VERSION ""

NS_ :

BS_:

BU_: WRCS SRS LECM3 LECM1 ECUspare6 CMS CIOM CCM AlcoLock2

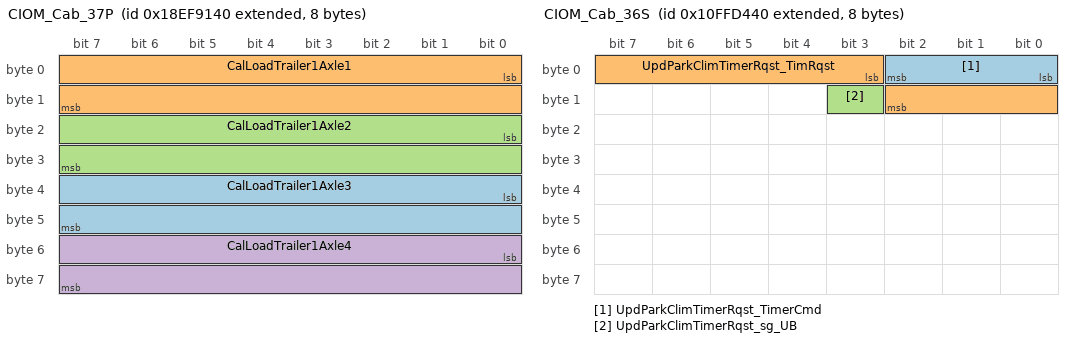
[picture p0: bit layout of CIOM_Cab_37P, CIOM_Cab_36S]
BO_ 2565837120 CIOM_Cab_37P: 8 CIOM
 SG_ CalLoadTrailer1Axle3 : 32|16@1+ (0.5,0) [0|32767.5] "kg"  WRCS
 SG_ CalLoadTrailer1Axle1 : 0|16@1+ (0.5,0) [0|32767.5] "kg"  WRCS
 SG_ CalLoadTrailer1Axle2 : 16|16@1+ (0.5,0) [0|32767.5] "kg"  WRCS
 SG_ CalLoadTrailer1Axle4 : 48|16@1+ (0.5,0) [0|32767.5] "kg"  WRCS

BO_ 2432685120 CIOM_Cab_36S: 8 CIOM
 SG_ UpdParkClimTimerRqst_TimerCmd : 0|3@1+ (1,0) [0|0] ""  CCM
 SG_ UpdParkClimTimerRqst_TimRqst : 3|8@1+ (1,0) [0|0] ""  CCM
 SG_ UpdParkClimTimerRqst_sg_UB : 11|1@1+ (1,0) [0|0] ""  CCM

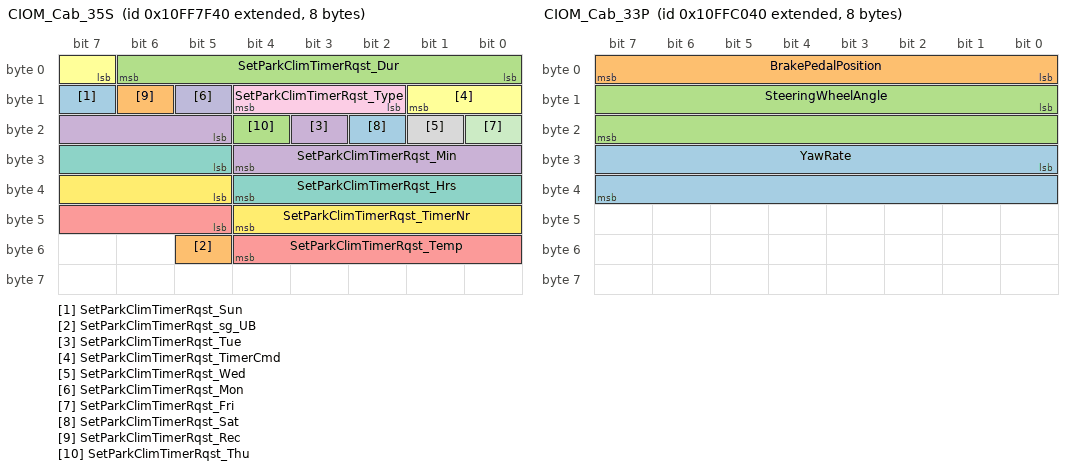
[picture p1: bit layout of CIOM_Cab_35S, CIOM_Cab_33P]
BO_ 2432663360 CIOM_Cab_35S: 8 CIOM
 SG_ SetParkClimTimerRqst_Sun : 15|1@1+ (1,0) [0|0] ""  CCM
 SG_ SetParkClimTimerRqst_sg_UB : 53|1@1+ (1,0) [0|0] ""  CCM
 SG_ SetParkClimTimerRqst_Dur : 0|7@1+ (1,0) [0|127] "min"  CCM
 SG_ SetParkClimTimerRqst_Tue : 19|1@1+ (1,0) [0|0] ""  CCM
 SG_ SetParkClimTimerRqst_Temp : 45|8@1+ (0.5,0) [0|127.5] "DegreeC"  CCM
 SG_ SetParkClimTimerRqst_TimerCmd : 7|3@1+ (1,0) [0|0] ""  CCM
 SG_ SetParkClimTimerRqst_Hrs : 29|8@1+ (1,0) [0|255] "h"  CCM
 SG_ SetParkClimTimerRqst_Wed : 17|1@1+ (1,0) [0|0] ""  CCM
 SG_ SetParkClimTimerRqst_Type : 10|3@1+ (1,0) [0|0] ""  CCM
 SG_ SetParkClimTimerRqst_Mon : 13|1@1+ (1,0) [0|0] ""  CCM
 SG_ SetParkClimTimerRqst_Fri : 16|1@1+ (1,0) [0|0] ""  CCM
 SG_ SetParkClimTimerRqst_TimerNr : 37|8@1+ (1,0) [0|0] ""  CCM
 SG_ SetParkClimTimerRqst_Sat : 18|1@1+ (1,0) [0|0] ""  CCM
 SG_ SetParkClimTimerRqst_Rec : 14|1@1+ (1,0) [0|0] ""  CCM
 SG_ SetParkClimTimerRqst_Thu : 20|1@1+ (1,0) [0|0] ""  CCM
 SG_ SetParkClimTimerRqst_Min : 21|8@1+ (1,0) [0|255] "min"  CCM

BO_ 2566357313 CIOM_Cab_34P_FCM: 8 SRS
 SG_ CIOM_Cab_34P_FCS : 0|64@1+ (1,0) [0|0] ""  CIOM

BO_ 2566357312 CIOM_Cab_34P: 21 CIOM
 SG_ GPSData_VehSpeed : 128|16@1+ (0.00390625,0) [0|255.99609375] "Km_per_h"  SRS
 SG_ GPSData_HDOP : 112|16@1+ (0.01,0) [0|655.35] ""  SRS
 SG_ GPSData_Direction : 96|16@1+ (0.0078125,0) [0|511.9921875] "deg"  SRS
 SG_ GPSData_Longitude : 0|32@1+ (1E-007,-210) [-210|219.4967295] "deg"  SRS
 SG_ GPSData_AntennaStat : 160|3@1+ (1,0) [0|0] ""  SRS
 SG_ GPSData_Latitude : 32|32@1+ (1E-007,-210) [-210|219.4967295] "deg"  SRS
 SG_ GPSData_sg_UB : 163|1@1+ (1,0) [0|1] ""  SRS
 SG_ GPSData_Altitude : 144|16@1+ (0.125,-2500) [-2500|5691.875] "m"  SRS
 SG_ GPSData_Time : 64|32@1+ (1,0) [0|4294967295] "s"  SRS

BO_ 2432680000 CIOM_Cab_33P: 8 CIOM
 SG_ YawRate : 24|16@1+ (0.000122,-3.92) [-3.92|4.07527] "Rad_per_s"  CMS
 SG_ BrakePedalPosition : 0|8@1+ (0.4,0) [0|102] "Percent"  SRS
 SG_ SteeringWheelAngle : 8|16@1+ (0.0009765625,-31.374) [-31.374|32.6250234375] "rad"  CMS,SRS

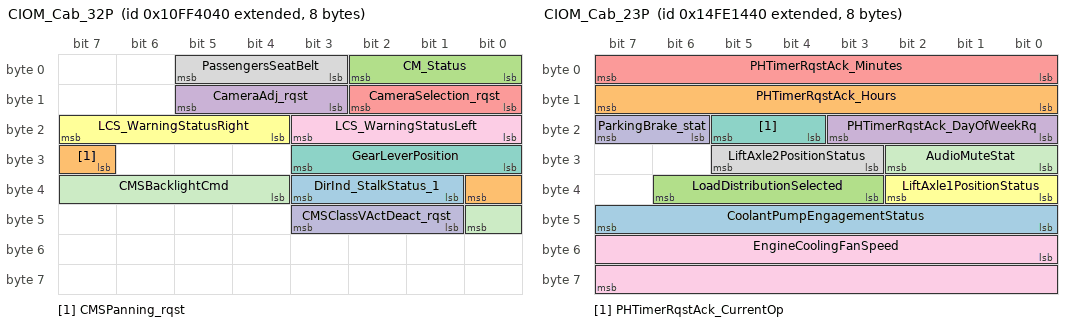
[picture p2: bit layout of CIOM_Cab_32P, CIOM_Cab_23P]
BO_ 2432647232 CIOM_Cab_32P: 8 CIOM
 SG_ DirInd_StalkStatus_1 : 33|3@1+ (1,0) [0|0] ""  CMS
 SG_ CMSPanning_rqst : 31|2@1+ (1,0) [0|0] ""  CMS
 SG_ CM_Status : 0|3@1+ (1,0) [0|0] ""  SRS
 SG_ CameraAdj_rqst : 11|3@1+ (1,0) [0|0] ""  CMS
 SG_ CameraSelection_rqst : 8|3@1+ (1,0) [0|0] ""  CMS
 SG_ LCS_WarningStatusRight : 20|4@1+ (1,0) [0|0] ""  CMS
 SG_ GearLeverPosition : 24|4@1+ (1,0) [0|0] ""  CMS
 SG_ PassengersSeatBelt : 3|3@1+ (1,0) [0|0] ""  SRS
 SG_ LCS_WarningStatusLeft : 16|4@1+ (1,0) [0|0] ""  CMS
 SG_ CMSClassVActDeact_rqst : 41|3@1+ (1,0) [0|0] ""  CMS
 SG_ CMSBacklightCmd : 36|5@1+ (1,0) [0|0] ""  CMS

BO_ 2516193600 CIOM_Cab_31P: 8 CIOM
 SG_ ReqHVILmonitoring : 48|2@1+ (1,0) [0|0] ""  CCM
 SG_ AuxTVSStatus : 56|3@1+ (1,0) [0|0] ""  CCM
 SG_ ActualDrvlnRetdrPercentTorque : 13|8@1+ (1,-125) [-125|130] "Percent"  SRS
 SG_ Trailer2LiftAxle2Pos : 32|2@1+ (1,0) [0|0] ""  WRCS
 SG_ Trailer3LiftAxle2Pos : 36|2@1+ (1,0) [0|0] ""  WRCS
 SG_ ROPBrakeControlActive : 10|2@1+ (1,0) [0|0] ""  SRS
 SG_ TransmissionDrivingMode : 59|3@1+ (1,0) [0|0] ""  CCM
 SG_ Trailer5LiftAxle1Pos : 42|2@1+ (1,0) [0|0] ""  WRCS
 SG_ Trailer1LiftAxle2Pos : 28|2@1+ (1,0) [0|0] ""  WRCS
 SG_ TVSDischargeRequest : 50|2@1+ (1,0) [0|0] ""  CCM
 SG_ FoundationBrakeUse : 8|2@1+ (1,0) [0|0] ""  SRS
 SG_ Trailer4LiftAxle1Pos : 38|2@1+ (1,0) [0|0] ""  WRCS
 SG_ Trailer5LiftAxle2Pos : 44|2@1+ (1,0) [0|0] ""  WRCS
 SG_ BlackPanel_stat : 46|2@1+ (1,0) [0|0] ""  CCM
 SG_ YCBrakeControlActive_UB : 23|1@1+ (1,0) [0|0] ""  SRS
 SG_ Trailer4LiftAxle2Pos : 40|2@1+ (1,0) [0|0] ""  WRCS
 SG_ AntiLockBrakingActive : 24|2@1+ (1,0) [0|0] ""  SRS
 SG_ YCBrakeControlActive : 21|2@1+ (1,0) [0|0] ""  SRS
 SG_ ActualEngineRetarderPercentTrq : 0|8@1+ (1,-125) [-125|130] "Percent"  SRS
 SG_ EngineTmpryStopStartStatus : 52|4@1+ (1,0) [0|0] ""  CCM
 SG_ Trailer1LiftAxle1Pos : 26|2@1+ (1,0) [0|0] ""  WRCS
 SG_ ROPBrakeControlActive_UB : 12|1@1+ (1,0) [0|0] ""  SRS
 SG_ Trailer3LiftAxle1Pos : 34|2@1+ (1,0) [0|0] ""  WRCS
 SG_ Trailer2LiftAxle1Pos : 30|2@1+ (1,0) [0|0] ""  WRCS

BO_ 2566357057 CIOM_Cab_30S_FCM: 8 LECM1
 SG_ CIOM_Cab_30S_FCS : 0|64@1+ (1,0) [0|0] ""  CIOM

BO_ 2566357056 CIOM_Cab_30S: 36 CIOM
 SG_ SEM_DisplayText_stat : 0|288@1+ (1,0) [0|0] ""  LECM1

BO_ 2432679745 CIOM_Cab_29S_FCM: 8 LECM1
 SG_ CIOM_Cab_29S_FCS : 0|64@1+ (1,0) [0|0] ""  CIOM

BO_ 2432679744 CIOM_Cab_29S: 98 CIOM
 SG_ MediaSourcesListRsp_SrcAttrib : 392|384@1+ (1,0) [0|0] ""  LECM1
 SG_ MediaSourcesListRsp_ItemID : 776|4@1+ (1,0) [0|0] ""  LECM1
 SG_ MediaSourcesListRsp_Name : 8|384@1+ (1,0) [0|0] ""  LECM1
 SG_ MediaSourcesListRsp_SInfo : 780|2@1+ (1,0) [0|0] ""  LECM1
 SG_ MediaSourcesListRsp_PCI : 0|8@1+ (1,0) [0|255] ""  LECM1
 SG_ MediaSourcesListRsp_sg_UB : 782|1@1+ (1,0) [0|0] ""  LECM1

BO_ 2432646976 CIOM_Cab_28S: 8 CIOM
 SG_ MediaSourcesListNPRsp : 0|8@1+ (1,0) [0|255] ""  LECM1
 SG_ MediaSourcesListNPRsp_UB : 8|1@1+ (1,0) [0|0] ""  LECM1

BO_ 2493989952 CIOM_Cab_27P: 8 CIOM
 SG_ SEMMediaSourceAvail_Source07 : 7|1@1+ (1,0) [0|0] ""  LECM1
 SG_ SEMMediaSourceAvail_Source06 : 6|1@1+ (1,0) [0|0] ""  LECM1
 SG_ AutoBlowerLevelRqst : 58|3@1+ (1,0) [0|0] ""  CCM
 SG_ SEMMediaSourceAvail_Source08 : 8|1@1+ (1,0) [0|0] ""  LECM1
 SG_ SEMMediaSourceAvail_Source00 : 0|1@1+ (1,0) [0|0] ""  LECM1
 SG_ SEM_AudioMuteStat : 20|3@1+ (1,0) [0|0] ""  LECM1
 SG_ SEMMediaSourceAvail_Source09 : 9|1@1+ (1,0) [0|0] ""  LECM1
 SG_ SEMMediaSourceAvail_Source13 : 13|1@1+ (1,0) [0|0] ""  LECM1
 SG_ SEMMediaSourceAvail_Source04 : 4|1@1+ (1,0) [0|0] ""  LECM1
 SG_ SEMMediaSourceAvail_Source05 : 5|1@1+ (1,0) [0|0] ""  LECM1
 SG_ SEMMediaSourceAvail_Source02 : 2|1@1+ (1,0) [0|0] ""  LECM1
 SG_ SEMMediaSourceAvail_SInfo : 14|2@1+ (1,0) [0|0] ""  LECM1
 SG_ AQSModeRqst : 52|3@1+ (1,0) [0|0] ""  CCM
 SG_ AudioSourceStat : 16|4@1+ (1,0) [0|0] ""  LECM1
 SG_ SEMMediaSourceAvail_Source11 : 11|1@1+ (1,0) [0|0] ""  LECM1
 SG_ SEMMediaSourceAvail_Source10 : 10|1@1+ (1,0) [0|0] ""  LECM1
 SG_ ACModeRqst : 61|3@1+ (1,0) [0|0] ""  CCM
 SG_ ESS_TRDStatus : 35|3@1+ (1,0) [0|0] ""  CCM
 SG_ AutoDefogModeRqst : 49|3@1+ (1,0) [0|0] ""  CCM
 SG_ SEM_AudioVolValIndCmd : 23|6@1+ (1,0) [0|63] "Step"  LECM1
 SG_ SEMMediaSourceAvail_Source01 : 1|1@1+ (1,0) [0|0] ""  LECM1
 SG_ EngineActiveStatus : 38|4@1+ (1,0) [0|0] ""  CCM
 SG_ SEMMediaSourceAvail_Source03 : 3|1@1+ (1,0) [0|0] ""  LECM1
 SG_ SEM_PresetIndicationCmd : 29|6@1+ (1,0) [0|63] "Enumeration"  LECM1
 SG_ SEMMediaSourceAvail_Source12 : 12|1@1+ (1,0) [0|0] ""  LECM1

BO_ 2499754560 CIOM_Cab_26P: 8 CIOM
 SG_ InhibitTVSReq : 58|3@1+ (1,0) [0|0] ""  CCM
 SG_ TipperEmergencyStopStatus : 36|3@1+ (1,0) [0|0] ""  WRCS
 SG_ TipperPrimaryBodyStatus : 40|3@1+ (1,0) [0|0] ""  WRCS
 SG_ TipperConditionsStatus : 2|2@1+ (1,0) [0|0] ""  WRCS
 SG_ TipperSecondaryBodyStatus : 43|3@1+ (1,0) [0|0] ""  WRCS
 SG_ BatterySOCAlert_rqst : 48|3@1+ (1,0) [0|0] ""  WRCS
 SG_ CCStates : 54|4@1+ (1,0) [0|0] ""  SRS
 SG_ ExtraHeating_rqst : 27|3@1+ (1,0) [0|0] ""  CCM
 SG_ LongMotionDirection : 51|3@1+ (1,0) [0|0] ""  SRS
 SG_ TipperUpDownStatus : 10|3@1+ (1,0) [0|0] ""  WRCS
 SG_ TipperTailGateStatus : 13|3@1+ (1,0) [0|0] ""  WRCS
 SG_ KneelingInformation : 32|4@1+ (1,0) [0|0] ""  WRCS
 SG_ TailLiftRemoteNotAllowed : 6|2@1+ (1,0) [0|0] ""  WRCS
 SG_ DirectionIndicatorActive_stat : 61|3@1+ (1,0) [0|0] ""  CMS
 SG_ TipperTarpaulinStatus : 16|3@1+ (1,0) [0|0] ""  WRCS
 SG_ TailLiftConditionsStatus : 4|2@1+ (1,0) [0|0] ""  WRCS
 SG_ InhibitWRCECSMenuCmd : 8|2@1+ (1,0) [0|0] ""  WRCS
 SG_ ShortStopHeater_status : 24|3@1+ (1,0) [0|0] ""  CCM
 SG_ LongMotionDirectionQual : 22|2@1+ (1,0) [0|0] ""  SRS
 SG_ TipperShakerStatus : 0|2@1+ (1,0) [0|0] ""  WRCS
 SG_ TailLiftMotionStatus : 19|3@1+ (1,0) [0|0] ""  WRCS

BO_ 2499679296 CIOM_Cab_23P: 8 CIOM
 SG_ CoolantPumpEngagementStatus : 40|8@1+ (0.4,0) [0|102] "Percent"  CCM
 SG_ PHTimerRqstAck_Hours : 8|8@1+ (1,0) [0|255] "h"  CCM
 SG_ LoadDistributionSelected : 35|4@1+ (1,0) [0|0] ""  WRCS
 SG_ PHTimerRqstAck_DayOfWeekRq : 16|4@1+ (1,0) [0|0] ""  CCM
 SG_ PHTimerRqstAck_Minutes : 0|8@1+ (1,0) [0|255] "min"  CCM
 SG_ LiftAxle1PositionStatus : 32|3@1+ (1,0) [0|0] ""  WRCS
 SG_ PHTimerRqstAck_CurrentOp : 20|2@1+ (1,0) [0|0] ""  CCM
 SG_ LiftAxle2PositionStatus : 27|3@1+ (1,0) [0|0] ""  WRCS
 SG_ EngineCoolingFanSpeed : 48|16@1+ (1,0) [0|65535] "rpm"  CCM
 SG_ ParkingBrake_stat : 22|2@1+ (1,0) [0|0] ""  WRCS
 SG_ AudioMuteStat : 24|3@1+ (1,0) [0|0] ""  LECM3,LECM1

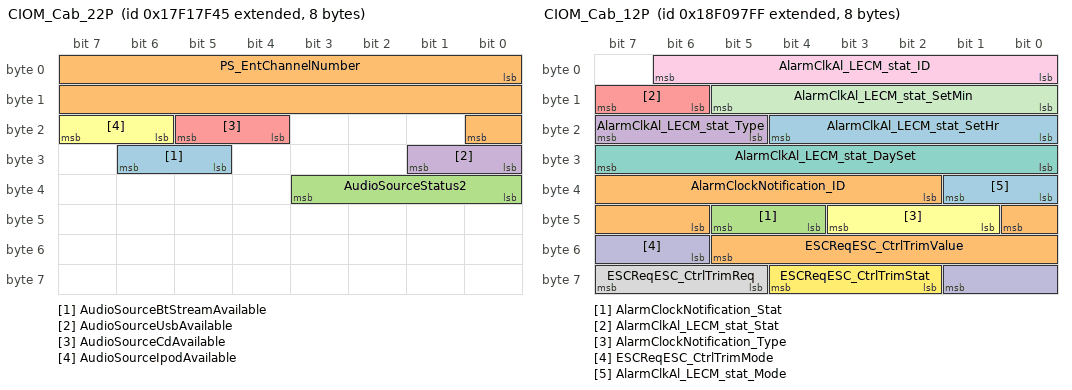
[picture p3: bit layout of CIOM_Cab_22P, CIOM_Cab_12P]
BO_ 2549186373 CIOM_Cab_22P: 8 CIOM
 SG_ AudioSourceBtStreamAvailable : 29|2@1+ (1,0) [0|0] ""  LECM1
 SG_ PS_EntChannelNumber : 0|17@1+ (1,0) [0|131071] "Not Available"  LECM3
 SG_ AudioSourceStatus2 : 32|4@1+ (1,0) [0|0] ""  LECM1
 SG_ AudioSourceUsbAvailable : 24|2@1+ (1,0) [0|0] ""  LECM1
 SG_ AudioSourceCdAvailable : 20|2@1+ (1,0) [0|0] ""  LECM1
 SG_ AudioSourceIpodAvailable : 22|2@1+ (1,0) [0|0] ""  LECM1

BO_ 2566864832 CIOM_Cab_20S_FCM: 8 LECM1
 SG_ CIOM_Cab_20S_FCS : 0|64@1+ (1,0) [0|0] ""  CIOM

BO_ 2566864831 CIOM_Cab_20S: 36 CIOM
 SG_ DisplayText_stat : 0|288@1+ (1,0) [0|0] ""  LECM1

BO_ 2565974016 CIOM_Cab_13S_FCM: 8 WRCS
 SG_ CIOM_Cab_13S_FCS : 0|64@1+ (1,0) [0|0] ""  CIOM

BO_ 2565974015 CIOM_Cab_13S: 128 CIOM
 SG_ FdEquipmentFreeText : 0|1024@1+ (1,0) [0|0] ""  WRCS

BO_ 2565904383 CIOM_Cab_12P: 8 CIOM
 SG_ AlarmClkAl_LECM_stat_SetHr : 16|5@1+ (1,0) [0|31] "h"  LECM1
 SG_ ESCReqESC_CtrlTrimValue : 46|8@1+ (10,0) [0|2550] ""  WRCS
 SG_ AlarmClockNotification_Stat : 44|2@1+ (1,0) [0|0] ""  LECM1
 SG_ AlarmClkAl_LECM_stat_Type : 21|3@1+ (1,0) [0|0] ""  LECM1
 SG_ AlarmClkAl_LECM_stat_Stat : 14|2@1+ (1,0) [0|0] ""  LECM1
 SG_ AlarmClockNotification_Type : 41|3@1+ (1,0) [0|0] ""  LECM1
 SG_ AlarmClkAl_LECM_stat_DaySet : 24|8@1+ (1,0) [0|255] ""  LECM1
 SG_ ESCReqESC_CtrlTrimReq : 61|3@1+ (1,0) [0|0] ""  WRCS
 SG_ AlarmClkAl_LECM_stat_ID : 0|7@1+ (1,0) [0|0] ""  LECM1
 SG_ ESCReqESC_CtrlTrimMode : 54|4@1+ (1,0) [0|0] ""  WRCS
 SG_ AlarmClkAl_LECM_stat_SetMin : 8|6@1+ (1,0) [0|63] "min"  LECM1
 SG_ ESCReqESC_CtrlTrimStat : 58|3@1+ (1,0) [0|0] ""  WRCS
 SG_ AlarmClkAl_LECM_stat_Mode : 32|2@1+ (1,0) [0|0] ""  LECM1
 SG_ AlarmClockNotification_ID : 34|7@1+ (1,0) [0|0] ""  LECM1

BO_ 2565834752 CIOM_Cab_11S_FCM: 8 SRS
 SG_ CIOM_Cab_11S_FCS : 0|64@1+ (1,0) [0|0] ""  CIOM

BO_ 2565834751 CIOM_Cab_11S: 11 CIOM
 SG_ ECUVIN_stat : 0|88@1+ (1,0) [0|0] ""  SRS

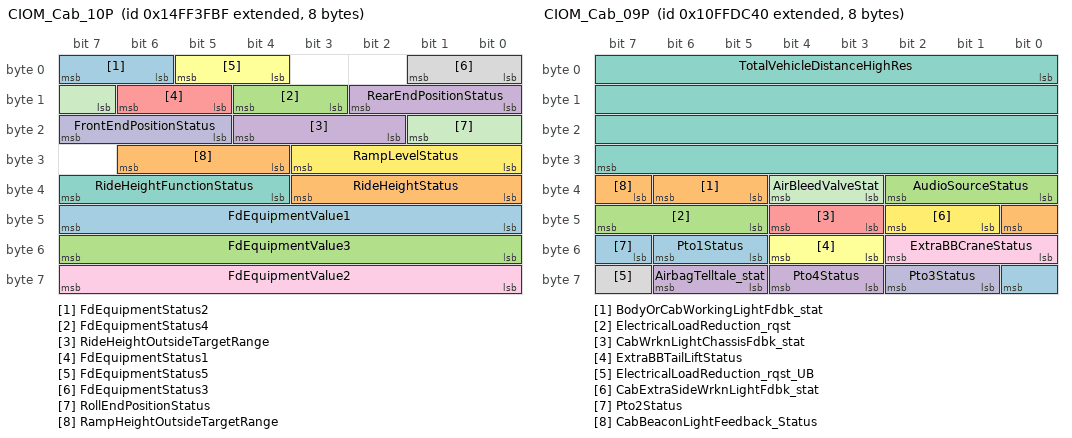
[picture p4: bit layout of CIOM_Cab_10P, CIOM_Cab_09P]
BO_ 2499755967 CIOM_Cab_10P: 8 CIOM
 SG_ FdEquipmentStatus2 : 6|2@1+ (1,0) [0|0] ""  WRCS
 SG_ RideHeightStatus : 32|4@1+ (1,0) [0|0] ""  WRCS
 SG_ FdEquipmentStatus4 : 11|2@1+ (1,0) [0|0] ""  WRCS
 SG_ RideHeightOutsideTargetRange : 18|3@1+ (1,0) [0|0] ""  WRCS
 SG_ FdEquipmentStatus1 : 13|2@1+ (1,0) [0|0] ""  WRCS
 SG_ FdEquipmentStatus5 : 4|2@1+ (1,0) [0|0] ""  WRCS
 SG_ RideHeightFunctionStatus : 36|4@1+ (1,0) [0|0] ""  WRCS
 SG_ FdEquipmentStatus3 : 0|2@1+ (1,0) [0|0] ""  WRCS
 SG_ FdEquipmentValue2 : 56|8@1+ (0.5,0) [0|127.5] "Percent"  WRCS
 SG_ FrontEndPositionStatus : 21|3@1+ (1,0) [0|0] ""  WRCS
 SG_ RollEndPositionStatus : 15|3@1+ (1,0) [0|0] ""  WRCS
 SG_ RampLevelStatus : 24|4@1+ (1,0) [0|0] ""  WRCS
 SG_ FdEquipmentValue1 : 40|8@1+ (0.5,0) [0|127.5] "Percent"  WRCS
 SG_ RampHeightOutsideTargetRange : 28|3@1+ (1,0) [0|0] ""  WRCS
 SG_ FdEquipmentValue3 : 48|8@1+ (0.5,0) [0|127.5] "Percent"  WRCS
 SG_ RearEndPositionStatus : 8|3@1+ (1,0) [0|0] ""  WRCS

BO_ 2432687168 CIOM_Cab_09P: 8 CIOM
 SG_ Pto1Status : 53|2@1+ (1,0) [0|0] ""  WRCS
 SG_ BodyOrCabWorkingLightFdbk_stat : 37|2@1+ (1,0) [0|0] ""  WRCS
 SG_ ElectricalLoadReduction_rqst : 45|3@1+ (1,0) [0|0] ""  CCM,WRCS
 SG_ AirbagTelltale_stat : 61|2@1+ (1,0) [0|0] ""  SRS
 SG_ CabWrknLightChassisFdbk_stat : 43|2@1+ (1,0) [0|0] ""  WRCS
 SG_ ExtraBBTailLiftStatus : 51|2@1+ (1,0) [0|0] ""  WRCS
 SG_ TotalVehicleDistanceHighRes : 0|32@1+ (5,0) [0|21474836475] "m"  LECM3,CMS,SRS,LECM1,WRCS,CCM
 SG_ ElectricalLoadReduction_rqst_UB : 63|1@1+ (1,0) [0|0] ""  CCM,WRCS
 SG_ ExtraBBCraneStatus : 48|3@1+ (1,0) [0|0] ""  WRCS
 SG_ Pto3Status : 57|2@1+ (1,0) [0|0] ""  WRCS
 SG_ AirBleedValveStat : 35|2@1+ (1,0) [0|0] ""  CCM
 SG_ CabExtraSideWrknLightFdbk_stat : 41|2@1+ (1,0) [0|0] ""  WRCS
 SG_ Pto2Status : 55|2@1+ (1,0) [0|0] ""  WRCS
 SG_ CabBeaconLightFeedback_Status : 39|2@1+ (1,0) [0|0] ""  WRCS
 SG_ AudioSourceStatus : 32|3@1+ (1,0) [0|0] ""  LECM1
 SG_ Pto4Status : 59|2@1+ (1,0) [0|0] ""  WRCS

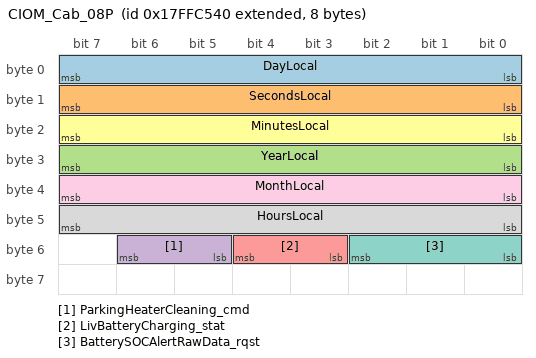
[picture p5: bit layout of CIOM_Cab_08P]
BO_ 2550121792 CIOM_Cab_08P: 8 CIOM
 SG_ DayLocal : 0|8@1+ (0.25,0) [0|63.75] "Days"  CCM
 SG_ SecondsLocal : 8|8@1+ (0.25,0) [0|63.75] "s"  CCM
 SG_ YearLocal : 24|8@1+ (1,1985) [1985|2240] "Years"  CCM
 SG_ ParkingHeaterCleaning_cmd : 53|2@1+ (1,0) [0|0] ""  CCM
 SG_ LivBatteryCharging_stat : 51|2@1+ (1,0) [0|0] ""  CCM
 SG_ MinutesLocal : 16|8@1+ (1,0) [0|255] "min"  CCM,LECM1
 SG_ BatterySOCAlertRawData_rqst : 48|3@1+ (1,0) [0|0] ""  CCM
 SG_ HoursLocal : 40|8@1+ (1,0) [0|255] "h"  CCM,LECM1
 SG_ MonthLocal : 32|8@1+ (1,0) [0|255] "Months"  CCM

CM_ SG_ 2565837120 CalLoadTrailer1Axle3 "65024 - 65279 Error ; 65280 - 65535 Not available";
CM_ SG_ 2565837120 CalLoadTrailer1Axle1 "65024 - 65279 Error ; 65280 - 65535 Not available";
CM_ SG_ 2565837120 CalLoadTrailer1Axle2 "65024 - 65279 Error ; 65280 - 65535 Not available";
CM_ SG_ 2565837120 CalLoadTrailer1Axle4 "65024 - 65279 Error ; 65280 - 65535 Not available";
CM_ SG_ 2566357312 GPSData_VehSpeed "65024 - 65279 Error ; 65280 - 65535 Not available";
CM_ SG_ 2566357312 GPSData_Longitude "4261412864-4278190079 Error ; 4278190080-4294967295 Not available";
CM_ SG_ 2566357312 GPSData_Latitude "4261412864-4278190079 Error ; 4278190080-4294967295 Not available";
CM_ SG_ 2566357312 GPSData_Time "4261412864 - 4278190079 Error ; 4278190080 - 4294967295 Not available";
CM_ SG_ 2432680000 YawRate "65024 - 65279 Error ; 65280 - 65535 Not available";
CM_ SG_ 2432680000 BrakePedalPosition "254 Error ; 255 Not available";
CM_ SG_ 2432680000 SteeringWheelAngle "65024 - 65279 Error ; 65280 - 65535 Not available";
CM_ SG_ 2516193600 ActualDrvlnRetdrPercentTorque "254 Error ; 255 Not available";
CM_ SG_ 2516193600 ActualEngineRetarderPercentTrq "254 Error ; 255 Not available";
CM_ SG_ 2565904383 ESCReqESC_CtrlTrimValue "254 Error ; 255 Not available";
CM_ SG_ 2499755967 FdEquipmentValue2 "254 Error ; 255 Not available";
CM_ SG_ 2499755967 FdEquipmentValue1 "254 Error ; 255 Not available";
CM_ SG_ 2499755967 FdEquipmentValue3 "254 Error ; 255 Not available";
CM_ SG_ 2432687168 TotalVehicleDistanceHighRes "4261412864 - 4278190079 Error ; 4278190080 - 4294967295 Not available";
CM_ SG_ 2550121792 DayLocal "254 Error ; 255 Not available";
CM_ SG_ 2550121792 SecondsLocal "254 Error ; 255 Not available";
CM_ SG_ 2550121792 YearLocal "254 Error ; 255 Not available";
CM_ SG_ 2550121792 MinutesLocal "254 Error ; 255 Not available";
CM_ SG_ 2550121792 HoursLocal "254 Error ; 255 Not available";
CM_ SG_ 2550121792 MonthLocal "254 Error ; 255 Not available";
BA_DEF_ BO_  "GenMsgStartDelayTime" INT 0 0;
BA_DEF_ BO_  "GenMsgDelayTime" INT 0 0;
BA_DEF_ BO_  "GenMsgCycleTime" INT 0 0;
BA_DEF_ BO_  "GenMsgSendType" ENUM  "Cyclic","NotUsed","NotUsed","NotUsed","NotUsed","NotUsed","NotUsed","IfActive","NoMsgSendType","NotUsed";
BA_DEF_ SG_  "GenSigStartValue" INT 0 0;
BA_DEF_ SG_  "GenSigCycleTimeActive" INT 0 0;
BA_DEF_ SG_  "GenSigCycleTime" INT 0 0;
BA_DEF_ SG_  "GenSigSendType" ENUM  "Cyclic","OnWrite","OnWriteWithRepetition","OnChange","OnChangeWithRepetition","IfActive","IfActiveWithRepetition","NoSigSendType","NotUsed","NotUsed","NotUsed","NotUsed","NotUsed";
BA_DEF_ BO_  "VFrameFormat" ENUM  "StandardCAN","ExtendedCAN","reserved","J1939PG","reserved","reserved","reserved","reserved","reserved","reserved","reserved","reserved","reserved","reserved","StandardCAN_FD","ExtendedCAN_FD";
BA_DEF_ SG_  "SigType" ENUM  "Default","Range","RangeSigned","ASCII","Discrete","Control","ReferencePGN","DTC","StringDelimiter","StringLength","StringLengthControl";
BA_DEF_ SG_  "SeToolVersion_SIGNAL" STRING ;
BA_DEF_ SG_  "SeToolUniqueID_SIGNAL" STRING ;
BA_DEF_ SG_  "SeToolOwnerSigGroup_SIGNAL" STRING ;
BA_DEF_ SG_  "SeToolOwnerSigGroupID_SIGNAL" STRING ;
BA_DEF_ SG_  "SeToolName_SIGNAL" STRING ;
BA_DEF_ SG_  "SeToolItemID_SIGNAL" STRING ;
BA_DEF_ SG_  "SeToolAncestorID_SIGNAL" STRING ;
BA_DEF_ SG_  "Platform_VMCU1_Sig" ENUM  "No","Yes";
BA_DEF_ BO_  "NmAsrMessage" ENUM  "No","Yes";
BA_DEF_ SG_  "NeedsUpdateBit" ENUM  "No","Yes";
BA_DEF_ SG_  "MmAnSignal" ENUM  "No","Yes";
BA_DEF_ SG_  "GenSigMaxLatency" INT 0 65535;
BA_DEF_ SG_  "GenSigILSupport" ENUM  "Yes","No";
BA_DEF_ BO_  "GenMsgILSupport" ENUM  "No","Yes";
BA_DEF_ SG_  "E2EProfile" STRING ;
BA_DEF_ SG_  "E2EDataLength" INT 0 65535;
BA_DEF_ SG_  "E2EDataId" INT 0 65535;
BA_DEF_ BO_  "DiagUUDTResponse" ENUM  "No","Yes";
BA_DEF_ BO_  "DiagState" ENUM  "No","Yes";
BA_DEF_ BO_  "DiagResponse" ENUM  "No","Yes";
BA_DEF_ BO_  "DiagRequest" ENUM  "No","Yes";
BA_DEF_ BO_  "DiagConnection" HEX 0 65535;
BA_DEF_ BO_  "CanTpSTmin" INT 0 255;
BA_DEF_ BO_  "CanTpFcFrameId" HEX 0 2147483647;
BA_DEF_ BO_  "CanTpBs" INT 0 255;
BA_DEF_REL_ BU_SG_REL_  "GenSigTimeoutTime" INT 0 65535;
BA_DEF_REL_ BU_SG_REL_  "GenSigFirstTimeoutTime" INT 0 65535;
BA_DEF_DEF_  "GenMsgStartDelayTime" 0;
BA_DEF_DEF_  "GenMsgDelayTime" 0;
BA_DEF_DEF_  "GenMsgCycleTime" 0;
BA_DEF_DEF_  "GenMsgSendType" "Cyclic";
BA_DEF_DEF_  "GenSigStartValue" 0;
BA_DEF_DEF_  "GenSigCycleTimeActive" 0;
BA_DEF_DEF_  "GenSigCycleTime" 0;
BA_DEF_DEF_  "GenSigSendType" "Cyclic";
BA_DEF_DEF_  "VFrameFormat" "ExtendedCAN";
BA_DEF_DEF_  "SigType" "Default";
BA_DEF_DEF_  "SeToolVersion_SIGNAL" "";
BA_DEF_DEF_  "SeToolUniqueID_SIGNAL" "";
BA_DEF_DEF_  "SeToolOwnerSigGroup_SIGNAL" "";
BA_DEF_DEF_  "SeToolOwnerSigGroupID_SIGNAL" "";
BA_DEF_DEF_  "SeToolName_SIGNAL" "";
BA_DEF_DEF_  "SeToolItemID_SIGNAL" "";
BA_DEF_DEF_  "SeToolAncestorID_SIGNAL" "";
BA_DEF_DEF_  "Platform_VMCU1_Sig" "No";
BA_DEF_DEF_  "NmAsrMessage" "No";
BA_DEF_DEF_  "NeedsUpdateBit" "No";
BA_DEF_DEF_  "MmAnSignal" "No";
BA_DEF_DEF_  "GenSigMaxLatency" 0;
BA_DEF_DEF_  "GenSigILSupport" "Yes";
BA_DEF_DEF_  "GenMsgILSupport" "Yes";
BA_DEF_DEF_  "E2EProfile" "none";
BA_DEF_DEF_  "E2EDataLength" 0;
BA_DEF_DEF_  "E2EDataId" 0;
BA_DEF_DEF_  "DiagUUDTResponse" "No";
BA_DEF_DEF_  "DiagState" "No";
BA_DEF_DEF_  "DiagResponse" "No";
BA_DEF_DEF_  "DiagRequest" "No";
BA_DEF_DEF_  "DiagConnection" 0;
BA_DEF_DEF_  "CanTpSTmin" 0;
BA_DEF_DEF_  "CanTpFcFrameId" 2147483647;
BA_DEF_DEF_  "CanTpBs" 255;
BA_DEF_DEF_REL_ "GenSigTimeoutTime" 0;
BA_DEF_DEF_REL_ "GenSigFirstTimeoutTime" 0;
BA_ "GenMsgCycleTime" BO_ 2565837120 1000;
BA_ "GenMsgStartDelayTime" BO_ 2565837120 20;
BA_ "GenMsgSendType" BO_ 2432685120 8;
BA_ "GenMsgDelayTime" BO_ 2432685120 20;
BA_ "GenMsgSendType" BO_ 2432663360 8;
BA_ "GenMsgDelayTime" BO_ 2432663360 20;
BA_ "GenMsgILSupport" BO_ 2566357313 0;
BA_ "GenMsgSendType" BO_ 2566357313 8;
BA_ "CanTpFcFrameId" BO_ 2566357312 418873665;
BA_ "GenMsgCycleTime" BO_ 2566357312 500;
BA_ "GenMsgStartDelayTime" BO_ 2566357312 50;
BA_ "GenMsgCycleTime" BO_ 2432680000 10;
BA_ "GenMsgStartDelayTime" BO_ 2432680000 5;
BA_ "GenMsgCycleTime" BO_ 2432647232 20;
BA_ "GenMsgCycleTime" BO_ 2516193600 100;
BA_ "GenMsgILSupport" BO_ 2566357057 0;
BA_ "GenMsgSendType" BO_ 2566357057 8;
BA_ "CanTpFcFrameId" BO_ 2566357056 418873409;
BA_ "GenMsgSendType" BO_ 2566357056 8;
BA_ "GenMsgDelayTime" BO_ 2566357056 150;
BA_ "GenMsgILSupport" BO_ 2432679745 0;
BA_ "GenMsgSendType" BO_ 2432679745 8;
BA_ "CanTpFcFrameId" BO_ 2432679744 285196097;
BA_ "GenMsgSendType" BO_ 2432679744 8;
BA_ "GenMsgDelayTime" BO_ 2432679744 50;
BA_ "GenMsgSendType" BO_ 2432646976 8;
BA_ "GenMsgDelayTime" BO_ 2432646976 20;
BA_ "GenMsgCycleTime" BO_ 2493989952 50;
BA_ "GenMsgStartDelayTime" BO_ 2493989952 25;
BA_ "GenMsgCycleTime" BO_ 2499754560 50;
BA_ "GenMsgCycleTime" BO_ 2499679296 50;
BA_ "GenMsgStartDelayTime" BO_ 2499679296 10;
BA_ "GenMsgCycleTime" BO_ 2549186373 150;
BA_ "GenMsgStartDelayTime" BO_ 2549186373 15;
BA_ "GenMsgILSupport" BO_ 2566864832 0;
BA_ "GenMsgSendType" BO_ 2566864832 8;
BA_ "CanTpFcFrameId" BO_ 2566864831 419381184;
BA_ "GenMsgSendType" BO_ 2566864831 8;
BA_ "GenMsgDelayTime" BO_ 2566864831 200;
BA_ "GenMsgStartDelayTime" BO_ 2566864831 50;
BA_ "GenMsgILSupport" BO_ 2565974016 0;
BA_ "GenMsgSendType" BO_ 2565974016 8;
BA_ "CanTpFcFrameId" BO_ 2565974015 418490368;
BA_ "GenMsgSendType" BO_ 2565974015 8;
BA_ "GenMsgDelayTime" BO_ 2565974015 200;
BA_ "GenMsgCycleTime" BO_ 2565904383 150;
BA_ "GenMsgStartDelayTime" BO_ 2565904383 75;
BA_ "CanTpSTmin" BO_ 2565834752 1;
BA_ "GenMsgILSupport" BO_ 2565834752 0;
BA_ "GenMsgSendType" BO_ 2565834752 8;
BA_ "CanTpFcFrameId" BO_ 2565834751 418351104;
BA_ "CanTpSTmin" BO_ 2565834751 5;
BA_ "GenMsgSendType" BO_ 2565834751 8;
BA_ "GenMsgDelayTime" BO_ 2565834751 100;
BA_ "GenMsgCycleTime" BO_ 2499755967 50;
BA_ "GenMsgStartDelayTime" BO_ 2499755967 5;
BA_ "GenMsgCycleTime" BO_ 2432687168 20;
BA_ "GenMsgStartDelayTime" BO_ 2432687168 5;
BA_ "GenMsgCycleTime" BO_ 2550121792 250;
BA_ "GenMsgStartDelayTime" BO_ 2550121792 25;
BA_ "GenSigCycleTime" SG_ 2565837120 CalLoadTrailer1Axle3 100;
BA_ "GenSigCycleTimeActive" SG_ 2565837120 CalLoadTrailer1Axle3 100;
BA_ "GenSigStartValue" SG_ 2565837120 CalLoadTrailer1Axle3 65535;
BA_ "GenSigMaxLatency" SG_ 2565837120 CalLoadTrailer1Axle3 1001;
BA_ "GenSigCycleTime" SG_ 2565837120 CalLoadTrailer1Axle1 100;
BA_ "GenSigCycleTimeActive" SG_ 2565837120 CalLoadTrailer1Axle1 100;
BA_ "GenSigStartValue" SG_ 2565837120 CalLoadTrailer1Axle1 65535;
BA_ "GenSigMaxLatency" SG_ 2565837120 CalLoadTrailer1Axle1 1001;
BA_ "GenSigCycleTime" SG_ 2565837120 CalLoadTrailer1Axle2 100;
BA_ "GenSigCycleTimeActive" SG_ 2565837120 CalLoadTrailer1Axle2 100;
BA_ "GenSigStartValue" SG_ 2565837120 CalLoadTrailer1Axle2 65535;
BA_ "GenSigMaxLatency" SG_ 2565837120 CalLoadTrailer1Axle2 1001;
BA_ "GenSigCycleTime" SG_ 2565837120 CalLoadTrailer1Axle4 100;
BA_ "GenSigCycleTimeActive" SG_ 2565837120 CalLoadTrailer1Axle4 100;
BA_ "GenSigStartValue" SG_ 2565837120 CalLoadTrailer1Axle4 65535;
BA_ "GenSigMaxLatency" SG_ 2565837120 CalLoadTrailer1Axle4 1001;
BA_ "GenSigSendType" SG_ 2432685120 UpdParkClimTimerRqst_TimerCmd 1;
BA_ "GenSigCycleTime" SG_ 2432685120 UpdParkClimTimerRqst_TimerCmd 100;
BA_ "GenSigCycleTimeActive" SG_ 2432685120 UpdParkClimTimerRqst_TimerCmd 100;
BA_ "GenSigStartValue" SG_ 2432685120 UpdParkClimTimerRqst_TimerCmd 7;
BA_ "GenSigMaxLatency" SG_ 2432685120 UpdParkClimTimerRqst_TimerCmd 20;
BA_ "NeedsUpdateBit" SG_ 2432685120 UpdParkClimTimerRqst_TimerCmd 1;
BA_ "GenSigSendType" SG_ 2432685120 UpdParkClimTimerRqst_TimRqst 1;
BA_ "GenSigCycleTime" SG_ 2432685120 UpdParkClimTimerRqst_TimRqst 100;
BA_ "GenSigCycleTimeActive" SG_ 2432685120 UpdParkClimTimerRqst_TimRqst 100;
BA_ "GenSigStartValue" SG_ 2432685120 UpdParkClimTimerRqst_TimRqst 255;
BA_ "GenSigMaxLatency" SG_ 2432685120 UpdParkClimTimerRqst_TimRqst 20;
BA_ "NeedsUpdateBit" SG_ 2432685120 UpdParkClimTimerRqst_TimRqst 1;
BA_ "GenSigSendType" SG_ 2432685120 UpdParkClimTimerRqst_sg_UB 7;
BA_ "GenSigSendType" SG_ 2432663360 SetParkClimTimerRqst_Sun 1;
BA_ "GenSigCycleTime" SG_ 2432663360 SetParkClimTimerRqst_Sun 100;
BA_ "GenSigCycleTimeActive" SG_ 2432663360 SetParkClimTimerRqst_Sun 100;
BA_ "GenSigMaxLatency" SG_ 2432663360 SetParkClimTimerRqst_Sun 20;
BA_ "NeedsUpdateBit" SG_ 2432663360 SetParkClimTimerRqst_Sun 1;
BA_ "GenSigSendType" SG_ 2432663360 SetParkClimTimerRqst_sg_UB 7;
BA_ "GenSigSendType" SG_ 2432663360 SetParkClimTimerRqst_Dur 1;
BA_ "GenSigCycleTime" SG_ 2432663360 SetParkClimTimerRqst_Dur 100;
BA_ "GenSigCycleTimeActive" SG_ 2432663360 SetParkClimTimerRqst_Dur 100;
BA_ "GenSigStartValue" SG_ 2432663360 SetParkClimTimerRqst_Dur 127;
BA_ "GenSigMaxLatency" SG_ 2432663360 SetParkClimTimerRqst_Dur 20;
BA_ "NeedsUpdateBit" SG_ 2432663360 SetParkClimTimerRqst_Dur 1;
BA_ "GenSigSendType" SG_ 2432663360 SetParkClimTimerRqst_Tue 1;
BA_ "GenSigCycleTime" SG_ 2432663360 SetParkClimTimerRqst_Tue 100;
BA_ "GenSigCycleTimeActive" SG_ 2432663360 SetParkClimTimerRqst_Tue 100;
BA_ "GenSigMaxLatency" SG_ 2432663360 SetParkClimTimerRqst_Tue 20;
BA_ "NeedsUpdateBit" SG_ 2432663360 SetParkClimTimerRqst_Tue 1;
BA_ "GenSigSendType" SG_ 2432663360 SetParkClimTimerRqst_Temp 1;
BA_ "GenSigCycleTime" SG_ 2432663360 SetParkClimTimerRqst_Temp 100;
BA_ "GenSigCycleTimeActive" SG_ 2432663360 SetParkClimTimerRqst_Temp 100;
BA_ "GenSigStartValue" SG_ 2432663360 SetParkClimTimerRqst_Temp 255;
BA_ "GenSigMaxLatency" SG_ 2432663360 SetParkClimTimerRqst_Temp 20;
BA_ "NeedsUpdateBit" SG_ 2432663360 SetParkClimTimerRqst_Temp 1;
BA_ "GenSigSendType" SG_ 2432663360 SetParkClimTimerRqst_TimerCmd 1;
BA_ "GenSigCycleTime" SG_ 2432663360 SetParkClimTimerRqst_TimerCmd 100;
BA_ "GenSigCycleTimeActive" SG_ 2432663360 SetParkClimTimerRqst_TimerCmd 100;
BA_ "GenSigStartValue" SG_ 2432663360 SetParkClimTimerRqst_TimerCmd 7;
BA_ "GenSigMaxLatency" SG_ 2432663360 SetParkClimTimerRqst_TimerCmd 20;
BA_ "NeedsUpdateBit" SG_ 2432663360 SetParkClimTimerRqst_TimerCmd 1;
BA_ "GenSigSendType" SG_ 2432663360 SetParkClimTimerRqst_Hrs 1;
BA_ "GenSigCycleTime" SG_ 2432663360 SetParkClimTimerRqst_Hrs 100;
BA_ "GenSigCycleTimeActive" SG_ 2432663360 SetParkClimTimerRqst_Hrs 100;
BA_ "GenSigStartValue" SG_ 2432663360 SetParkClimTimerRqst_Hrs 255;
BA_ "GenSigMaxLatency" SG_ 2432663360 SetParkClimTimerRqst_Hrs 20;
BA_ "NeedsUpdateBit" SG_ 2432663360 SetParkClimTimerRqst_Hrs 1;
BA_ "GenSigSendType" SG_ 2432663360 SetParkClimTimerRqst_Wed 1;
BA_ "GenSigCycleTime" SG_ 2432663360 SetParkClimTimerRqst_Wed 100;
BA_ "GenSigCycleTimeActive" SG_ 2432663360 SetParkClimTimerRqst_Wed 100;
BA_ "GenSigMaxLatency" SG_ 2432663360 SetParkClimTimerRqst_Wed 20;
BA_ "NeedsUpdateBit" SG_ 2432663360 SetParkClimTimerRqst_Wed 1;
BA_ "GenSigSendType" SG_ 2432663360 SetParkClimTimerRqst_Type 1;
BA_ "GenSigCycleTime" SG_ 2432663360 SetParkClimTimerRqst_Type 100;
BA_ "GenSigCycleTimeActive" SG_ 2432663360 SetParkClimTimerRqst_Type 100;
BA_ "GenSigStartValue" SG_ 2432663360 SetParkClimTimerRqst_Type 7;
BA_ "GenSigMaxLatency" SG_ 2432663360 SetParkClimTimerRqst_Type 20;
BA_ "NeedsUpdateBit" SG_ 2432663360 SetParkClimTimerRqst_Type 1;
BA_ "GenSigSendType" SG_ 2432663360 SetParkClimTimerRqst_Mon 1;
BA_ "GenSigCycleTime" SG_ 2432663360 SetParkClimTimerRqst_Mon 100;
BA_ "GenSigCycleTimeActive" SG_ 2432663360 SetParkClimTimerRqst_Mon 100;
BA_ "GenSigMaxLatency" SG_ 2432663360 SetParkClimTimerRqst_Mon 20;
BA_ "NeedsUpdateBit" SG_ 2432663360 SetParkClimTimerRqst_Mon 1;
BA_ "GenSigSendType" SG_ 2432663360 SetParkClimTimerRqst_Fri 1;
BA_ "GenSigCycleTime" SG_ 2432663360 SetParkClimTimerRqst_Fri 100;
BA_ "GenSigCycleTimeActive" SG_ 2432663360 SetParkClimTimerRqst_Fri 100;
BA_ "GenSigMaxLatency" SG_ 2432663360 SetParkClimTimerRqst_Fri 20;
BA_ "NeedsUpdateBit" SG_ 2432663360 SetParkClimTimerRqst_Fri 1;
BA_ "GenSigSendType" SG_ 2432663360 SetParkClimTimerRqst_TimerNr 1;
BA_ "GenSigCycleTime" SG_ 2432663360 SetParkClimTimerRqst_TimerNr 100;
BA_ "GenSigCycleTimeActive" SG_ 2432663360 SetParkClimTimerRqst_TimerNr 100;
BA_ "GenSigStartValue" SG_ 2432663360 SetParkClimTimerRqst_TimerNr 255;
BA_ "GenSigMaxLatency" SG_ 2432663360 SetParkClimTimerRqst_TimerNr 20;
BA_ "NeedsUpdateBit" SG_ 2432663360 SetParkClimTimerRqst_TimerNr 1;
BA_ "GenSigSendType" SG_ 2432663360 SetParkClimTimerRqst_Sat 1;
BA_ "GenSigCycleTime" SG_ 2432663360 SetParkClimTimerRqst_Sat 100;
BA_ "GenSigCycleTimeActive" SG_ 2432663360 SetParkClimTimerRqst_Sat 100;
BA_ "GenSigMaxLatency" SG_ 2432663360 SetParkClimTimerRqst_Sat 20;
BA_ "NeedsUpdateBit" SG_ 2432663360 SetParkClimTimerRqst_Sat 1;
BA_ "GenSigSendType" SG_ 2432663360 SetParkClimTimerRqst_Rec 1;
BA_ "GenSigCycleTime" SG_ 2432663360 SetParkClimTimerRqst_Rec 100;
BA_ "GenSigCycleTimeActive" SG_ 2432663360 SetParkClimTimerRqst_Rec 100;
BA_ "GenSigMaxLatency" SG_ 2432663360 SetParkClimTimerRqst_Rec 20;
BA_ "NeedsUpdateBit" SG_ 2432663360 SetParkClimTimerRqst_Rec 1;
BA_ "GenSigSendType" SG_ 2432663360 SetParkClimTimerRqst_Thu 1;
BA_ "GenSigCycleTime" SG_ 2432663360 SetParkClimTimerRqst_Thu 100;
BA_ "GenSigCycleTimeActive" SG_ 2432663360 SetParkClimTimerRqst_Thu 100;
BA_ "GenSigMaxLatency" SG_ 2432663360 SetParkClimTimerRqst_Thu 20;
BA_ "NeedsUpdateBit" SG_ 2432663360 SetParkClimTimerRqst_Thu 1;
BA_ "GenSigSendType" SG_ 2432663360 SetParkClimTimerRqst_Min 1;
BA_ "GenSigCycleTime" SG_ 2432663360 SetParkClimTimerRqst_Min 100;
BA_ "GenSigCycleTimeActive" SG_ 2432663360 SetParkClimTimerRqst_Min 100;
BA_ "GenSigStartValue" SG_ 2432663360 SetParkClimTimerRqst_Min 255;
BA_ "GenSigMaxLatency" SG_ 2432663360 SetParkClimTimerRqst_Min 20;
BA_ "NeedsUpdateBit" SG_ 2432663360 SetParkClimTimerRqst_Min 1;
BA_ "GenSigSendType" SG_ 2566357313 CIOM_Cab_34P_FCS 7;
BA_ "GenSigCycleTime" SG_ 2566357312 GPSData_VehSpeed 100;
BA_ "GenSigCycleTimeActive" SG_ 2566357312 GPSData_VehSpeed 100;
BA_ "GenSigStartValue" SG_ 2566357312 GPSData_VehSpeed 65535;
BA_ "GenSigMaxLatency" SG_ 2566357312 GPSData_VehSpeed 551;
BA_ "NeedsUpdateBit" SG_ 2566357312 GPSData_VehSpeed 1;
BA_ "GenSigCycleTime" SG_ 2566357312 GPSData_HDOP 100;
BA_ "GenSigCycleTimeActive" SG_ 2566357312 GPSData_HDOP 100;
BA_ "GenSigMaxLatency" SG_ 2566357312 GPSData_HDOP 551;
BA_ "NeedsUpdateBit" SG_ 2566357312 GPSData_HDOP 1;
BA_ "GenSigCycleTime" SG_ 2566357312 GPSData_Direction 100;
BA_ "GenSigCycleTimeActive" SG_ 2566357312 GPSData_Direction 100;
BA_ "GenSigMaxLatency" SG_ 2566357312 GPSData_Direction 551;
BA_ "NeedsUpdateBit" SG_ 2566357312 GPSData_Direction 1;
BA_ "GenSigCycleTime" SG_ 2566357312 GPSData_Longitude 100;
BA_ "GenSigCycleTimeActive" SG_ 2566357312 GPSData_Longitude 100;
BA_ "GenSigStartValue" SG_ 2566357312 GPSData_Longitude 4294967295;
BA_ "GenSigMaxLatency" SG_ 2566357312 GPSData_Longitude 551;
BA_ "NeedsUpdateBit" SG_ 2566357312 GPSData_Longitude 1;
BA_ "GenSigCycleTime" SG_ 2566357312 GPSData_AntennaStat 100;
BA_ "GenSigCycleTimeActive" SG_ 2566357312 GPSData_AntennaStat 100;
BA_ "GenSigStartValue" SG_ 2566357312 GPSData_AntennaStat 7;
BA_ "GenSigMaxLatency" SG_ 2566357312 GPSData_AntennaStat 551;
BA_ "NeedsUpdateBit" SG_ 2566357312 GPSData_AntennaStat 1;
BA_ "GenSigCycleTime" SG_ 2566357312 GPSData_Latitude 100;
BA_ "GenSigCycleTimeActive" SG_ 2566357312 GPSData_Latitude 100;
BA_ "GenSigStartValue" SG_ 2566357312 GPSData_Latitude 4294967295;
BA_ "GenSigMaxLatency" SG_ 2566357312 GPSData_Latitude 551;
BA_ "NeedsUpdateBit" SG_ 2566357312 GPSData_Latitude 1;
BA_ "GenSigSendType" SG_ 2566357312 GPSData_sg_UB 7;
BA_ "GenSigCycleTime" SG_ 2566357312 GPSData_Altitude 100;
BA_ "GenSigCycleTimeActive" SG_ 2566357312 GPSData_Altitude 100;
BA_ "GenSigStartValue" SG_ 2566357312 GPSData_Altitude 65535;
BA_ "GenSigMaxLatency" SG_ 2566357312 GPSData_Altitude 551;
BA_ "NeedsUpdateBit" SG_ 2566357312 GPSData_Altitude 1;
BA_ "GenSigCycleTime" SG_ 2566357312 GPSData_Time 100;
BA_ "GenSigCycleTimeActive" SG_ 2566357312 GPSData_Time 100;
BA_ "GenSigStartValue" SG_ 2566357312 GPSData_Time 4294967295;
BA_ "GenSigMaxLatency" SG_ 2566357312 GPSData_Time 551;
BA_ "NeedsUpdateBit" SG_ 2566357312 GPSData_Time 1;
BA_ "GenSigCycleTime" SG_ 2432680000 YawRate 100;
BA_ "GenSigCycleTimeActive" SG_ 2432680000 YawRate 100;
BA_ "GenSigStartValue" SG_ 2432680000 YawRate 65535;
BA_ "SeToolAncestorID_SIGNAL" SG_ 2432680000 YawRate "x0000001D04146F42";
BA_ "SeToolItemID_SIGNAL" SG_ 2432680000 YawRate "x0000001D04146F42";
BA_ "SeToolName_SIGNAL" SG_ 2432680000 YawRate "YawRate";
BA_ "SeToolVersion_SIGNAL" SG_ 2432680000 YawRate "1";
BA_ "GenSigCycleTime" SG_ 2432680000 BrakePedalPosition 100;
BA_ "GenSigCycleTimeActive" SG_ 2432680000 BrakePedalPosition 100;
BA_ "GenSigStartValue" SG_ 2432680000 BrakePedalPosition 255;
BA_ "GenSigMaxLatency" SG_ 2432680000 BrakePedalPosition 36;
BA_ "SeToolAncestorID_SIGNAL" SG_ 2432680000 BrakePedalPosition "x0000001D04104A99";
BA_ "SeToolItemID_SIGNAL" SG_ 2432680000 BrakePedalPosition "x0000001D04104A99";
BA_ "SeToolName_SIGNAL" SG_ 2432680000 BrakePedalPosition "BrakePedalPosition";
BA_ "SeToolVersion_SIGNAL" SG_ 2432680000 BrakePedalPosition "1";
BA_ "GenSigCycleTime" SG_ 2432680000 SteeringWheelAngle 100;
BA_ "GenSigCycleTimeActive" SG_ 2432680000 SteeringWheelAngle 100;
BA_ "GenSigStartValue" SG_ 2432680000 SteeringWheelAngle 65535;
BA_ "GenSigMaxLatency" SG_ 2432680000 SteeringWheelAngle 36;
BA_ "SeToolAncestorID_SIGNAL" SG_ 2432680000 SteeringWheelAngle "x0000001D041258E9";
BA_ "SeToolItemID_SIGNAL" SG_ 2432680000 SteeringWheelAngle "x0000001D041258E9";
BA_ "SeToolName_SIGNAL" SG_ 2432680000 SteeringWheelAngle "SteeringWheelAngle";
BA_ "SeToolVersion_SIGNAL" SG_ 2432680000 SteeringWheelAngle "1";
BA_ "GenSigCycleTime" SG_ 2432647232 DirInd_StalkStatus_1 100;
BA_ "GenSigCycleTimeActive" SG_ 2432647232 DirInd_StalkStatus_1 100;
BA_ "GenSigStartValue" SG_ 2432647232 DirInd_StalkStatus_1 7;
BA_ "GenSigMaxLatency" SG_ 2432647232 DirInd_StalkStatus_1 30;
BA_ "SeToolAncestorID_SIGNAL" SG_ 2432647232 DirInd_StalkStatus_1 "x0000001D04261502";
BA_ "SeToolItemID_SIGNAL" SG_ 2432647232 DirInd_StalkStatus_1 "x0000001D043A8A48";
BA_ "SeToolName_SIGNAL" SG_ 2432647232 DirInd_StalkStatus_1 "DirInd_StalkStatus_1";
BA_ "SeToolVersion_SIGNAL" SG_ 2432647232 DirInd_StalkStatus_1 "3";
BA_ "GenSigCycleTime" SG_ 2432647232 CMSPanning_rqst 100;
BA_ "GenSigCycleTimeActive" SG_ 2432647232 CMSPanning_rqst 100;
BA_ "GenSigStartValue" SG_ 2432647232 CMSPanning_rqst 3;
BA_ "GenSigMaxLatency" SG_ 2432647232 CMSPanning_rqst 30;
BA_ "GenSigCycleTime" SG_ 2432647232 CM_Status 100;
BA_ "GenSigCycleTimeActive" SG_ 2432647232 CM_Status 100;
BA_ "GenSigStartValue" SG_ 2432647232 CM_Status 7;
BA_ "GenSigMaxLatency" SG_ 2432647232 CM_Status 26;
BA_ "SeToolAncestorID_SIGNAL" SG_ 2432647232 CM_Status "x0000001D0417D4DA";
BA_ "SeToolItemID_SIGNAL" SG_ 2432647232 CM_Status "x0000001D0428BE35";
BA_ "SeToolName_SIGNAL" SG_ 2432647232 CM_Status "CM_Status";
BA_ "SeToolVersion_SIGNAL" SG_ 2432647232 CM_Status "2";
BA_ "GenSigCycleTime" SG_ 2432647232 CameraAdj_rqst 100;
BA_ "GenSigCycleTimeActive" SG_ 2432647232 CameraAdj_rqst 100;
BA_ "GenSigStartValue" SG_ 2432647232 CameraAdj_rqst 7;
BA_ "GenSigMaxLatency" SG_ 2432647232 CameraAdj_rqst 30;
BA_ "GenSigCycleTime" SG_ 2432647232 CameraSelection_rqst 100;
BA_ "GenSigCycleTimeActive" SG_ 2432647232 CameraSelection_rqst 100;
BA_ "GenSigStartValue" SG_ 2432647232 CameraSelection_rqst 7;
BA_ "GenSigMaxLatency" SG_ 2432647232 CameraSelection_rqst 30;
BA_ "GenSigCycleTime" SG_ 2432647232 LCS_WarningStatusRight 100;
BA_ "GenSigCycleTimeActive" SG_ 2432647232 LCS_WarningStatusRight 100;
BA_ "GenSigStartValue" SG_ 2432647232 LCS_WarningStatusRight 15;
BA_ "GenSigMaxLatency" SG_ 2432647232 LCS_WarningStatusRight 30;
BA_ "GenSigCycleTime" SG_ 2432647232 GearLeverPosition 100;
BA_ "GenSigCycleTimeActive" SG_ 2432647232 GearLeverPosition 100;
BA_ "GenSigStartValue" SG_ 2432647232 GearLeverPosition 15;
BA_ "GenSigMaxLatency" SG_ 2432647232 GearLeverPosition 30;
BA_ "SeToolAncestorID_SIGNAL" SG_ 2432647232 GearLeverPosition "x0000001D0412B683";
BA_ "SeToolItemID_SIGNAL" SG_ 2432647232 GearLeverPosition "x0000001D0412B683";
BA_ "SeToolName_SIGNAL" SG_ 2432647232 GearLeverPosition "GearLeverPosition";
BA_ "SeToolVersion_SIGNAL" SG_ 2432647232 GearLeverPosition "1";
BA_ "GenSigCycleTime" SG_ 2432647232 PassengersSeatBelt 100;
BA_ "GenSigCycleTimeActive" SG_ 2432647232 PassengersSeatBelt 100;
BA_ "GenSigStartValue" SG_ 2432647232 PassengersSeatBelt 7;
BA_ "GenSigCycleTime" SG_ 2432647232 LCS_WarningStatusLeft 100;
BA_ "GenSigCycleTimeActive" SG_ 2432647232 LCS_WarningStatusLeft 100;
BA_ "GenSigStartValue" SG_ 2432647232 LCS_WarningStatusLeft 15;
BA_ "GenSigMaxLatency" SG_ 2432647232 LCS_WarningStatusLeft 30;
BA_ "GenSigCycleTime" SG_ 2432647232 CMSClassVActDeact_rqst 100;
BA_ "GenSigCycleTimeActive" SG_ 2432647232 CMSClassVActDeact_rqst 100;
BA_ "GenSigStartValue" SG_ 2432647232 CMSClassVActDeact_rqst 7;
BA_ "GenSigCycleTime" SG_ 2432647232 CMSBacklightCmd 100;
BA_ "GenSigCycleTimeActive" SG_ 2432647232 CMSBacklightCmd 100;
BA_ "GenSigStartValue" SG_ 2432647232 CMSBacklightCmd 31;
BA_ "GenSigCycleTime" SG_ 2516193600 ReqHVILmonitoring 100;
BA_ "GenSigCycleTimeActive" SG_ 2516193600 ReqHVILmonitoring 100;
BA_ "GenSigStartValue" SG_ 2516193600 ReqHVILmonitoring 3;
BA_ "GenSigCycleTime" SG_ 2516193600 AuxTVSStatus 100;
BA_ "GenSigCycleTimeActive" SG_ 2516193600 AuxTVSStatus 100;
BA_ "GenSigStartValue" SG_ 2516193600 AuxTVSStatus 7;
BA_ "GenSigCycleTime" SG_ 2516193600 ActualDrvlnRetdrPercentTorque 100;
BA_ "GenSigCycleTimeActive" SG_ 2516193600 ActualDrvlnRetdrPercentTorque 100;
BA_ "GenSigStartValue" SG_ 2516193600 ActualDrvlnRetdrPercentTorque 255;
BA_ "SeToolAncestorID_SIGNAL" SG_ 2516193600 ActualDrvlnRetdrPercentTorque "x0000001D0410CFDE";
BA_ "SeToolItemID_SIGNAL" SG_ 2516193600 ActualDrvlnRetdrPercentTorque "x0000001D0410CFDE";
BA_ "SeToolName_SIGNAL" SG_ 2516193600 ActualDrvlnRetdrPercentTorque "ActualDrivelineRetarderPercentTorque";
BA_ "SeToolVersion_SIGNAL" SG_ 2516193600 ActualDrvlnRetdrPercentTorque "1";
BA_ "GenSigCycleTime" SG_ 2516193600 Trailer2LiftAxle2Pos 100;
BA_ "GenSigCycleTimeActive" SG_ 2516193600 Trailer2LiftAxle2Pos 100;
BA_ "GenSigStartValue" SG_ 2516193600 Trailer2LiftAxle2Pos 3;
BA_ "GenSigMaxLatency" SG_ 2516193600 Trailer2LiftAxle2Pos 1001;
BA_ "GenSigCycleTime" SG_ 2516193600 Trailer3LiftAxle2Pos 100;
BA_ "GenSigCycleTimeActive" SG_ 2516193600 Trailer3LiftAxle2Pos 100;
BA_ "GenSigStartValue" SG_ 2516193600 Trailer3LiftAxle2Pos 3;
BA_ "GenSigMaxLatency" SG_ 2516193600 Trailer3LiftAxle2Pos 1001;
BA_ "GenSigCycleTime" SG_ 2516193600 ROPBrakeControlActive 100;
BA_ "GenSigCycleTimeActive" SG_ 2516193600 ROPBrakeControlActive 100;
BA_ "GenSigStartValue" SG_ 2516193600 ROPBrakeControlActive 3;
BA_ "NeedsUpdateBit" SG_ 2516193600 ROPBrakeControlActive 1;
BA_ "GenSigCycleTime" SG_ 2516193600 TransmissionDrivingMode 100;
BA_ "GenSigCycleTimeActive" SG_ 2516193600 TransmissionDrivingMode 100;
BA_ "GenSigStartValue" SG_ 2516193600 TransmissionDrivingMode 7;
BA_ "GenSigCycleTime" SG_ 2516193600 Trailer5LiftAxle1Pos 100;
BA_ "GenSigCycleTimeActive" SG_ 2516193600 Trailer5LiftAxle1Pos 100;
BA_ "GenSigStartValue" SG_ 2516193600 Trailer5LiftAxle1Pos 3;
BA_ "GenSigMaxLatency" SG_ 2516193600 Trailer5LiftAxle1Pos 1001;
BA_ "GenSigCycleTime" SG_ 2516193600 Trailer1LiftAxle2Pos 100;
BA_ "GenSigCycleTimeActive" SG_ 2516193600 Trailer1LiftAxle2Pos 100;
BA_ "GenSigStartValue" SG_ 2516193600 Trailer1LiftAxle2Pos 3;
BA_ "GenSigMaxLatency" SG_ 2516193600 Trailer1LiftAxle2Pos 1001;
BA_ "GenSigCycleTime" SG_ 2516193600 TVSDischargeRequest 100;
BA_ "GenSigCycleTimeActive" SG_ 2516193600 TVSDischargeRequest 100;
BA_ "GenSigStartValue" SG_ 2516193600 TVSDischargeRequest 3;
BA_ "GenSigCycleTime" SG_ 2516193600 FoundationBrakeUse 100;
BA_ "GenSigCycleTimeActive" SG_ 2516193600 FoundationBrakeUse 100;
BA_ "GenSigStartValue" SG_ 2516193600 FoundationBrakeUse 3;
BA_ "SeToolAncestorID_SIGNAL" SG_ 2516193600 FoundationBrakeUse "x0000001D04149A2F";
BA_ "SeToolItemID_SIGNAL" SG_ 2516193600 FoundationBrakeUse "x0000001D043574DF";
BA_ "SeToolName_SIGNAL" SG_ 2516193600 FoundationBrakeUse "FoundationBrakeUse";
BA_ "SeToolVersion_SIGNAL" SG_ 2516193600 FoundationBrakeUse "2";
BA_ "GenSigCycleTime" SG_ 2516193600 Trailer4LiftAxle1Pos 100;
BA_ "GenSigCycleTimeActive" SG_ 2516193600 Trailer4LiftAxle1Pos 100;
BA_ "GenSigStartValue" SG_ 2516193600 Trailer4LiftAxle1Pos 3;
BA_ "GenSigMaxLatency" SG_ 2516193600 Trailer4LiftAxle1Pos 1001;
BA_ "GenSigCycleTime" SG_ 2516193600 Trailer5LiftAxle2Pos 100;
BA_ "GenSigCycleTimeActive" SG_ 2516193600 Trailer5LiftAxle2Pos 100;
BA_ "GenSigStartValue" SG_ 2516193600 Trailer5LiftAxle2Pos 3;
BA_ "GenSigMaxLatency" SG_ 2516193600 Trailer5LiftAxle2Pos 1001;
BA_ "GenSigCycleTime" SG_ 2516193600 BlackPanel_stat 100;
BA_ "GenSigCycleTimeActive" SG_ 2516193600 BlackPanel_stat 100;
BA_ "GenSigStartValue" SG_ 2516193600 BlackPanel_stat 3;
BA_ "GenSigSendType" SG_ 2516193600 YCBrakeControlActive_UB 7;
BA_ "GenSigCycleTime" SG_ 2516193600 Trailer4LiftAxle2Pos 100;
BA_ "GenSigCycleTimeActive" SG_ 2516193600 Trailer4LiftAxle2Pos 100;
BA_ "GenSigStartValue" SG_ 2516193600 Trailer4LiftAxle2Pos 3;
BA_ "GenSigMaxLatency" SG_ 2516193600 Trailer4LiftAxle2Pos 1001;
BA_ "GenSigCycleTime" SG_ 2516193600 AntiLockBrakingActive 100;
BA_ "GenSigCycleTimeActive" SG_ 2516193600 AntiLockBrakingActive 100;
BA_ "GenSigStartValue" SG_ 2516193600 AntiLockBrakingActive 3;
BA_ "SeToolAncestorID_SIGNAL" SG_ 2516193600 AntiLockBrakingActive "x0000001D0410DB7B";
BA_ "SeToolItemID_SIGNAL" SG_ 2516193600 AntiLockBrakingActive "x0000001D0410DB7B";
BA_ "SeToolName_SIGNAL" SG_ 2516193600 AntiLockBrakingActive "Anti-LockBraking(ABS)Active";
BA_ "SeToolVersion_SIGNAL" SG_ 2516193600 AntiLockBrakingActive "1";
BA_ "GenSigCycleTime" SG_ 2516193600 YCBrakeControlActive 100;
BA_ "GenSigCycleTimeActive" SG_ 2516193600 YCBrakeControlActive 100;
BA_ "GenSigStartValue" SG_ 2516193600 YCBrakeControlActive 3;
BA_ "NeedsUpdateBit" SG_ 2516193600 YCBrakeControlActive 1;
BA_ "GenSigCycleTime" SG_ 2516193600 ActualEngineRetarderPercentTrq 100;
BA_ "GenSigCycleTimeActive" SG_ 2516193600 ActualEngineRetarderPercentTrq 100;
BA_ "GenSigStartValue" SG_ 2516193600 ActualEngineRetarderPercentTrq 255;
BA_ "SeToolAncestorID_SIGNAL" SG_ 2516193600 ActualEngineRetarderPercentTrq "x0000001D0410BAE1";
BA_ "SeToolItemID_SIGNAL" SG_ 2516193600 ActualEngineRetarderPercentTrq "x0000001D043C302E";
BA_ "SeToolName_SIGNAL" SG_ 2516193600 ActualEngineRetarderPercentTrq "ActualEngineRetarderPercentTorque";
BA_ "SeToolVersion_SIGNAL" SG_ 2516193600 ActualEngineRetarderPercentTrq "2";
BA_ "GenSigCycleTime" SG_ 2516193600 EngineTmpryStopStartStatus 100;
BA_ "GenSigCycleTimeActive" SG_ 2516193600 EngineTmpryStopStartStatus 100;
BA_ "GenSigStartValue" SG_ 2516193600 EngineTmpryStopStartStatus 15;
BA_ "GenSigCycleTime" SG_ 2516193600 Trailer1LiftAxle1Pos 100;
BA_ "GenSigCycleTimeActive" SG_ 2516193600 Trailer1LiftAxle1Pos 100;
BA_ "GenSigStartValue" SG_ 2516193600 Trailer1LiftAxle1Pos 3;
BA_ "GenSigSendType" SG_ 2516193600 ROPBrakeControlActive_UB 7;
BA_ "GenSigCycleTime" SG_ 2516193600 Trailer3LiftAxle1Pos 100;
BA_ "GenSigCycleTimeActive" SG_ 2516193600 Trailer3LiftAxle1Pos 100;
BA_ "GenSigStartValue" SG_ 2516193600 Trailer3LiftAxle1Pos 3;
BA_ "GenSigMaxLatency" SG_ 2516193600 Trailer3LiftAxle1Pos 1001;
BA_ "GenSigCycleTime" SG_ 2516193600 Trailer2LiftAxle1Pos 100;
BA_ "GenSigCycleTimeActive" SG_ 2516193600 Trailer2LiftAxle1Pos 100;
BA_ "GenSigStartValue" SG_ 2516193600 Trailer2LiftAxle1Pos 3;
BA_ "GenSigMaxLatency" SG_ 2516193600 Trailer2LiftAxle1Pos 1001;
BA_ "GenSigSendType" SG_ 2566357057 CIOM_Cab_30S_FCS 7;
BA_ "GenSigSendType" SG_ 2566357056 SEM_DisplayText_stat 1;
BA_ "GenSigMaxLatency" SG_ 2566357056 SEM_DisplayText_stat 200;
BA_ "GenSigSendType" SG_ 2432679745 CIOM_Cab_29S_FCS 7;
BA_ "GenSigSendType" SG_ 2432679744 MediaSourcesListRsp_SrcAttrib 1;
BA_ "GenSigMaxLatency" SG_ 2432679744 MediaSourcesListRsp_SrcAttrib 50;
BA_ "NeedsUpdateBit" SG_ 2432679744 MediaSourcesListRsp_SrcAttrib 1;
BA_ "GenSigSendType" SG_ 2432679744 MediaSourcesListRsp_ItemID 1;
BA_ "GenSigMaxLatency" SG_ 2432679744 MediaSourcesListRsp_ItemID 50;
BA_ "NeedsUpdateBit" SG_ 2432679744 MediaSourcesListRsp_ItemID 1;
BA_ "GenSigSendType" SG_ 2432679744 MediaSourcesListRsp_Name 1;
BA_ "GenSigMaxLatency" SG_ 2432679744 MediaSourcesListRsp_Name 50;
BA_ "NeedsUpdateBit" SG_ 2432679744 MediaSourcesListRsp_Name 1;
BA_ "GenSigSendType" SG_ 2432679744 MediaSourcesListRsp_SInfo 1;
BA_ "GenSigStartValue" SG_ 2432679744 MediaSourcesListRsp_SInfo 3;
BA_ "GenSigMaxLatency" SG_ 2432679744 MediaSourcesListRsp_SInfo 50;
BA_ "NeedsUpdateBit" SG_ 2432679744 MediaSourcesListRsp_SInfo 1;
BA_ "GenSigSendType" SG_ 2432679744 MediaSourcesListRsp_PCI 1;
BA_ "GenSigMaxLatency" SG_ 2432679744 MediaSourcesListRsp_PCI 50;
BA_ "NeedsUpdateBit" SG_ 2432679744 MediaSourcesListRsp_PCI 1;
BA_ "GenSigSendType" SG_ 2432679744 MediaSourcesListRsp_sg_UB 7;
BA_ "GenSigSendType" SG_ 2432646976 MediaSourcesListNPRsp 1;
BA_ "GenSigCycleTime" SG_ 2432646976 MediaSourcesListNPRsp 100;
BA_ "GenSigCycleTimeActive" SG_ 2432646976 MediaSourcesListNPRsp 100;
BA_ "GenSigMaxLatency" SG_ 2432646976 MediaSourcesListNPRsp 30;
BA_ "NeedsUpdateBit" SG_ 2432646976 MediaSourcesListNPRsp 1;
BA_ "GenSigSendType" SG_ 2432646976 MediaSourcesListNPRsp_UB 7;
BA_ "GenSigCycleTime" SG_ 2493989952 SEMMediaSourceAvail_Source07 100;
BA_ "GenSigCycleTimeActive" SG_ 2493989952 SEMMediaSourceAvail_Source07 100;
BA_ "GenSigCycleTime" SG_ 2493989952 SEMMediaSourceAvail_Source06 100;
BA_ "GenSigCycleTimeActive" SG_ 2493989952 SEMMediaSourceAvail_Source06 100;
BA_ "GenSigCycleTime" SG_ 2493989952 AutoBlowerLevelRqst 100;
BA_ "GenSigCycleTimeActive" SG_ 2493989952 AutoBlowerLevelRqst 100;
BA_ "GenSigStartValue" SG_ 2493989952 AutoBlowerLevelRqst 7;
BA_ "GenSigCycleTime" SG_ 2493989952 SEMMediaSourceAvail_Source08 100;
BA_ "GenSigCycleTimeActive" SG_ 2493989952 SEMMediaSourceAvail_Source08 100;
BA_ "GenSigCycleTime" SG_ 2493989952 SEMMediaSourceAvail_Source00 100;
BA_ "GenSigCycleTimeActive" SG_ 2493989952 SEMMediaSourceAvail_Source00 100;
BA_ "GenSigCycleTime" SG_ 2493989952 SEM_AudioMuteStat 100;
BA_ "GenSigCycleTimeActive" SG_ 2493989952 SEM_AudioMuteStat 100;
BA_ "GenSigStartValue" SG_ 2493989952 SEM_AudioMuteStat 7;
BA_ "GenSigCycleTime" SG_ 2493989952 SEMMediaSourceAvail_Source09 100;
BA_ "GenSigCycleTimeActive" SG_ 2493989952 SEMMediaSourceAvail_Source09 100;
BA_ "GenSigCycleTime" SG_ 2493989952 SEMMediaSourceAvail_Source13 100;
BA_ "GenSigCycleTimeActive" SG_ 2493989952 SEMMediaSourceAvail_Source13 100;
BA_ "GenSigCycleTime" SG_ 2493989952 SEMMediaSourceAvail_Source04 100;
BA_ "GenSigCycleTimeActive" SG_ 2493989952 SEMMediaSourceAvail_Source04 100;
BA_ "GenSigCycleTime" SG_ 2493989952 SEMMediaSourceAvail_Source05 100;
BA_ "GenSigCycleTimeActive" SG_ 2493989952 SEMMediaSourceAvail_Source05 100;
BA_ "GenSigCycleTime" SG_ 2493989952 SEMMediaSourceAvail_Source02 100;
BA_ "GenSigCycleTimeActive" SG_ 2493989952 SEMMediaSourceAvail_Source02 100;
BA_ "GenSigCycleTime" SG_ 2493989952 SEMMediaSourceAvail_SInfo 100;
BA_ "GenSigCycleTimeActive" SG_ 2493989952 SEMMediaSourceAvail_SInfo 100;
BA_ "GenSigStartValue" SG_ 2493989952 SEMMediaSourceAvail_SInfo 3;
BA_ "GenSigCycleTime" SG_ 2493989952 AQSModeRqst 100;
BA_ "GenSigCycleTimeActive" SG_ 2493989952 AQSModeRqst 100;
BA_ "GenSigStartValue" SG_ 2493989952 AQSModeRqst 7;
BA_ "GenSigCycleTime" SG_ 2493989952 AudioSourceStat 100;
BA_ "GenSigCycleTimeActive" SG_ 2493989952 AudioSourceStat 100;
BA_ "GenSigStartValue" SG_ 2493989952 AudioSourceStat 15;
BA_ "GenSigCycleTime" SG_ 2493989952 SEMMediaSourceAvail_Source11 100;
BA_ "GenSigCycleTimeActive" SG_ 2493989952 SEMMediaSourceAvail_Source11 100;
BA_ "GenSigCycleTime" SG_ 2493989952 SEMMediaSourceAvail_Source10 100;
BA_ "GenSigCycleTimeActive" SG_ 2493989952 SEMMediaSourceAvail_Source10 100;
BA_ "GenSigCycleTime" SG_ 2493989952 ACModeRqst 100;
BA_ "GenSigCycleTimeActive" SG_ 2493989952 ACModeRqst 100;
BA_ "GenSigStartValue" SG_ 2493989952 ACModeRqst 7;
BA_ "GenSigCycleTime" SG_ 2493989952 ESS_TRDStatus 100;
BA_ "GenSigCycleTimeActive" SG_ 2493989952 ESS_TRDStatus 100;
BA_ "GenSigStartValue" SG_ 2493989952 ESS_TRDStatus 7;
BA_ "GenSigCycleTime" SG_ 2493989952 AutoDefogModeRqst 100;
BA_ "GenSigCycleTimeActive" SG_ 2493989952 AutoDefogModeRqst 100;
BA_ "GenSigStartValue" SG_ 2493989952 AutoDefogModeRqst 7;
BA_ "GenSigCycleTime" SG_ 2493989952 SEM_AudioVolValIndCmd 100;
BA_ "GenSigCycleTimeActive" SG_ 2493989952 SEM_AudioVolValIndCmd 100;
BA_ "GenSigCycleTime" SG_ 2493989952 SEMMediaSourceAvail_Source01 100;
BA_ "GenSigCycleTimeActive" SG_ 2493989952 SEMMediaSourceAvail_Source01 100;
BA_ "GenSigCycleTime" SG_ 2493989952 EngineActiveStatus 100;
BA_ "GenSigCycleTimeActive" SG_ 2493989952 EngineActiveStatus 100;
BA_ "GenSigStartValue" SG_ 2493989952 EngineActiveStatus 15;
BA_ "SeToolAncestorID_SIGNAL" SG_ 2493989952 EngineActiveStatus "x0000001D0421DFD5";
BA_ "SeToolItemID_SIGNAL" SG_ 2493989952 EngineActiveStatus "x0000001D0421DFD5";
BA_ "SeToolName_SIGNAL" SG_ 2493989952 EngineActiveStatus "EngineActiveStatus";
BA_ "SeToolVersion_SIGNAL" SG_ 2493989952 EngineActiveStatus "1";
BA_ "GenSigCycleTime" SG_ 2493989952 SEMMediaSourceAvail_Source03 100;
BA_ "GenSigCycleTimeActive" SG_ 2493989952 SEMMediaSourceAvail_Source03 100;
BA_ "GenSigCycleTime" SG_ 2493989952 SEM_PresetIndicationCmd 100;
BA_ "GenSigCycleTimeActive" SG_ 2493989952 SEM_PresetIndicationCmd 100;
BA_ "GenSigStartValue" SG_ 2493989952 SEM_PresetIndicationCmd 63;
BA_ "GenSigCycleTime" SG_ 2493989952 SEMMediaSourceAvail_Source12 100;
BA_ "GenSigCycleTimeActive" SG_ 2493989952 SEMMediaSourceAvail_Source12 100;
BA_ "GenSigCycleTime" SG_ 2499754560 InhibitTVSReq 100;
BA_ "GenSigCycleTimeActive" SG_ 2499754560 InhibitTVSReq 100;
BA_ "GenSigStartValue" SG_ 2499754560 InhibitTVSReq 7;
BA_ "GenSigCycleTime" SG_ 2499754560 TipperEmergencyStopStatus 100;
BA_ "GenSigCycleTimeActive" SG_ 2499754560 TipperEmergencyStopStatus 100;
BA_ "GenSigStartValue" SG_ 2499754560 TipperEmergencyStopStatus 7;
BA_ "GenSigCycleTime" SG_ 2499754560 TipperPrimaryBodyStatus 100;
BA_ "GenSigCycleTimeActive" SG_ 2499754560 TipperPrimaryBodyStatus 100;
BA_ "GenSigStartValue" SG_ 2499754560 TipperPrimaryBodyStatus 7;
BA_ "GenSigCycleTime" SG_ 2499754560 TipperConditionsStatus 100;
BA_ "GenSigCycleTimeActive" SG_ 2499754560 TipperConditionsStatus 100;
BA_ "GenSigStartValue" SG_ 2499754560 TipperConditionsStatus 3;
BA_ "GenSigMaxLatency" SG_ 2499754560 TipperConditionsStatus 65;
BA_ "GenSigCycleTime" SG_ 2499754560 TipperSecondaryBodyStatus 100;
BA_ "GenSigCycleTimeActive" SG_ 2499754560 TipperSecondaryBodyStatus 100;
BA_ "GenSigStartValue" SG_ 2499754560 TipperSecondaryBodyStatus 7;
BA_ "GenSigCycleTime" SG_ 2499754560 BatterySOCAlert_rqst 100;
BA_ "GenSigCycleTimeActive" SG_ 2499754560 BatterySOCAlert_rqst 100;
BA_ "GenSigStartValue" SG_ 2499754560 BatterySOCAlert_rqst 7;
BA_ "GenSigCycleTime" SG_ 2499754560 CCStates 100;
BA_ "GenSigCycleTimeActive" SG_ 2499754560 CCStates 100;
BA_ "GenSigStartValue" SG_ 2499754560 CCStates 15;
BA_ "GenSigMaxLatency" SG_ 2499754560 CCStates 40;
BA_ "GenSigCycleTime" SG_ 2499754560 ExtraHeating_rqst 100;
BA_ "GenSigCycleTimeActive" SG_ 2499754560 ExtraHeating_rqst 100;
BA_ "GenSigStartValue" SG_ 2499754560 ExtraHeating_rqst 7;
BA_ "GenSigCycleTime" SG_ 2499754560 LongMotionDirection 100;
BA_ "GenSigCycleTimeActive" SG_ 2499754560 LongMotionDirection 100;
BA_ "GenSigStartValue" SG_ 2499754560 LongMotionDirection 7;
BA_ "GenSigCycleTime" SG_ 2499754560 TipperUpDownStatus 100;
BA_ "GenSigCycleTimeActive" SG_ 2499754560 TipperUpDownStatus 100;
BA_ "GenSigStartValue" SG_ 2499754560 TipperUpDownStatus 7;
BA_ "GenSigMaxLatency" SG_ 2499754560 TipperUpDownStatus 65;
BA_ "GenSigCycleTime" SG_ 2499754560 TipperTailGateStatus 100;
BA_ "GenSigCycleTimeActive" SG_ 2499754560 TipperTailGateStatus 100;
BA_ "GenSigStartValue" SG_ 2499754560 TipperTailGateStatus 7;
BA_ "GenSigMaxLatency" SG_ 2499754560 TipperTailGateStatus 65;
BA_ "GenSigCycleTime" SG_ 2499754560 KneelingInformation 100;
BA_ "GenSigCycleTimeActive" SG_ 2499754560 KneelingInformation 100;
BA_ "GenSigStartValue" SG_ 2499754560 KneelingInformation 15;
BA_ "GenSigCycleTime" SG_ 2499754560 TailLiftRemoteNotAllowed 100;
BA_ "GenSigCycleTimeActive" SG_ 2499754560 TailLiftRemoteNotAllowed 100;
BA_ "GenSigStartValue" SG_ 2499754560 TailLiftRemoteNotAllowed 3;
BA_ "GenSigMaxLatency" SG_ 2499754560 TailLiftRemoteNotAllowed 65;
BA_ "GenSigCycleTime" SG_ 2499754560 DirectionIndicatorActive_stat 100;
BA_ "GenSigCycleTimeActive" SG_ 2499754560 DirectionIndicatorActive_stat 100;
BA_ "GenSigStartValue" SG_ 2499754560 DirectionIndicatorActive_stat 7;
BA_ "GenSigCycleTime" SG_ 2499754560 TipperTarpaulinStatus 100;
BA_ "GenSigCycleTimeActive" SG_ 2499754560 TipperTarpaulinStatus 100;
BA_ "GenSigStartValue" SG_ 2499754560 TipperTarpaulinStatus 7;
BA_ "GenSigMaxLatency" SG_ 2499754560 TipperTarpaulinStatus 65;
BA_ "GenSigCycleTime" SG_ 2499754560 TailLiftConditionsStatus 100;
BA_ "GenSigCycleTimeActive" SG_ 2499754560 TailLiftConditionsStatus 100;
BA_ "GenSigStartValue" SG_ 2499754560 TailLiftConditionsStatus 3;
BA_ "GenSigMaxLatency" SG_ 2499754560 TailLiftConditionsStatus 65;
BA_ "GenSigCycleTime" SG_ 2499754560 InhibitWRCECSMenuCmd 100;
BA_ "GenSigCycleTimeActive" SG_ 2499754560 InhibitWRCECSMenuCmd 100;
BA_ "GenSigStartValue" SG_ 2499754560 InhibitWRCECSMenuCmd 3;
BA_ "GenSigMaxLatency" SG_ 2499754560 InhibitWRCECSMenuCmd 65;
BA_ "GenSigCycleTime" SG_ 2499754560 ShortStopHeater_status 100;
BA_ "GenSigCycleTimeActive" SG_ 2499754560 ShortStopHeater_status 100;
BA_ "GenSigStartValue" SG_ 2499754560 ShortStopHeater_status 7;
BA_ "GenSigCycleTime" SG_ 2499754560 LongMotionDirectionQual 100;
BA_ "GenSigCycleTimeActive" SG_ 2499754560 LongMotionDirectionQual 100;
BA_ "GenSigStartValue" SG_ 2499754560 LongMotionDirectionQual 3;
BA_ "GenSigCycleTime" SG_ 2499754560 TipperShakerStatus 100;
BA_ "GenSigCycleTimeActive" SG_ 2499754560 TipperShakerStatus 100;
BA_ "GenSigStartValue" SG_ 2499754560 TipperShakerStatus 3;
BA_ "GenSigMaxLatency" SG_ 2499754560 TipperShakerStatus 65;
BA_ "GenSigCycleTime" SG_ 2499754560 TailLiftMotionStatus 100;
BA_ "GenSigCycleTimeActive" SG_ 2499754560 TailLiftMotionStatus 100;
BA_ "GenSigStartValue" SG_ 2499754560 TailLiftMotionStatus 7;
BA_ "GenSigMaxLatency" SG_ 2499754560 TailLiftMotionStatus 65;
BA_ "GenSigCycleTime" SG_ 2499679296 CoolantPumpEngagementStatus 100;
BA_ "GenSigCycleTimeActive" SG_ 2499679296 CoolantPumpEngagementStatus 100;
BA_ "GenSigStartValue" SG_ 2499679296 CoolantPumpEngagementStatus 255;
BA_ "GenSigCycleTime" SG_ 2499679296 PHTimerRqstAck_Hours 100;
BA_ "GenSigCycleTimeActive" SG_ 2499679296 PHTimerRqstAck_Hours 100;
BA_ "GenSigStartValue" SG_ 2499679296 PHTimerRqstAck_Hours 255;
BA_ "GenSigCycleTime" SG_ 2499679296 LoadDistributionSelected 100;
BA_ "GenSigCycleTimeActive" SG_ 2499679296 LoadDistributionSelected 100;
BA_ "GenSigStartValue" SG_ 2499679296 LoadDistributionSelected 15;
BA_ "GenSigCycleTime" SG_ 2499679296 PHTimerRqstAck_DayOfWeekRq 100;
BA_ "GenSigCycleTimeActive" SG_ 2499679296 PHTimerRqstAck_DayOfWeekRq 100;
BA_ "GenSigStartValue" SG_ 2499679296 PHTimerRqstAck_DayOfWeekRq 15;
BA_ "GenSigCycleTime" SG_ 2499679296 PHTimerRqstAck_Minutes 100;
BA_ "GenSigCycleTimeActive" SG_ 2499679296 PHTimerRqstAck_Minutes 100;
BA_ "GenSigStartValue" SG_ 2499679296 PHTimerRqstAck_Minutes 255;
BA_ "GenSigCycleTime" SG_ 2499679296 LiftAxle1PositionStatus 100;
BA_ "GenSigCycleTimeActive" SG_ 2499679296 LiftAxle1PositionStatus 100;
BA_ "GenSigStartValue" SG_ 2499679296 LiftAxle1PositionStatus 7;
BA_ "SeToolAncestorID_SIGNAL" SG_ 2499679296 LiftAxle1PositionStatus "x0000001D04131A08";
BA_ "SeToolItemID_SIGNAL" SG_ 2499679296 LiftAxle1PositionStatus "x0000001D0423C412";
BA_ "SeToolName_SIGNAL" SG_ 2499679296 LiftAxle1PositionStatus "LiftAxle1PositionStatus";
BA_ "SeToolVersion_SIGNAL" SG_ 2499679296 LiftAxle1PositionStatus "2";
BA_ "GenSigCycleTime" SG_ 2499679296 PHTimerRqstAck_CurrentOp 100;
BA_ "GenSigCycleTimeActive" SG_ 2499679296 PHTimerRqstAck_CurrentOp 100;
BA_ "GenSigStartValue" SG_ 2499679296 PHTimerRqstAck_CurrentOp 3;
BA_ "GenSigCycleTime" SG_ 2499679296 LiftAxle2PositionStatus 100;
BA_ "GenSigCycleTimeActive" SG_ 2499679296 LiftAxle2PositionStatus 100;
BA_ "GenSigStartValue" SG_ 2499679296 LiftAxle2PositionStatus 7;
BA_ "SeToolAncestorID_SIGNAL" SG_ 2499679296 LiftAxle2PositionStatus "x0000001D04131A0A";
BA_ "SeToolItemID_SIGNAL" SG_ 2499679296 LiftAxle2PositionStatus "x0000001D04295880";
BA_ "SeToolName_SIGNAL" SG_ 2499679296 LiftAxle2PositionStatus "LiftAxle2PositionStatus";
BA_ "SeToolVersion_SIGNAL" SG_ 2499679296 LiftAxle2PositionStatus "3";
BA_ "GenSigCycleTime" SG_ 2499679296 EngineCoolingFanSpeed 100;
BA_ "GenSigCycleTimeActive" SG_ 2499679296 EngineCoolingFanSpeed 100;
BA_ "GenSigStartValue" SG_ 2499679296 EngineCoolingFanSpeed 65535;
BA_ "GenSigCycleTime" SG_ 2499679296 ParkingBrake_stat 100;
BA_ "GenSigCycleTimeActive" SG_ 2499679296 ParkingBrake_stat 100;
BA_ "GenSigStartValue" SG_ 2499679296 ParkingBrake_stat 3;
BA_ "GenSigCycleTime" SG_ 2499679296 AudioMuteStat 100;
BA_ "GenSigCycleTimeActive" SG_ 2499679296 AudioMuteStat 100;
BA_ "GenSigStartValue" SG_ 2499679296 AudioMuteStat 7;
BA_ "SeToolAncestorID_SIGNAL" SG_ 2499679296 AudioMuteStat "x0000001D043278F0";
BA_ "SeToolItemID_SIGNAL" SG_ 2499679296 AudioMuteStat "x0000001D043278F0";
BA_ "SeToolName_SIGNAL" SG_ 2499679296 AudioMuteStat "AudioMuteStat";
BA_ "SeToolVersion_SIGNAL" SG_ 2499679296 AudioMuteStat "1";
BA_ "GenSigCycleTime" SG_ 2549186373 AudioSourceBtStreamAvailable 100;
BA_ "GenSigCycleTimeActive" SG_ 2549186373 AudioSourceBtStreamAvailable 100;
BA_ "GenSigStartValue" SG_ 2549186373 AudioSourceBtStreamAvailable 3;
BA_ "GenSigCycleTime" SG_ 2549186373 PS_EntChannelNumber 100;
BA_ "GenSigCycleTimeActive" SG_ 2549186373 PS_EntChannelNumber 100;
BA_ "GenSigStartValue" SG_ 2549186373 PS_EntChannelNumber 99999;
BA_ "GenSigCycleTime" SG_ 2549186373 AudioSourceStatus2 100;
BA_ "GenSigCycleTimeActive" SG_ 2549186373 AudioSourceStatus2 100;
BA_ "GenSigStartValue" SG_ 2549186373 AudioSourceStatus2 15;
BA_ "GenSigCycleTime" SG_ 2549186373 AudioSourceUsbAvailable 100;
BA_ "GenSigCycleTimeActive" SG_ 2549186373 AudioSourceUsbAvailable 100;
BA_ "GenSigStartValue" SG_ 2549186373 AudioSourceUsbAvailable 3;
BA_ "GenSigCycleTime" SG_ 2549186373 AudioSourceCdAvailable 100;
BA_ "GenSigCycleTimeActive" SG_ 2549186373 AudioSourceCdAvailable 100;
BA_ "GenSigStartValue" SG_ 2549186373 AudioSourceCdAvailable 3;
BA_ "GenSigCycleTime" SG_ 2549186373 AudioSourceIpodAvailable 100;
BA_ "GenSigCycleTimeActive" SG_ 2549186373 AudioSourceIpodAvailable 100;
BA_ "GenSigStartValue" SG_ 2549186373 AudioSourceIpodAvailable 3;
BA_ "GenSigSendType" SG_ 2566864832 CIOM_Cab_20S_FCS 7;
BA_ "GenSigSendType" SG_ 2566864831 DisplayText_stat 1;
BA_ "GenSigMaxLatency" SG_ 2566864831 DisplayText_stat 26;
BA_ "GenSigSendType" SG_ 2565974016 CIOM_Cab_13S_FCS 7;
BA_ "GenSigSendType" SG_ 2565974015 FdEquipmentFreeText 1;
BA_ "GenSigCycleTime" SG_ 2565974015 FdEquipmentFreeText 100;
BA_ "GenSigCycleTimeActive" SG_ 2565974015 FdEquipmentFreeText 100;
BA_ "GenSigMaxLatency" SG_ 2565974015 FdEquipmentFreeText 200;
BA_ "SeToolAncestorID_SIGNAL" SG_ 2565974015 FdEquipmentFreeText "x0000001D04171318";
BA_ "SeToolItemID_SIGNAL" SG_ 2565974015 FdEquipmentFreeText "x0000001D04171318";
BA_ "SeToolName_SIGNAL" SG_ 2565974015 FdEquipmentFreeText "FdEquipmentFreeText";
BA_ "SeToolVersion_SIGNAL" SG_ 2565974015 FdEquipmentFreeText "1";
BA_ "GenSigCycleTime" SG_ 2565904383 AlarmClkAl_LECM_stat_SetHr 100;
BA_ "GenSigCycleTimeActive" SG_ 2565904383 AlarmClkAl_LECM_stat_SetHr 100;
BA_ "GenSigStartValue" SG_ 2565904383 AlarmClkAl_LECM_stat_SetHr 31;
BA_ "GenSigCycleTime" SG_ 2565904383 ESCReqESC_CtrlTrimValue 100;
BA_ "GenSigCycleTimeActive" SG_ 2565904383 ESCReqESC_CtrlTrimValue 100;
BA_ "GenSigStartValue" SG_ 2565904383 ESCReqESC_CtrlTrimValue 255;
BA_ "GenSigMaxLatency" SG_ 2565904383 ESCReqESC_CtrlTrimValue 140;
BA_ "SeToolAncestorID_SIGNAL" SG_ 2565904383 ESCReqESC_CtrlTrimValue "x0000001D042A7114";
BA_ "SeToolItemID_SIGNAL" SG_ 2565904383 ESCReqESC_CtrlTrimValue "x0000001D042A7114";
BA_ "SeToolName_SIGNAL" SG_ 2565904383 ESCReqESC_CtrlTrimValue "CtrlTrimValue";
BA_ "SeToolOwnerSigGroupID_SIGNAL" SG_ 2565904383 ESCReqESC_CtrlTrimValue "x0000001D043D5DD2";
BA_ "SeToolOwnerSigGroup_SIGNAL" SG_ 2565904383 ESCReqESC_CtrlTrimValue "ESCReqESC";
BA_ "SeToolVersion_SIGNAL" SG_ 2565904383 ESCReqESC_CtrlTrimValue "1";
BA_ "GenSigCycleTime" SG_ 2565904383 AlarmClockNotification_Stat 100;
BA_ "GenSigCycleTimeActive" SG_ 2565904383 AlarmClockNotification_Stat 100;
BA_ "GenSigMaxLatency" SG_ 2565904383 AlarmClockNotification_Stat 140;
BA_ "GenSigCycleTime" SG_ 2565904383 AlarmClkAl_LECM_stat_Type 100;
BA_ "GenSigCycleTimeActive" SG_ 2565904383 AlarmClkAl_LECM_stat_Type 100;
BA_ "GenSigStartValue" SG_ 2565904383 AlarmClkAl_LECM_stat_Type 7;
BA_ "GenSigCycleTime" SG_ 2565904383 AlarmClkAl_LECM_stat_Stat 100;
BA_ "GenSigCycleTimeActive" SG_ 2565904383 AlarmClkAl_LECM_stat_Stat 100;
BA_ "GenSigCycleTime" SG_ 2565904383 AlarmClockNotification_Type 100;
BA_ "GenSigCycleTimeActive" SG_ 2565904383 AlarmClockNotification_Type 100;
BA_ "GenSigStartValue" SG_ 2565904383 AlarmClockNotification_Type 7;
BA_ "GenSigMaxLatency" SG_ 2565904383 AlarmClockNotification_Type 140;
BA_ "GenSigCycleTime" SG_ 2565904383 AlarmClkAl_LECM_stat_DaySet 100;
BA_ "GenSigCycleTimeActive" SG_ 2565904383 AlarmClkAl_LECM_stat_DaySet 100;
BA_ "GenSigCycleTime" SG_ 2565904383 ESCReqESC_CtrlTrimReq 100;
BA_ "GenSigCycleTimeActive" SG_ 2565904383 ESCReqESC_CtrlTrimReq 100;
BA_ "GenSigStartValue" SG_ 2565904383 ESCReqESC_CtrlTrimReq 7;
BA_ "GenSigMaxLatency" SG_ 2565904383 ESCReqESC_CtrlTrimReq 140;
BA_ "SeToolAncestorID_SIGNAL" SG_ 2565904383 ESCReqESC_CtrlTrimReq "x0000001D042A710B";
BA_ "SeToolItemID_SIGNAL" SG_ 2565904383 ESCReqESC_CtrlTrimReq "x0000001D042A710B";
BA_ "SeToolName_SIGNAL" SG_ 2565904383 ESCReqESC_CtrlTrimReq "CtrlTrimReq";
BA_ "SeToolOwnerSigGroupID_SIGNAL" SG_ 2565904383 ESCReqESC_CtrlTrimReq "x0000001D043D5DD2";
BA_ "SeToolOwnerSigGroup_SIGNAL" SG_ 2565904383 ESCReqESC_CtrlTrimReq "ESCReqESC";
BA_ "SeToolVersion_SIGNAL" SG_ 2565904383 ESCReqESC_CtrlTrimReq "1";
BA_ "GenSigCycleTime" SG_ 2565904383 AlarmClkAl_LECM_stat_ID 100;
BA_ "GenSigCycleTimeActive" SG_ 2565904383 AlarmClkAl_LECM_stat_ID 100;
BA_ "GenSigStartValue" SG_ 2565904383 AlarmClkAl_LECM_stat_ID 127;
BA_ "GenSigCycleTime" SG_ 2565904383 ESCReqESC_CtrlTrimMode 100;
BA_ "GenSigCycleTimeActive" SG_ 2565904383 ESCReqESC_CtrlTrimMode 100;
BA_ "GenSigStartValue" SG_ 2565904383 ESCReqESC_CtrlTrimMode 15;
BA_ "GenSigMaxLatency" SG_ 2565904383 ESCReqESC_CtrlTrimMode 140;
BA_ "SeToolAncestorID_SIGNAL" SG_ 2565904383 ESCReqESC_CtrlTrimMode "x0000001D042A710F";
BA_ "SeToolItemID_SIGNAL" SG_ 2565904383 ESCReqESC_CtrlTrimMode "x0000001D042A710F";
BA_ "SeToolName_SIGNAL" SG_ 2565904383 ESCReqESC_CtrlTrimMode "CtrlTrimMode";
BA_ "SeToolOwnerSigGroupID_SIGNAL" SG_ 2565904383 ESCReqESC_CtrlTrimMode "x0000001D043D5DD2";
BA_ "SeToolOwnerSigGroup_SIGNAL" SG_ 2565904383 ESCReqESC_CtrlTrimMode "ESCReqESC";
BA_ "SeToolVersion_SIGNAL" SG_ 2565904383 ESCReqESC_CtrlTrimMode "1";
BA_ "GenSigCycleTime" SG_ 2565904383 AlarmClkAl_LECM_stat_SetMin 100;
BA_ "GenSigCycleTimeActive" SG_ 2565904383 AlarmClkAl_LECM_stat_SetMin 100;
BA_ "GenSigStartValue" SG_ 2565904383 AlarmClkAl_LECM_stat_SetMin 63;
BA_ "GenSigCycleTime" SG_ 2565904383 ESCReqESC_CtrlTrimStat 100;
BA_ "GenSigCycleTimeActive" SG_ 2565904383 ESCReqESC_CtrlTrimStat 100;
BA_ "GenSigStartValue" SG_ 2565904383 ESCReqESC_CtrlTrimStat 7;
BA_ "GenSigMaxLatency" SG_ 2565904383 ESCReqESC_CtrlTrimStat 140;
BA_ "SeToolAncestorID_SIGNAL" SG_ 2565904383 ESCReqESC_CtrlTrimStat "x0000001D042A710D";
BA_ "SeToolItemID_SIGNAL" SG_ 2565904383 ESCReqESC_CtrlTrimStat "x0000001D042A710D";
BA_ "SeToolName_SIGNAL" SG_ 2565904383 ESCReqESC_CtrlTrimStat "CtrlTrimStat";
BA_ "SeToolOwnerSigGroupID_SIGNAL" SG_ 2565904383 ESCReqESC_CtrlTrimStat "x0000001D043D5DD2";
BA_ "SeToolOwnerSigGroup_SIGNAL" SG_ 2565904383 ESCReqESC_CtrlTrimStat "ESCReqESC";
BA_ "SeToolVersion_SIGNAL" SG_ 2565904383 ESCReqESC_CtrlTrimStat "1";
BA_ "GenSigCycleTime" SG_ 2565904383 AlarmClkAl_LECM_stat_Mode 100;
BA_ "GenSigCycleTimeActive" SG_ 2565904383 AlarmClkAl_LECM_stat_Mode 100;
BA_ "GenSigCycleTime" SG_ 2565904383 AlarmClockNotification_ID 100;
BA_ "GenSigCycleTimeActive" SG_ 2565904383 AlarmClockNotification_ID 100;
BA_ "GenSigStartValue" SG_ 2565904383 AlarmClockNotification_ID 127;
BA_ "GenSigSendType" SG_ 2565834752 CIOM_Cab_11S_FCS 7;
BA_ "GenSigSendType" SG_ 2565834751 ECUVIN_stat 1;
BA_ "GenSigCycleTime" SG_ 2565834751 ECUVIN_stat 100;
BA_ "GenSigCycleTimeActive" SG_ 2565834751 ECUVIN_stat 100;
BA_ "GenSigMaxLatency" SG_ 2565834751 ECUVIN_stat 110;
BA_ "GenSigCycleTime" SG_ 2499755967 FdEquipmentStatus2 100;
BA_ "GenSigCycleTimeActive" SG_ 2499755967 FdEquipmentStatus2 100;
BA_ "GenSigStartValue" SG_ 2499755967 FdEquipmentStatus2 3;
BA_ "GenSigMaxLatency" SG_ 2499755967 FdEquipmentStatus2 60;
BA_ "SeToolAncestorID_SIGNAL" SG_ 2499755967 FdEquipmentStatus2 "x0000001D041709FC";
BA_ "SeToolItemID_SIGNAL" SG_ 2499755967 FdEquipmentStatus2 "x0000001D041709FC";
BA_ "SeToolName_SIGNAL" SG_ 2499755967 FdEquipmentStatus2 "FdEquipmentStatus2";
BA_ "SeToolVersion_SIGNAL" SG_ 2499755967 FdEquipmentStatus2 "1";
BA_ "GenSigCycleTime" SG_ 2499755967 RideHeightStatus 100;
BA_ "GenSigCycleTimeActive" SG_ 2499755967 RideHeightStatus 100;
BA_ "GenSigStartValue" SG_ 2499755967 RideHeightStatus 15;
BA_ "GenSigMaxLatency" SG_ 2499755967 RideHeightStatus 60;
BA_ "SeToolAncestorID_SIGNAL" SG_ 2499755967 RideHeightStatus "x0000001D041304DF";
BA_ "SeToolItemID_SIGNAL" SG_ 2499755967 RideHeightStatus "x0000001D0442415B";
BA_ "SeToolName_SIGNAL" SG_ 2499755967 RideHeightStatus "RideHeightStatus";
BA_ "SeToolVersion_SIGNAL" SG_ 2499755967 RideHeightStatus "3";
BA_ "GenSigCycleTime" SG_ 2499755967 FdEquipmentStatus4 100;
BA_ "GenSigCycleTimeActive" SG_ 2499755967 FdEquipmentStatus4 100;
BA_ "GenSigStartValue" SG_ 2499755967 FdEquipmentStatus4 3;
BA_ "GenSigMaxLatency" SG_ 2499755967 FdEquipmentStatus4 60;
BA_ "SeToolAncestorID_SIGNAL" SG_ 2499755967 FdEquipmentStatus4 "x0000001D04170A00";
BA_ "SeToolItemID_SIGNAL" SG_ 2499755967 FdEquipmentStatus4 "x0000001D04170A00";
BA_ "SeToolName_SIGNAL" SG_ 2499755967 FdEquipmentStatus4 "FdEquipmentStatus4";
BA_ "SeToolVersion_SIGNAL" SG_ 2499755967 FdEquipmentStatus4 "1";
BA_ "GenSigCycleTime" SG_ 2499755967 RideHeightOutsideTargetRange 100;
BA_ "GenSigCycleTimeActive" SG_ 2499755967 RideHeightOutsideTargetRange 100;
BA_ "GenSigStartValue" SG_ 2499755967 RideHeightOutsideTargetRange 7;
BA_ "GenSigMaxLatency" SG_ 2499755967 RideHeightOutsideTargetRange 60;
BA_ "SeToolAncestorID_SIGNAL" SG_ 2499755967 RideHeightOutsideTargetRange "x0000001D041F15D9";
BA_ "SeToolItemID_SIGNAL" SG_ 2499755967 RideHeightOutsideTargetRange "x0000001D041F15D9";
BA_ "SeToolName_SIGNAL" SG_ 2499755967 RideHeightOutsideTargetRange "RideHeightOutsideTargetRange";
BA_ "SeToolVersion_SIGNAL" SG_ 2499755967 RideHeightOutsideTargetRange "1";
BA_ "GenSigCycleTime" SG_ 2499755967 FdEquipmentStatus1 100;
BA_ "GenSigCycleTimeActive" SG_ 2499755967 FdEquipmentStatus1 100;
BA_ "GenSigStartValue" SG_ 2499755967 FdEquipmentStatus1 3;
BA_ "GenSigMaxLatency" SG_ 2499755967 FdEquipmentStatus1 60;
BA_ "SeToolAncestorID_SIGNAL" SG_ 2499755967 FdEquipmentStatus1 "x0000001D041709FA";
BA_ "SeToolItemID_SIGNAL" SG_ 2499755967 FdEquipmentStatus1 "x0000001D041709FA";
BA_ "SeToolName_SIGNAL" SG_ 2499755967 FdEquipmentStatus1 "FdEquipmentStatus1";
BA_ "SeToolVersion_SIGNAL" SG_ 2499755967 FdEquipmentStatus1 "1";
BA_ "GenSigCycleTime" SG_ 2499755967 FdEquipmentStatus5 100;
BA_ "GenSigCycleTimeActive" SG_ 2499755967 FdEquipmentStatus5 100;
BA_ "GenSigStartValue" SG_ 2499755967 FdEquipmentStatus5 3;
BA_ "GenSigMaxLatency" SG_ 2499755967 FdEquipmentStatus5 60;
BA_ "SeToolAncestorID_SIGNAL" SG_ 2499755967 FdEquipmentStatus5 "x0000001D04170A02";
BA_ "SeToolItemID_SIGNAL" SG_ 2499755967 FdEquipmentStatus5 "x0000001D04170A02";
BA_ "SeToolName_SIGNAL" SG_ 2499755967 FdEquipmentStatus5 "FdEquipmentStatus5";
BA_ "SeToolVersion_SIGNAL" SG_ 2499755967 FdEquipmentStatus5 "1";
BA_ "GenSigCycleTime" SG_ 2499755967 RideHeightFunctionStatus 100;
BA_ "GenSigCycleTimeActive" SG_ 2499755967 RideHeightFunctionStatus 100;
BA_ "GenSigStartValue" SG_ 2499755967 RideHeightFunctionStatus 15;
BA_ "GenSigMaxLatency" SG_ 2499755967 RideHeightFunctionStatus 60;
BA_ "SeToolAncestorID_SIGNAL" SG_ 2499755967 RideHeightFunctionStatus "x0000001D042186C7";
BA_ "SeToolItemID_SIGNAL" SG_ 2499755967 RideHeightFunctionStatus "x0000001D043FB877";
BA_ "SeToolName_SIGNAL" SG_ 2499755967 RideHeightFunctionStatus "RideHeightFunctionStatus";
BA_ "SeToolVersion_SIGNAL" SG_ 2499755967 RideHeightFunctionStatus "2";
BA_ "GenSigCycleTime" SG_ 2499755967 FdEquipmentStatus3 100;
BA_ "GenSigCycleTimeActive" SG_ 2499755967 FdEquipmentStatus3 100;
BA_ "GenSigStartValue" SG_ 2499755967 FdEquipmentStatus3 3;
BA_ "GenSigMaxLatency" SG_ 2499755967 FdEquipmentStatus3 60;
BA_ "SeToolAncestorID_SIGNAL" SG_ 2499755967 FdEquipmentStatus3 "x0000001D041709FE";
BA_ "SeToolItemID_SIGNAL" SG_ 2499755967 FdEquipmentStatus3 "x0000001D041709FE";
BA_ "SeToolName_SIGNAL" SG_ 2499755967 FdEquipmentStatus3 "FdEquipmentStatus3";
BA_ "SeToolVersion_SIGNAL" SG_ 2499755967 FdEquipmentStatus3 "1";
BA_ "GenSigCycleTime" SG_ 2499755967 FdEquipmentValue2 100;
BA_ "GenSigCycleTimeActive" SG_ 2499755967 FdEquipmentValue2 100;
BA_ "GenSigStartValue" SG_ 2499755967 FdEquipmentValue2 255;
BA_ "GenSigMaxLatency" SG_ 2499755967 FdEquipmentValue2 60;
BA_ "SeToolAncestorID_SIGNAL" SG_ 2499755967 FdEquipmentValue2 "x0000001D04171241";
BA_ "SeToolItemID_SIGNAL" SG_ 2499755967 FdEquipmentValue2 "x0000001D04171241";
BA_ "SeToolName_SIGNAL" SG_ 2499755967 FdEquipmentValue2 "FdEquipmentValue2";
BA_ "SeToolVersion_SIGNAL" SG_ 2499755967 FdEquipmentValue2 "1";
BA_ "GenSigCycleTime" SG_ 2499755967 FrontEndPositionStatus 100;
BA_ "GenSigCycleTimeActive" SG_ 2499755967 FrontEndPositionStatus 100;
BA_ "GenSigStartValue" SG_ 2499755967 FrontEndPositionStatus 7;
BA_ "GenSigMaxLatency" SG_ 2499755967 FrontEndPositionStatus 60;
BA_ "GenSigCycleTime" SG_ 2499755967 RollEndPositionStatus 100;
BA_ "GenSigCycleTimeActive" SG_ 2499755967 RollEndPositionStatus 100;
BA_ "GenSigStartValue" SG_ 2499755967 RollEndPositionStatus 7;
BA_ "GenSigMaxLatency" SG_ 2499755967 RollEndPositionStatus 60;
BA_ "GenSigCycleTime" SG_ 2499755967 RampLevelStatus 100;
BA_ "GenSigCycleTimeActive" SG_ 2499755967 RampLevelStatus 100;
BA_ "GenSigStartValue" SG_ 2499755967 RampLevelStatus 15;
BA_ "GenSigMaxLatency" SG_ 2499755967 RampLevelStatus 60;
BA_ "GenSigCycleTime" SG_ 2499755967 FdEquipmentValue1 100;
BA_ "GenSigCycleTimeActive" SG_ 2499755967 FdEquipmentValue1 100;
BA_ "GenSigStartValue" SG_ 2499755967 FdEquipmentValue1 255;
BA_ "GenSigMaxLatency" SG_ 2499755967 FdEquipmentValue1 60;
BA_ "SeToolAncestorID_SIGNAL" SG_ 2499755967 FdEquipmentValue1 "x0000001D0417123F";
BA_ "SeToolItemID_SIGNAL" SG_ 2499755967 FdEquipmentValue1 "x0000001D0417123F";
BA_ "SeToolName_SIGNAL" SG_ 2499755967 FdEquipmentValue1 "FdEquipmentValue1";
BA_ "SeToolVersion_SIGNAL" SG_ 2499755967 FdEquipmentValue1 "1";
BA_ "GenSigCycleTime" SG_ 2499755967 RampHeightOutsideTargetRange 100;
BA_ "GenSigCycleTimeActive" SG_ 2499755967 RampHeightOutsideTargetRange 100;
BA_ "GenSigStartValue" SG_ 2499755967 RampHeightOutsideTargetRange 7;
BA_ "GenSigMaxLatency" SG_ 2499755967 RampHeightOutsideTargetRange 60;
BA_ "GenSigCycleTime" SG_ 2499755967 FdEquipmentValue3 100;
BA_ "GenSigCycleTimeActive" SG_ 2499755967 FdEquipmentValue3 100;
BA_ "GenSigStartValue" SG_ 2499755967 FdEquipmentValue3 255;
BA_ "GenSigMaxLatency" SG_ 2499755967 FdEquipmentValue3 60;
BA_ "SeToolAncestorID_SIGNAL" SG_ 2499755967 FdEquipmentValue3 "x0000001D04171243";
BA_ "SeToolItemID_SIGNAL" SG_ 2499755967 FdEquipmentValue3 "x0000001D043A9096";
BA_ "SeToolName_SIGNAL" SG_ 2499755967 FdEquipmentValue3 "FdEquipmentValue3";
BA_ "SeToolVersion_SIGNAL" SG_ 2499755967 FdEquipmentValue3 "2";
BA_ "GenSigCycleTime" SG_ 2499755967 RearEndPositionStatus 100;
BA_ "GenSigCycleTimeActive" SG_ 2499755967 RearEndPositionStatus 100;
BA_ "GenSigStartValue" SG_ 2499755967 RearEndPositionStatus 7;
BA_ "GenSigMaxLatency" SG_ 2499755967 RearEndPositionStatus 60;
BA_ "GenSigCycleTime" SG_ 2432687168 Pto1Status 100;
BA_ "GenSigCycleTimeActive" SG_ 2432687168 Pto1Status 100;
BA_ "GenSigStartValue" SG_ 2432687168 Pto1Status 3;
BA_ "SeToolAncestorID_SIGNAL" SG_ 2432687168 Pto1Status "x0000001D041534A3";
BA_ "SeToolItemID_SIGNAL" SG_ 2432687168 Pto1Status "x0000001D04320FF9";
BA_ "SeToolName_SIGNAL" SG_ 2432687168 Pto1Status "Pto1Status";
BA_ "SeToolVersion_SIGNAL" SG_ 2432687168 Pto1Status "3";
BA_ "GenSigCycleTime" SG_ 2432687168 BodyOrCabWorkingLightFdbk_stat 100;
BA_ "GenSigCycleTimeActive" SG_ 2432687168 BodyOrCabWorkingLightFdbk_stat 100;
BA_ "GenSigStartValue" SG_ 2432687168 BodyOrCabWorkingLightFdbk_stat 3;
BA_ "SeToolAncestorID_SIGNAL" SG_ 2432687168 BodyOrCabWorkingLightFdbk_stat "x0000001D041B0A46";
BA_ "SeToolItemID_SIGNAL" SG_ 2432687168 BodyOrCabWorkingLightFdbk_stat "x0000001D041B0A46";
BA_ "SeToolName_SIGNAL" SG_ 2432687168 BodyOrCabWorkingLightFdbk_stat "CabBody/CabWorkingLightFeedback_Status";
BA_ "SeToolVersion_SIGNAL" SG_ 2432687168 BodyOrCabWorkingLightFdbk_stat "1";
BA_ "GenSigCycleTime" SG_ 2432687168 ElectricalLoadReduction_rqst 100;
BA_ "GenSigCycleTimeActive" SG_ 2432687168 ElectricalLoadReduction_rqst 100;
BA_ "GenSigStartValue" SG_ 2432687168 ElectricalLoadReduction_rqst 7;
BA_ "NeedsUpdateBit" SG_ 2432687168 ElectricalLoadReduction_rqst 1;
BA_ "GenSigCycleTime" SG_ 2432687168 AirbagTelltale_stat 100;
BA_ "GenSigCycleTimeActive" SG_ 2432687168 AirbagTelltale_stat 100;
BA_ "GenSigStartValue" SG_ 2432687168 AirbagTelltale_stat 3;
BA_ "GenSigCycleTime" SG_ 2432687168 CabWrknLightChassisFdbk_stat 100;
BA_ "GenSigCycleTimeActive" SG_ 2432687168 CabWrknLightChassisFdbk_stat 100;
BA_ "GenSigStartValue" SG_ 2432687168 CabWrknLightChassisFdbk_stat 3;
BA_ "SeToolAncestorID_SIGNAL" SG_ 2432687168 CabWrknLightChassisFdbk_stat "x0000001D041B0A49";
BA_ "SeToolItemID_SIGNAL" SG_ 2432687168 CabWrknLightChassisFdbk_stat "x0000001D041B0A49";
BA_ "SeToolName_SIGNAL" SG_ 2432687168 CabWrknLightChassisFdbk_stat "CabWorkingLightChassisFeedback_Status";
BA_ "SeToolVersion_SIGNAL" SG_ 2432687168 CabWrknLightChassisFdbk_stat "1";
BA_ "GenSigCycleTime" SG_ 2432687168 ExtraBBTailLiftStatus 100;
BA_ "GenSigCycleTimeActive" SG_ 2432687168 ExtraBBTailLiftStatus 100;
BA_ "GenSigStartValue" SG_ 2432687168 ExtraBBTailLiftStatus 3;
BA_ "GenSigCycleTime" SG_ 2432687168 TotalVehicleDistanceHighRes 100;
BA_ "GenSigCycleTimeActive" SG_ 2432687168 TotalVehicleDistanceHighRes 100;
BA_ "GenSigStartValue" SG_ 2432687168 TotalVehicleDistanceHighRes 4294967295;
BA_ "GenSigMaxLatency" SG_ 2432687168 TotalVehicleDistanceHighRes 26;
BA_ "SeToolAncestorID_SIGNAL" SG_ 2432687168 TotalVehicleDistanceHighRes "x0000001D04109E2B";
BA_ "SeToolItemID_SIGNAL" SG_ 2432687168 TotalVehicleDistanceHighRes "x0000001D04109E2B";
BA_ "SeToolName_SIGNAL" SG_ 2432687168 TotalVehicleDistanceHighRes "HighResolutionTotalVehicleDistance";
BA_ "SeToolVersion_SIGNAL" SG_ 2432687168 TotalVehicleDistanceHighRes "1";
BA_ "GenSigSendType" SG_ 2432687168 ElectricalLoadReduction_rqst_UB 7;
BA_ "GenSigCycleTime" SG_ 2432687168 ExtraBBCraneStatus 100;
BA_ "GenSigCycleTimeActive" SG_ 2432687168 ExtraBBCraneStatus 100;
BA_ "GenSigStartValue" SG_ 2432687168 ExtraBBCraneStatus 7;
BA_ "GenSigCycleTime" SG_ 2432687168 Pto3Status 100;
BA_ "GenSigCycleTimeActive" SG_ 2432687168 Pto3Status 100;
BA_ "GenSigStartValue" SG_ 2432687168 Pto3Status 3;
BA_ "SeToolAncestorID_SIGNAL" SG_ 2432687168 Pto3Status "x0000001D041534A7";
BA_ "SeToolItemID_SIGNAL" SG_ 2432687168 Pto3Status "x0000001D04321034";
BA_ "SeToolName_SIGNAL" SG_ 2432687168 Pto3Status "Pto3Status";
BA_ "SeToolVersion_SIGNAL" SG_ 2432687168 Pto3Status "3";
BA_ "GenSigCycleTime" SG_ 2432687168 AirBleedValveStat 100;
BA_ "GenSigCycleTimeActive" SG_ 2432687168 AirBleedValveStat 100;
BA_ "GenSigStartValue" SG_ 2432687168 AirBleedValveStat 3;
BA_ "GenSigCycleTime" SG_ 2432687168 CabExtraSideWrknLightFdbk_stat 100;
BA_ "GenSigCycleTimeActive" SG_ 2432687168 CabExtraSideWrknLightFdbk_stat 100;
BA_ "GenSigStartValue" SG_ 2432687168 CabExtraSideWrknLightFdbk_stat 3;
BA_ "SeToolAncestorID_SIGNAL" SG_ 2432687168 CabExtraSideWrknLightFdbk_stat "x0000001D041B0A4B";
BA_ "SeToolItemID_SIGNAL" SG_ 2432687168 CabExtraSideWrknLightFdbk_stat "x0000001D041B0A4B";
BA_ "SeToolName_SIGNAL" SG_ 2432687168 CabExtraSideWrknLightFdbk_stat "CabExtraSideWorkingFeedback_Status";
BA_ "SeToolVersion_SIGNAL" SG_ 2432687168 CabExtraSideWrknLightFdbk_stat "1";
BA_ "GenSigCycleTime" SG_ 2432687168 Pto2Status 100;
BA_ "GenSigCycleTimeActive" SG_ 2432687168 Pto2Status 100;
BA_ "GenSigStartValue" SG_ 2432687168 Pto2Status 3;
BA_ "SeToolAncestorID_SIGNAL" SG_ 2432687168 Pto2Status "x0000001D041534A5";
BA_ "SeToolItemID_SIGNAL" SG_ 2432687168 Pto2Status "x0000001D04321002";
BA_ "SeToolName_SIGNAL" SG_ 2432687168 Pto2Status "Pto2Status";
BA_ "SeToolVersion_SIGNAL" SG_ 2432687168 Pto2Status "3";
BA_ "GenSigCycleTime" SG_ 2432687168 CabBeaconLightFeedback_Status 100;
BA_ "GenSigCycleTimeActive" SG_ 2432687168 CabBeaconLightFeedback_Status 100;
BA_ "GenSigStartValue" SG_ 2432687168 CabBeaconLightFeedback_Status 3;
BA_ "SeToolAncestorID_SIGNAL" SG_ 2432687168 CabBeaconLightFeedback_Status "x0000001D041B0A09";
BA_ "SeToolItemID_SIGNAL" SG_ 2432687168 CabBeaconLightFeedback_Status "x0000001D041B0A09";
BA_ "SeToolName_SIGNAL" SG_ 2432687168 CabBeaconLightFeedback_Status "CabBeaconLightFeedback_Status";
BA_ "SeToolVersion_SIGNAL" SG_ 2432687168 CabBeaconLightFeedback_Status "1";
BA_ "GenSigCycleTime" SG_ 2432687168 AudioSourceStatus 100;
BA_ "GenSigCycleTimeActive" SG_ 2432687168 AudioSourceStatus 100;
BA_ "GenSigStartValue" SG_ 2432687168 AudioSourceStatus 7;
BA_ "GenSigCycleTime" SG_ 2432687168 Pto4Status 100;
BA_ "GenSigCycleTimeActive" SG_ 2432687168 Pto4Status 100;
BA_ "GenSigStartValue" SG_ 2432687168 Pto4Status 3;
BA_ "SeToolAncestorID_SIGNAL" SG_ 2432687168 Pto4Status "x0000001D041534AC";
BA_ "SeToolItemID_SIGNAL" SG_ 2432687168 Pto4Status "x0000001D04321056";
BA_ "SeToolName_SIGNAL" SG_ 2432687168 Pto4Status "Pto4Status";
BA_ "SeToolVersion_SIGNAL" SG_ 2432687168 Pto4Status "3";
BA_ "GenSigCycleTime" SG_ 2550121792 DayLocal 100;
BA_ "GenSigCycleTimeActive" SG_ 2550121792 DayLocal 100;
BA_ "GenSigStartValue" SG_ 2550121792 DayLocal 255;
BA_ "GenSigCycleTime" SG_ 2550121792 SecondsLocal 100;
BA_ "GenSigCycleTimeActive" SG_ 2550121792 SecondsLocal 100;
BA_ "GenSigStartValue" SG_ 2550121792 SecondsLocal 255;
BA_ "GenSigCycleTime" SG_ 2550121792 YearLocal 100;
BA_ "GenSigCycleTimeActive" SG_ 2550121792 YearLocal 100;
BA_ "GenSigStartValue" SG_ 2550121792 YearLocal 255;
BA_ "GenSigCycleTime" SG_ 2550121792 ParkingHeaterCleaning_cmd 100;
BA_ "GenSigCycleTimeActive" SG_ 2550121792 ParkingHeaterCleaning_cmd 100;
BA_ "GenSigStartValue" SG_ 2550121792 ParkingHeaterCleaning_cmd 3;
BA_ "GenSigCycleTime" SG_ 2550121792 LivBatteryCharging_stat 100;
BA_ "GenSigCycleTimeActive" SG_ 2550121792 LivBatteryCharging_stat 100;
BA_ "GenSigStartValue" SG_ 2550121792 LivBatteryCharging_stat 3;
BA_ "GenSigCycleTime" SG_ 2550121792 MinutesLocal 100;
BA_ "GenSigCycleTimeActive" SG_ 2550121792 MinutesLocal 100;
BA_ "GenSigStartValue" SG_ 2550121792 MinutesLocal 255;
BA_ "GenSigCycleTime" SG_ 2550121792 BatterySOCAlertRawData_rqst 100;
BA_ "GenSigCycleTimeActive" SG_ 2550121792 BatterySOCAlertRawData_rqst 100;
BA_ "GenSigStartValue" SG_ 2550121792 BatterySOCAlertRawData_rqst 7;
BA_ "GenSigCycleTime" SG_ 2550121792 HoursLocal 100;
BA_ "GenSigCycleTimeActive" SG_ 2550121792 HoursLocal 100;
BA_ "GenSigStartValue" SG_ 2550121792 HoursLocal 255;
BA_ "GenSigCycleTime" SG_ 2550121792 MonthLocal 100;
BA_ "GenSigCycleTimeActive" SG_ 2550121792 MonthLocal 100;
BA_ "GenSigStartValue" SG_ 2550121792 MonthLocal 255;
BA_REL_ "GenSigFirstTimeoutTime" BU_SG_REL_ WRCS SG_ 2565837120 CalLoadTrailer1Axle3 24000;
BA_REL_ "GenSigTimeoutTime" BU_SG_REL_ WRCS SG_ 2565837120 CalLoadTrailer1Axle3 6000;
BA_REL_ "GenSigFirstTimeoutTime" BU_SG_REL_ WRCS SG_ 2565837120 CalLoadTrailer1Axle1 24000;
BA_REL_ "GenSigTimeoutTime" BU_SG_REL_ WRCS SG_ 2565837120 CalLoadTrailer1Axle1 6000;
BA_REL_ "GenSigFirstTimeoutTime" BU_SG_REL_ WRCS SG_ 2565837120 CalLoadTrailer1Axle2 24000;
BA_REL_ "GenSigTimeoutTime" BU_SG_REL_ WRCS SG_ 2565837120 CalLoadTrailer1Axle2 6000;
BA_REL_ "GenSigFirstTimeoutTime" BU_SG_REL_ WRCS SG_ 2565837120 CalLoadTrailer1Axle4 24000;
BA_REL_ "GenSigTimeoutTime" BU_SG_REL_ WRCS SG_ 2565837120 CalLoadTrailer1Axle4 6000;
BA_REL_ "GenSigFirstTimeoutTime" BU_SG_REL_ SRS SG_ 2566357312 GPSData_VehSpeed 12000;
BA_REL_ "GenSigTimeoutTime" BU_SG_REL_ SRS SG_ 2566357312 GPSData_VehSpeed 3000;
BA_REL_ "GenSigFirstTimeoutTime" BU_SG_REL_ SRS SG_ 2566357312 GPSData_HDOP 12000;
BA_REL_ "GenSigTimeoutTime" BU_SG_REL_ SRS SG_ 2566357312 GPSData_HDOP 3000;
BA_REL_ "GenSigFirstTimeoutTime" BU_SG_REL_ SRS SG_ 2566357312 GPSData_Direction 12000;
BA_REL_ "GenSigTimeoutTime" BU_SG_REL_ SRS SG_ 2566357312 GPSData_Direction 3000;
BA_REL_ "GenSigFirstTimeoutTime" BU_SG_REL_ SRS SG_ 2566357312 GPSData_Longitude 12000;
BA_REL_ "GenSigTimeoutTime" BU_SG_REL_ SRS SG_ 2566357312 GPSData_Longitude 3000;
BA_REL_ "GenSigFirstTimeoutTime" BU_SG_REL_ SRS SG_ 2566357312 GPSData_AntennaStat 12000;
BA_REL_ "GenSigTimeoutTime" BU_SG_REL_ SRS SG_ 2566357312 GPSData_AntennaStat 3000;
BA_REL_ "GenSigFirstTimeoutTime" BU_SG_REL_ SRS SG_ 2566357312 GPSData_Latitude 12000;
BA_REL_ "GenSigTimeoutTime" BU_SG_REL_ SRS SG_ 2566357312 GPSData_Latitude 3000;
BA_REL_ "GenSigFirstTimeoutTime" BU_SG_REL_ SRS SG_ 2566357312 GPSData_Altitude 12000;
BA_REL_ "GenSigTimeoutTime" BU_SG_REL_ SRS SG_ 2566357312 GPSData_Altitude 3000;
BA_REL_ "GenSigFirstTimeoutTime" BU_SG_REL_ SRS SG_ 2566357312 GPSData_Time 12000;
BA_REL_ "GenSigTimeoutTime" BU_SG_REL_ SRS SG_ 2566357312 GPSData_Time 3000;
BA_REL_ "GenSigFirstTimeoutTime" BU_SG_REL_ CMS SG_ 2432680000 YawRate 3000;
BA_REL_ "GenSigTimeoutTime" BU_SG_REL_ CMS SG_ 2432680000 YawRate 100;
BA_REL_ "GenSigFirstTimeoutTime" BU_SG_REL_ SRS SG_ 2432680000 BrakePedalPosition 3000;
BA_REL_ "GenSigTimeoutTime" BU_SG_REL_ SRS SG_ 2432680000 BrakePedalPosition 60;
BA_REL_ "GenSigFirstTimeoutTime" BU_SG_REL_ CMS SG_ 2432680000 SteeringWheelAngle 3000;
BA_REL_ "GenSigTimeoutTime" BU_SG_REL_ CMS SG_ 2432680000 SteeringWheelAngle 100;
BA_REL_ "GenSigFirstTimeoutTime" BU_SG_REL_ SRS SG_ 2432680000 SteeringWheelAngle 3000;
BA_REL_ "GenSigTimeoutTime" BU_SG_REL_ SRS SG_ 2432680000 SteeringWheelAngle 60;
BA_REL_ "GenSigFirstTimeoutTime" BU_SG_REL_ CMS SG_ 2432647232 DirInd_StalkStatus_1 3000;
BA_REL_ "GenSigTimeoutTime" BU_SG_REL_ CMS SG_ 2432647232 DirInd_StalkStatus_1 120;
BA_REL_ "GenSigFirstTimeoutTime" BU_SG_REL_ CMS SG_ 2432647232 CMSPanning_rqst 3000;
BA_REL_ "GenSigTimeoutTime" BU_SG_REL_ CMS SG_ 2432647232 CMSPanning_rqst 120;
BA_REL_ "GenSigFirstTimeoutTime" BU_SG_REL_ SRS SG_ 2432647232 CM_Status 3000;
BA_REL_ "GenSigTimeoutTime" BU_SG_REL_ SRS SG_ 2432647232 CM_Status 120;
BA_REL_ "GenSigFirstTimeoutTime" BU_SG_REL_ CMS SG_ 2432647232 CameraAdj_rqst 3000;
BA_REL_ "GenSigTimeoutTime" BU_SG_REL_ CMS SG_ 2432647232 CameraAdj_rqst 120;
BA_REL_ "GenSigFirstTimeoutTime" BU_SG_REL_ CMS SG_ 2432647232 CameraSelection_rqst 3000;
BA_REL_ "GenSigTimeoutTime" BU_SG_REL_ CMS SG_ 2432647232 CameraSelection_rqst 120;
BA_REL_ "GenSigFirstTimeoutTime" BU_SG_REL_ CMS SG_ 2432647232 LCS_WarningStatusRight 3000;
BA_REL_ "GenSigTimeoutTime" BU_SG_REL_ CMS SG_ 2432647232 LCS_WarningStatusRight 120;
BA_REL_ "GenSigFirstTimeoutTime" BU_SG_REL_ CMS SG_ 2432647232 GearLeverPosition 3000;
BA_REL_ "GenSigTimeoutTime" BU_SG_REL_ CMS SG_ 2432647232 GearLeverPosition 120;
BA_REL_ "GenSigFirstTimeoutTime" BU_SG_REL_ SRS SG_ 2432647232 PassengersSeatBelt 3000;
BA_REL_ "GenSigTimeoutTime" BU_SG_REL_ SRS SG_ 2432647232 PassengersSeatBelt 120;
BA_REL_ "GenSigFirstTimeoutTime" BU_SG_REL_ CMS SG_ 2432647232 LCS_WarningStatusLeft 3000;
BA_REL_ "GenSigTimeoutTime" BU_SG_REL_ CMS SG_ 2432647232 LCS_WarningStatusLeft 120;
BA_REL_ "GenSigFirstTimeoutTime" BU_SG_REL_ CMS SG_ 2432647232 CMSClassVActDeact_rqst 3000;
BA_REL_ "GenSigTimeoutTime" BU_SG_REL_ CMS SG_ 2432647232 CMSClassVActDeact_rqst 120;
BA_REL_ "GenSigFirstTimeoutTime" BU_SG_REL_ CMS SG_ 2432647232 CMSBacklightCmd 3000;
BA_REL_ "GenSigTimeoutTime" BU_SG_REL_ CMS SG_ 2432647232 CMSBacklightCmd 120;
BA_REL_ "GenSigFirstTimeoutTime" BU_SG_REL_ CCM SG_ 2516193600 ReqHVILmonitoring 3000;
BA_REL_ "GenSigTimeoutTime" BU_SG_REL_ CCM SG_ 2516193600 ReqHVILmonitoring 600;
BA_REL_ "GenSigFirstTimeoutTime" BU_SG_REL_ CCM SG_ 2516193600 AuxTVSStatus 3000;
BA_REL_ "GenSigTimeoutTime" BU_SG_REL_ CCM SG_ 2516193600 AuxTVSStatus 600;
BA_REL_ "GenSigFirstTimeoutTime" BU_SG_REL_ SRS SG_ 2516193600 ActualDrvlnRetdrPercentTorque 3000;
BA_REL_ "GenSigTimeoutTime" BU_SG_REL_ SRS SG_ 2516193600 ActualDrvlnRetdrPercentTorque 600;
BA_REL_ "GenSigFirstTimeoutTime" BU_SG_REL_ WRCS SG_ 2516193600 Trailer2LiftAxle2Pos 3000;
BA_REL_ "GenSigTimeoutTime" BU_SG_REL_ WRCS SG_ 2516193600 Trailer2LiftAxle2Pos 600;
BA_REL_ "GenSigFirstTimeoutTime" BU_SG_REL_ WRCS SG_ 2516193600 Trailer3LiftAxle2Pos 3000;
BA_REL_ "GenSigTimeoutTime" BU_SG_REL_ WRCS SG_ 2516193600 Trailer3LiftAxle2Pos 600;
BA_REL_ "GenSigFirstTimeoutTime" BU_SG_REL_ SRS SG_ 2516193600 ROPBrakeControlActive 3000;
BA_REL_ "GenSigTimeoutTime" BU_SG_REL_ SRS SG_ 2516193600 ROPBrakeControlActive 600;
BA_REL_ "GenSigFirstTimeoutTime" BU_SG_REL_ CCM SG_ 2516193600 TransmissionDrivingMode 3000;
BA_REL_ "GenSigTimeoutTime" BU_SG_REL_ CCM SG_ 2516193600 TransmissionDrivingMode 600;
BA_REL_ "GenSigFirstTimeoutTime" BU_SG_REL_ WRCS SG_ 2516193600 Trailer5LiftAxle1Pos 3000;
BA_REL_ "GenSigTimeoutTime" BU_SG_REL_ WRCS SG_ 2516193600 Trailer5LiftAxle1Pos 600;
BA_REL_ "GenSigFirstTimeoutTime" BU_SG_REL_ WRCS SG_ 2516193600 Trailer1LiftAxle2Pos 3000;
BA_REL_ "GenSigTimeoutTime" BU_SG_REL_ WRCS SG_ 2516193600 Trailer1LiftAxle2Pos 600;
BA_REL_ "GenSigFirstTimeoutTime" BU_SG_REL_ CCM SG_ 2516193600 TVSDischargeRequest 3000;
BA_REL_ "GenSigTimeoutTime" BU_SG_REL_ CCM SG_ 2516193600 TVSDischargeRequest 600;
BA_REL_ "GenSigFirstTimeoutTime" BU_SG_REL_ SRS SG_ 2516193600 FoundationBrakeUse 3000;
BA_REL_ "GenSigTimeoutTime" BU_SG_REL_ SRS SG_ 2516193600 FoundationBrakeUse 600;
BA_REL_ "GenSigFirstTimeoutTime" BU_SG_REL_ WRCS SG_ 2516193600 Trailer4LiftAxle1Pos 3000;
BA_REL_ "GenSigTimeoutTime" BU_SG_REL_ WRCS SG_ 2516193600 Trailer4LiftAxle1Pos 600;
BA_REL_ "GenSigFirstTimeoutTime" BU_SG_REL_ WRCS SG_ 2516193600 Trailer5LiftAxle2Pos 3000;
BA_REL_ "GenSigTimeoutTime" BU_SG_REL_ WRCS SG_ 2516193600 Trailer5LiftAxle2Pos 600;
BA_REL_ "GenSigFirstTimeoutTime" BU_SG_REL_ CCM SG_ 2516193600 BlackPanel_stat 3000;
BA_REL_ "GenSigTimeoutTime" BU_SG_REL_ CCM SG_ 2516193600 BlackPanel_stat 600;
BA_REL_ "GenSigFirstTimeoutTime" BU_SG_REL_ WRCS SG_ 2516193600 Trailer4LiftAxle2Pos 3000;
BA_REL_ "GenSigTimeoutTime" BU_SG_REL_ WRCS SG_ 2516193600 Trailer4LiftAxle2Pos 600;
BA_REL_ "GenSigFirstTimeoutTime" BU_SG_REL_ SRS SG_ 2516193600 AntiLockBrakingActive 3000;
BA_REL_ "GenSigTimeoutTime" BU_SG_REL_ SRS SG_ 2516193600 AntiLockBrakingActive 600;
BA_REL_ "GenSigFirstTimeoutTime" BU_SG_REL_ SRS SG_ 2516193600 YCBrakeControlActive 3000;
BA_REL_ "GenSigTimeoutTime" BU_SG_REL_ SRS SG_ 2516193600 YCBrakeControlActive 600;
BA_REL_ "GenSigFirstTimeoutTime" BU_SG_REL_ SRS SG_ 2516193600 ActualEngineRetarderPercentTrq 3000;
BA_REL_ "GenSigTimeoutTime" BU_SG_REL_ SRS SG_ 2516193600 ActualEngineRetarderPercentTrq 600;
BA_REL_ "GenSigFirstTimeoutTime" BU_SG_REL_ CCM SG_ 2516193600 EngineTmpryStopStartStatus 3000;
BA_REL_ "GenSigTimeoutTime" BU_SG_REL_ CCM SG_ 2516193600 EngineTmpryStopStartStatus 600;
BA_REL_ "GenSigFirstTimeoutTime" BU_SG_REL_ WRCS SG_ 2516193600 Trailer1LiftAxle1Pos 3000;
BA_REL_ "GenSigTimeoutTime" BU_SG_REL_ WRCS SG_ 2516193600 Trailer1LiftAxle1Pos 600;
BA_REL_ "GenSigFirstTimeoutTime" BU_SG_REL_ WRCS SG_ 2516193600 Trailer3LiftAxle1Pos 3000;
BA_REL_ "GenSigTimeoutTime" BU_SG_REL_ WRCS SG_ 2516193600 Trailer3LiftAxle1Pos 600;
BA_REL_ "GenSigFirstTimeoutTime" BU_SG_REL_ WRCS SG_ 2516193600 Trailer2LiftAxle1Pos 3000;
BA_REL_ "GenSigTimeoutTime" BU_SG_REL_ WRCS SG_ 2516193600 Trailer2LiftAxle1Pos 600;
BA_REL_ "GenSigFirstTimeoutTime" BU_SG_REL_ LECM1 SG_ 2493989952 SEMMediaSourceAvail_Source07 3000;
BA_REL_ "GenSigTimeoutTime" BU_SG_REL_ LECM1 SG_ 2493989952 SEMMediaSourceAvail_Source07 300;
BA_REL_ "GenSigFirstTimeoutTime" BU_SG_REL_ LECM1 SG_ 2493989952 SEMMediaSourceAvail_Source06 3000;
BA_REL_ "GenSigTimeoutTime" BU_SG_REL_ LECM1 SG_ 2493989952 SEMMediaSourceAvail_Source06 300;
BA_REL_ "GenSigFirstTimeoutTime" BU_SG_REL_ CCM SG_ 2493989952 AutoBlowerLevelRqst 6000;
BA_REL_ "GenSigTimeoutTime" BU_SG_REL_ CCM SG_ 2493989952 AutoBlowerLevelRqst 300;
BA_REL_ "GenSigFirstTimeoutTime" BU_SG_REL_ LECM1 SG_ 2493989952 SEMMediaSourceAvail_Source08 3000;
BA_REL_ "GenSigTimeoutTime" BU_SG_REL_ LECM1 SG_ 2493989952 SEMMediaSourceAvail_Source08 300;
BA_REL_ "GenSigFirstTimeoutTime" BU_SG_REL_ LECM1 SG_ 2493989952 SEMMediaSourceAvail_Source00 3000;
BA_REL_ "GenSigTimeoutTime" BU_SG_REL_ LECM1 SG_ 2493989952 SEMMediaSourceAvail_Source00 300;
BA_REL_ "GenSigFirstTimeoutTime" BU_SG_REL_ LECM1 SG_ 2493989952 SEM_AudioMuteStat 3000;
BA_REL_ "GenSigTimeoutTime" BU_SG_REL_ LECM1 SG_ 2493989952 SEM_AudioMuteStat 300;
BA_REL_ "GenSigFirstTimeoutTime" BU_SG_REL_ LECM1 SG_ 2493989952 SEMMediaSourceAvail_Source09 3000;
BA_REL_ "GenSigTimeoutTime" BU_SG_REL_ LECM1 SG_ 2493989952 SEMMediaSourceAvail_Source09 300;
BA_REL_ "GenSigFirstTimeoutTime" BU_SG_REL_ LECM1 SG_ 2493989952 SEMMediaSourceAvail_Source13 3000;
BA_REL_ "GenSigTimeoutTime" BU_SG_REL_ LECM1 SG_ 2493989952 SEMMediaSourceAvail_Source13 300;
BA_REL_ "GenSigFirstTimeoutTime" BU_SG_REL_ LECM1 SG_ 2493989952 SEMMediaSourceAvail_Source04 3000;
BA_REL_ "GenSigTimeoutTime" BU_SG_REL_ LECM1 SG_ 2493989952 SEMMediaSourceAvail_Source04 300;
BA_REL_ "GenSigFirstTimeoutTime" BU_SG_REL_ LECM1 SG_ 2493989952 SEMMediaSourceAvail_Source05 3000;
BA_REL_ "GenSigTimeoutTime" BU_SG_REL_ LECM1 SG_ 2493989952 SEMMediaSourceAvail_Source05 300;
BA_REL_ "GenSigFirstTimeoutTime" BU_SG_REL_ LECM1 SG_ 2493989952 SEMMediaSourceAvail_Source02 3000;
BA_REL_ "GenSigTimeoutTime" BU_SG_REL_ LECM1 SG_ 2493989952 SEMMediaSourceAvail_Source02 300;
BA_REL_ "GenSigFirstTimeoutTime" BU_SG_REL_ LECM1 SG_ 2493989952 SEMMediaSourceAvail_SInfo 3000;
BA_REL_ "GenSigTimeoutTime" BU_SG_REL_ LECM1 SG_ 2493989952 SEMMediaSourceAvail_SInfo 300;
BA_REL_ "GenSigFirstTimeoutTime" BU_SG_REL_ CCM SG_ 2493989952 AQSModeRqst 6000;
BA_REL_ "GenSigTimeoutTime" BU_SG_REL_ CCM SG_ 2493989952 AQSModeRqst 300;
BA_REL_ "GenSigFirstTimeoutTime" BU_SG_REL_ LECM1 SG_ 2493989952 AudioSourceStat 3000;
BA_REL_ "GenSigTimeoutTime" BU_SG_REL_ LECM1 SG_ 2493989952 AudioSourceStat 300;
BA_REL_ "GenSigFirstTimeoutTime" BU_SG_REL_ LECM1 SG_ 2493989952 SEMMediaSourceAvail_Source11 3000;
BA_REL_ "GenSigTimeoutTime" BU_SG_REL_ LECM1 SG_ 2493989952 SEMMediaSourceAvail_Source11 300;
BA_REL_ "GenSigFirstTimeoutTime" BU_SG_REL_ LECM1 SG_ 2493989952 SEMMediaSourceAvail_Source10 3000;
BA_REL_ "GenSigTimeoutTime" BU_SG_REL_ LECM1 SG_ 2493989952 SEMMediaSourceAvail_Source10 300;
BA_REL_ "GenSigFirstTimeoutTime" BU_SG_REL_ CCM SG_ 2493989952 ACModeRqst 6000;
BA_REL_ "GenSigTimeoutTime" BU_SG_REL_ CCM SG_ 2493989952 ACModeRqst 300;
BA_REL_ "GenSigFirstTimeoutTime" BU_SG_REL_ CCM SG_ 2493989952 ESS_TRDStatus 3000;
BA_REL_ "GenSigTimeoutTime" BU_SG_REL_ CCM SG_ 2493989952 ESS_TRDStatus 300;
BA_REL_ "GenSigFirstTimeoutTime" BU_SG_REL_ CCM SG_ 2493989952 AutoDefogModeRqst 6000;
BA_REL_ "GenSigTimeoutTime" BU_SG_REL_ CCM SG_ 2493989952 AutoDefogModeRqst 300;
BA_REL_ "GenSigFirstTimeoutTime" BU_SG_REL_ LECM1 SG_ 2493989952 SEM_AudioVolValIndCmd 3000;
BA_REL_ "GenSigTimeoutTime" BU_SG_REL_ LECM1 SG_ 2493989952 SEM_AudioVolValIndCmd 300;
BA_REL_ "GenSigFirstTimeoutTime" BU_SG_REL_ LECM1 SG_ 2493989952 SEMMediaSourceAvail_Source01 3000;
BA_REL_ "GenSigTimeoutTime" BU_SG_REL_ LECM1 SG_ 2493989952 SEMMediaSourceAvail_Source01 300;
BA_REL_ "GenSigFirstTimeoutTime" BU_SG_REL_ CCM SG_ 2493989952 EngineActiveStatus 3000;
BA_REL_ "GenSigTimeoutTime" BU_SG_REL_ CCM SG_ 2493989952 EngineActiveStatus 300;
BA_REL_ "GenSigFirstTimeoutTime" BU_SG_REL_ LECM1 SG_ 2493989952 SEMMediaSourceAvail_Source03 3000;
BA_REL_ "GenSigTimeoutTime" BU_SG_REL_ LECM1 SG_ 2493989952 SEMMediaSourceAvail_Source03 300;
BA_REL_ "GenSigFirstTimeoutTime" BU_SG_REL_ LECM1 SG_ 2493989952 SEM_PresetIndicationCmd 3000;
BA_REL_ "GenSigTimeoutTime" BU_SG_REL_ LECM1 SG_ 2493989952 SEM_PresetIndicationCmd 300;
BA_REL_ "GenSigFirstTimeoutTime" BU_SG_REL_ LECM1 SG_ 2493989952 SEMMediaSourceAvail_Source12 3000;
BA_REL_ "GenSigTimeoutTime" BU_SG_REL_ LECM1 SG_ 2493989952 SEMMediaSourceAvail_Source12 300;
BA_REL_ "GenSigFirstTimeoutTime" BU_SG_REL_ CCM SG_ 2499754560 InhibitTVSReq 3000;
BA_REL_ "GenSigTimeoutTime" BU_SG_REL_ CCM SG_ 2499754560 InhibitTVSReq 300;
BA_REL_ "GenSigFirstTimeoutTime" BU_SG_REL_ WRCS SG_ 2499754560 TipperEmergencyStopStatus 3000;
BA_REL_ "GenSigTimeoutTime" BU_SG_REL_ WRCS SG_ 2499754560 TipperEmergencyStopStatus 300;
BA_REL_ "GenSigFirstTimeoutTime" BU_SG_REL_ WRCS SG_ 2499754560 TipperPrimaryBodyStatus 3000;
BA_REL_ "GenSigTimeoutTime" BU_SG_REL_ WRCS SG_ 2499754560 TipperPrimaryBodyStatus 300;
BA_REL_ "GenSigFirstTimeoutTime" BU_SG_REL_ WRCS SG_ 2499754560 TipperConditionsStatus 3000;
BA_REL_ "GenSigTimeoutTime" BU_SG_REL_ WRCS SG_ 2499754560 TipperConditionsStatus 300;
BA_REL_ "GenSigFirstTimeoutTime" BU_SG_REL_ WRCS SG_ 2499754560 TipperSecondaryBodyStatus 3000;
BA_REL_ "GenSigTimeoutTime" BU_SG_REL_ WRCS SG_ 2499754560 TipperSecondaryBodyStatus 300;
BA_REL_ "GenSigFirstTimeoutTime" BU_SG_REL_ WRCS SG_ 2499754560 BatterySOCAlert_rqst 3000;
BA_REL_ "GenSigTimeoutTime" BU_SG_REL_ WRCS SG_ 2499754560 BatterySOCAlert_rqst 300;
BA_REL_ "GenSigFirstTimeoutTime" BU_SG_REL_ SRS SG_ 2499754560 CCStates 3000;
BA_REL_ "GenSigTimeoutTime" BU_SG_REL_ SRS SG_ 2499754560 CCStates 200;
BA_REL_ "GenSigFirstTimeoutTime" BU_SG_REL_ CCM SG_ 2499754560 ExtraHeating_rqst 3000;
BA_REL_ "GenSigTimeoutTime" BU_SG_REL_ CCM SG_ 2499754560 ExtraHeating_rqst 300;
BA_REL_ "GenSigFirstTimeoutTime" BU_SG_REL_ SRS SG_ 2499754560 LongMotionDirection 3000;
BA_REL_ "GenSigTimeoutTime" BU_SG_REL_ SRS SG_ 2499754560 LongMotionDirection 300;
BA_REL_ "GenSigFirstTimeoutTime" BU_SG_REL_ WRCS SG_ 2499754560 TipperUpDownStatus 3000;
BA_REL_ "GenSigTimeoutTime" BU_SG_REL_ WRCS SG_ 2499754560 TipperUpDownStatus 300;
BA_REL_ "GenSigFirstTimeoutTime" BU_SG_REL_ WRCS SG_ 2499754560 TipperTailGateStatus 3000;
BA_REL_ "GenSigTimeoutTime" BU_SG_REL_ WRCS SG_ 2499754560 TipperTailGateStatus 300;
BA_REL_ "GenSigFirstTimeoutTime" BU_SG_REL_ WRCS SG_ 2499754560 KneelingInformation 3000;
BA_REL_ "GenSigTimeoutTime" BU_SG_REL_ WRCS SG_ 2499754560 KneelingInformation 300;
BA_REL_ "GenSigFirstTimeoutTime" BU_SG_REL_ WRCS SG_ 2499754560 TailLiftRemoteNotAllowed 3000;
BA_REL_ "GenSigTimeoutTime" BU_SG_REL_ WRCS SG_ 2499754560 TailLiftRemoteNotAllowed 300;
BA_REL_ "GenSigFirstTimeoutTime" BU_SG_REL_ CMS SG_ 2499754560 DirectionIndicatorActive_stat 3000;
BA_REL_ "GenSigTimeoutTime" BU_SG_REL_ CMS SG_ 2499754560 DirectionIndicatorActive_stat 300;
BA_REL_ "GenSigFirstTimeoutTime" BU_SG_REL_ WRCS SG_ 2499754560 TipperTarpaulinStatus 3000;
BA_REL_ "GenSigTimeoutTime" BU_SG_REL_ WRCS SG_ 2499754560 TipperTarpaulinStatus 300;
BA_REL_ "GenSigFirstTimeoutTime" BU_SG_REL_ WRCS SG_ 2499754560 TailLiftConditionsStatus 3000;
BA_REL_ "GenSigTimeoutTime" BU_SG_REL_ WRCS SG_ 2499754560 TailLiftConditionsStatus 300;
BA_REL_ "GenSigFirstTimeoutTime" BU_SG_REL_ WRCS SG_ 2499754560 InhibitWRCECSMenuCmd 3000;
BA_REL_ "GenSigTimeoutTime" BU_SG_REL_ WRCS SG_ 2499754560 InhibitWRCECSMenuCmd 300;
BA_REL_ "GenSigFirstTimeoutTime" BU_SG_REL_ CCM SG_ 2499754560 ShortStopHeater_status 3000;
BA_REL_ "GenSigTimeoutTime" BU_SG_REL_ CCM SG_ 2499754560 ShortStopHeater_status 300;
BA_REL_ "GenSigFirstTimeoutTime" BU_SG_REL_ SRS SG_ 2499754560 LongMotionDirectionQual 3000;
BA_REL_ "GenSigTimeoutTime" BU_SG_REL_ SRS SG_ 2499754560 LongMotionDirectionQual 300;
BA_REL_ "GenSigFirstTimeoutTime" BU_SG_REL_ WRCS SG_ 2499754560 TipperShakerStatus 3000;
BA_REL_ "GenSigTimeoutTime" BU_SG_REL_ WRCS SG_ 2499754560 TipperShakerStatus 300;
BA_REL_ "GenSigFirstTimeoutTime" BU_SG_REL_ WRCS SG_ 2499754560 TailLiftMotionStatus 3000;
BA_REL_ "GenSigTimeoutTime" BU_SG_REL_ WRCS SG_ 2499754560 TailLiftMotionStatus 300;
BA_REL_ "GenSigFirstTimeoutTime" BU_SG_REL_ CCM SG_ 2499679296 CoolantPumpEngagementStatus 3000;
BA_REL_ "GenSigTimeoutTime" BU_SG_REL_ CCM SG_ 2499679296 CoolantPumpEngagementStatus 300;
BA_REL_ "GenSigFirstTimeoutTime" BU_SG_REL_ CCM SG_ 2499679296 PHTimerRqstAck_Hours 3000;
BA_REL_ "GenSigTimeoutTime" BU_SG_REL_ CCM SG_ 2499679296 PHTimerRqstAck_Hours 300;
BA_REL_ "GenSigFirstTimeoutTime" BU_SG_REL_ WRCS SG_ 2499679296 LoadDistributionSelected 3000;
BA_REL_ "GenSigTimeoutTime" BU_SG_REL_ WRCS SG_ 2499679296 LoadDistributionSelected 300;
BA_REL_ "GenSigFirstTimeoutTime" BU_SG_REL_ CCM SG_ 2499679296 PHTimerRqstAck_DayOfWeekRq 3000;
BA_REL_ "GenSigTimeoutTime" BU_SG_REL_ CCM SG_ 2499679296 PHTimerRqstAck_DayOfWeekRq 300;
BA_REL_ "GenSigFirstTimeoutTime" BU_SG_REL_ CCM SG_ 2499679296 PHTimerRqstAck_Minutes 3000;
BA_REL_ "GenSigTimeoutTime" BU_SG_REL_ CCM SG_ 2499679296 PHTimerRqstAck_Minutes 300;
BA_REL_ "GenSigFirstTimeoutTime" BU_SG_REL_ WRCS SG_ 2499679296 LiftAxle1PositionStatus 3000;
BA_REL_ "GenSigTimeoutTime" BU_SG_REL_ WRCS SG_ 2499679296 LiftAxle1PositionStatus 300;
BA_REL_ "GenSigFirstTimeoutTime" BU_SG_REL_ CCM SG_ 2499679296 PHTimerRqstAck_CurrentOp 3000;
BA_REL_ "GenSigTimeoutTime" BU_SG_REL_ CCM SG_ 2499679296 PHTimerRqstAck_CurrentOp 300;
BA_REL_ "GenSigFirstTimeoutTime" BU_SG_REL_ WRCS SG_ 2499679296 LiftAxle2PositionStatus 3000;
BA_REL_ "GenSigTimeoutTime" BU_SG_REL_ WRCS SG_ 2499679296 LiftAxle2PositionStatus 300;
BA_REL_ "GenSigFirstTimeoutTime" BU_SG_REL_ CCM SG_ 2499679296 EngineCoolingFanSpeed 3000;
BA_REL_ "GenSigTimeoutTime" BU_SG_REL_ CCM SG_ 2499679296 EngineCoolingFanSpeed 300;
BA_REL_ "GenSigFirstTimeoutTime" BU_SG_REL_ WRCS SG_ 2499679296 ParkingBrake_stat 3000;
BA_REL_ "GenSigTimeoutTime" BU_SG_REL_ WRCS SG_ 2499679296 ParkingBrake_stat 300;
BA_REL_ "GenSigFirstTimeoutTime" BU_SG_REL_ LECM3 SG_ 2499679296 AudioMuteStat 3000;
BA_REL_ "GenSigTimeoutTime" BU_SG_REL_ LECM3 SG_ 2499679296 AudioMuteStat 300;
BA_REL_ "GenSigFirstTimeoutTime" BU_SG_REL_ LECM1 SG_ 2499679296 AudioMuteStat 3000;
BA_REL_ "GenSigTimeoutTime" BU_SG_REL_ LECM1 SG_ 2499679296 AudioMuteStat 300;
BA_REL_ "GenSigFirstTimeoutTime" BU_SG_REL_ LECM1 SG_ 2549186373 AudioSourceBtStreamAvailable 3600;
BA_REL_ "GenSigTimeoutTime" BU_SG_REL_ LECM1 SG_ 2549186373 AudioSourceBtStreamAvailable 900;
BA_REL_ "GenSigFirstTimeoutTime" BU_SG_REL_ LECM3 SG_ 2549186373 PS_EntChannelNumber 4800;
BA_REL_ "GenSigTimeoutTime" BU_SG_REL_ LECM3 SG_ 2549186373 PS_EntChannelNumber 900;
BA_REL_ "GenSigFirstTimeoutTime" BU_SG_REL_ LECM1 SG_ 2549186373 AudioSourceStatus2 3600;
BA_REL_ "GenSigTimeoutTime" BU_SG_REL_ LECM1 SG_ 2549186373 AudioSourceStatus2 900;
BA_REL_ "GenSigFirstTimeoutTime" BU_SG_REL_ LECM1 SG_ 2549186373 AudioSourceUsbAvailable 3600;
BA_REL_ "GenSigTimeoutTime" BU_SG_REL_ LECM1 SG_ 2549186373 AudioSourceUsbAvailable 900;
BA_REL_ "GenSigFirstTimeoutTime" BU_SG_REL_ LECM1 SG_ 2549186373 AudioSourceCdAvailable 3600;
BA_REL_ "GenSigTimeoutTime" BU_SG_REL_ LECM1 SG_ 2549186373 AudioSourceCdAvailable 900;
BA_REL_ "GenSigFirstTimeoutTime" BU_SG_REL_ LECM1 SG_ 2549186373 AudioSourceIpodAvailable 3600;
BA_REL_ "GenSigTimeoutTime" BU_SG_REL_ LECM1 SG_ 2549186373 AudioSourceIpodAvailable 900;
BA_REL_ "GenSigFirstTimeoutTime" BU_SG_REL_ LECM1 SG_ 2565904383 AlarmClkAl_LECM_stat_SetHr 3600;
BA_REL_ "GenSigTimeoutTime" BU_SG_REL_ LECM1 SG_ 2565904383 AlarmClkAl_LECM_stat_SetHr 900;
BA_REL_ "GenSigFirstTimeoutTime" BU_SG_REL_ WRCS SG_ 2565904383 ESCReqESC_CtrlTrimValue 3600;
BA_REL_ "GenSigTimeoutTime" BU_SG_REL_ WRCS SG_ 2565904383 ESCReqESC_CtrlTrimValue 900;
BA_REL_ "GenSigFirstTimeoutTime" BU_SG_REL_ LECM1 SG_ 2565904383 AlarmClockNotification_Stat 3600;
BA_REL_ "GenSigTimeoutTime" BU_SG_REL_ LECM1 SG_ 2565904383 AlarmClockNotification_Stat 900;
BA_REL_ "GenSigFirstTimeoutTime" BU_SG_REL_ LECM1 SG_ 2565904383 AlarmClkAl_LECM_stat_Type 3600;
BA_REL_ "GenSigTimeoutTime" BU_SG_REL_ LECM1 SG_ 2565904383 AlarmClkAl_LECM_stat_Type 900;
BA_REL_ "GenSigFirstTimeoutTime" BU_SG_REL_ LECM1 SG_ 2565904383 AlarmClkAl_LECM_stat_Stat 3600;
BA_REL_ "GenSigTimeoutTime" BU_SG_REL_ LECM1 SG_ 2565904383 AlarmClkAl_LECM_stat_Stat 900;
BA_REL_ "GenSigFirstTimeoutTime" BU_SG_REL_ LECM1 SG_ 2565904383 AlarmClockNotification_Type 3600;
BA_REL_ "GenSigTimeoutTime" BU_SG_REL_ LECM1 SG_ 2565904383 AlarmClockNotification_Type 900;
BA_REL_ "GenSigFirstTimeoutTime" BU_SG_REL_ LECM1 SG_ 2565904383 AlarmClkAl_LECM_stat_DaySet 3600;
BA_REL_ "GenSigTimeoutTime" BU_SG_REL_ LECM1 SG_ 2565904383 AlarmClkAl_LECM_stat_DaySet 900;
BA_REL_ "GenSigFirstTimeoutTime" BU_SG_REL_ WRCS SG_ 2565904383 ESCReqESC_CtrlTrimReq 3600;
BA_REL_ "GenSigTimeoutTime" BU_SG_REL_ WRCS SG_ 2565904383 ESCReqESC_CtrlTrimReq 900;
BA_REL_ "GenSigFirstTimeoutTime" BU_SG_REL_ LECM1 SG_ 2565904383 AlarmClkAl_LECM_stat_ID 3600;
BA_REL_ "GenSigTimeoutTime" BU_SG_REL_ LECM1 SG_ 2565904383 AlarmClkAl_LECM_stat_ID 900;
BA_REL_ "GenSigFirstTimeoutTime" BU_SG_REL_ WRCS SG_ 2565904383 ESCReqESC_CtrlTrimMode 3600;
BA_REL_ "GenSigTimeoutTime" BU_SG_REL_ WRCS SG_ 2565904383 ESCReqESC_CtrlTrimMode 900;
BA_REL_ "GenSigFirstTimeoutTime" BU_SG_REL_ LECM1 SG_ 2565904383 AlarmClkAl_LECM_stat_SetMin 3600;
BA_REL_ "GenSigTimeoutTime" BU_SG_REL_ LECM1 SG_ 2565904383 AlarmClkAl_LECM_stat_SetMin 900;
BA_REL_ "GenSigFirstTimeoutTime" BU_SG_REL_ WRCS SG_ 2565904383 ESCReqESC_CtrlTrimStat 3600;
BA_REL_ "GenSigTimeoutTime" BU_SG_REL_ WRCS SG_ 2565904383 ESCReqESC_CtrlTrimStat 900;
BA_REL_ "GenSigFirstTimeoutTime" BU_SG_REL_ LECM1 SG_ 2565904383 AlarmClkAl_LECM_stat_Mode 3600;
BA_REL_ "GenSigTimeoutTime" BU_SG_REL_ LECM1 SG_ 2565904383 AlarmClkAl_LECM_stat_Mode 900;
BA_REL_ "GenSigFirstTimeoutTime" BU_SG_REL_ LECM1 SG_ 2565904383 AlarmClockNotification_ID 3600;
BA_REL_ "GenSigTimeoutTime" BU_SG_REL_ LECM1 SG_ 2565904383 AlarmClockNotification_ID 900;
BA_REL_ "GenSigFirstTimeoutTime" BU_SG_REL_ WRCS SG_ 2499755967 FdEquipmentStatus2 3000;
BA_REL_ "GenSigTimeoutTime" BU_SG_REL_ WRCS SG_ 2499755967 FdEquipmentStatus2 300;
BA_REL_ "GenSigFirstTimeoutTime" BU_SG_REL_ WRCS SG_ 2499755967 RideHeightStatus 3000;
BA_REL_ "GenSigTimeoutTime" BU_SG_REL_ WRCS SG_ 2499755967 RideHeightStatus 300;
BA_REL_ "GenSigFirstTimeoutTime" BU_SG_REL_ WRCS SG_ 2499755967 FdEquipmentStatus4 3000;
BA_REL_ "GenSigTimeoutTime" BU_SG_REL_ WRCS SG_ 2499755967 FdEquipmentStatus4 300;
BA_REL_ "GenSigFirstTimeoutTime" BU_SG_REL_ WRCS SG_ 2499755967 RideHeightOutsideTargetRange 3000;
BA_REL_ "GenSigTimeoutTime" BU_SG_REL_ WRCS SG_ 2499755967 RideHeightOutsideTargetRange 300;
BA_REL_ "GenSigFirstTimeoutTime" BU_SG_REL_ WRCS SG_ 2499755967 FdEquipmentStatus1 3000;
BA_REL_ "GenSigTimeoutTime" BU_SG_REL_ WRCS SG_ 2499755967 FdEquipmentStatus1 300;
BA_REL_ "GenSigFirstTimeoutTime" BU_SG_REL_ WRCS SG_ 2499755967 FdEquipmentStatus5 3000;
BA_REL_ "GenSigTimeoutTime" BU_SG_REL_ WRCS SG_ 2499755967 FdEquipmentStatus5 300;
BA_REL_ "GenSigFirstTimeoutTime" BU_SG_REL_ WRCS SG_ 2499755967 RideHeightFunctionStatus 3000;
BA_REL_ "GenSigTimeoutTime" BU_SG_REL_ WRCS SG_ 2499755967 RideHeightFunctionStatus 300;
BA_REL_ "GenSigFirstTimeoutTime" BU_SG_REL_ WRCS SG_ 2499755967 FdEquipmentStatus3 3000;
BA_REL_ "GenSigTimeoutTime" BU_SG_REL_ WRCS SG_ 2499755967 FdEquipmentStatus3 300;
BA_REL_ "GenSigFirstTimeoutTime" BU_SG_REL_ WRCS SG_ 2499755967 FdEquipmentValue2 3000;
BA_REL_ "GenSigTimeoutTime" BU_SG_REL_ WRCS SG_ 2499755967 FdEquipmentValue2 300;
BA_REL_ "GenSigFirstTimeoutTime" BU_SG_REL_ WRCS SG_ 2499755967 FrontEndPositionStatus 3000;
BA_REL_ "GenSigTimeoutTime" BU_SG_REL_ WRCS SG_ 2499755967 FrontEndPositionStatus 300;
BA_REL_ "GenSigFirstTimeoutTime" BU_SG_REL_ WRCS SG_ 2499755967 RollEndPositionStatus 3000;
BA_REL_ "GenSigTimeoutTime" BU_SG_REL_ WRCS SG_ 2499755967 RollEndPositionStatus 300;
BA_REL_ "GenSigFirstTimeoutTime" BU_SG_REL_ WRCS SG_ 2499755967 RampLevelStatus 3000;
BA_REL_ "GenSigTimeoutTime" BU_SG_REL_ WRCS SG_ 2499755967 RampLevelStatus 300;
BA_REL_ "GenSigFirstTimeoutTime" BU_SG_REL_ WRCS SG_ 2499755967 FdEquipmentValue1 3000;
BA_REL_ "GenSigTimeoutTime" BU_SG_REL_ WRCS SG_ 2499755967 FdEquipmentValue1 300;
BA_REL_ "GenSigFirstTimeoutTime" BU_SG_REL_ WRCS SG_ 2499755967 RampHeightOutsideTargetRange 3000;
BA_REL_ "GenSigTimeoutTime" BU_SG_REL_ WRCS SG_ 2499755967 RampHeightOutsideTargetRange 300;
BA_REL_ "GenSigFirstTimeoutTime" BU_SG_REL_ WRCS SG_ 2499755967 FdEquipmentValue3 3000;
BA_REL_ "GenSigTimeoutTime" BU_SG_REL_ WRCS SG_ 2499755967 FdEquipmentValue3 300;
BA_REL_ "GenSigFirstTimeoutTime" BU_SG_REL_ WRCS SG_ 2499755967 RearEndPositionStatus 3000;
BA_REL_ "GenSigTimeoutTime" BU_SG_REL_ WRCS SG_ 2499755967 RearEndPositionStatus 300;
BA_REL_ "GenSigFirstTimeoutTime" BU_SG_REL_ WRCS SG_ 2432687168 Pto1Status 3000;
BA_REL_ "GenSigTimeoutTime" BU_SG_REL_ WRCS SG_ 2432687168 Pto1Status 120;
BA_REL_ "GenSigFirstTimeoutTime" BU_SG_REL_ WRCS SG_ 2432687168 BodyOrCabWorkingLightFdbk_stat 3000;
BA_REL_ "GenSigTimeoutTime" BU_SG_REL_ WRCS SG_ 2432687168 BodyOrCabWorkingLightFdbk_stat 120;
BA_REL_ "GenSigFirstTimeoutTime" BU_SG_REL_ CCM SG_ 2432687168 ElectricalLoadReduction_rqst 3000;
BA_REL_ "GenSigTimeoutTime" BU_SG_REL_ CCM SG_ 2432687168 ElectricalLoadReduction_rqst 500;
BA_REL_ "GenSigFirstTimeoutTime" BU_SG_REL_ WRCS SG_ 2432687168 ElectricalLoadReduction_rqst 3000;
BA_REL_ "GenSigTimeoutTime" BU_SG_REL_ WRCS SG_ 2432687168 ElectricalLoadReduction_rqst 500;
BA_REL_ "GenSigFirstTimeoutTime" BU_SG_REL_ SRS SG_ 2432687168 AirbagTelltale_stat 3000;
BA_REL_ "GenSigTimeoutTime" BU_SG_REL_ SRS SG_ 2432687168 AirbagTelltale_stat 120;
BA_REL_ "GenSigFirstTimeoutTime" BU_SG_REL_ WRCS SG_ 2432687168 CabWrknLightChassisFdbk_stat 3000;
BA_REL_ "GenSigTimeoutTime" BU_SG_REL_ WRCS SG_ 2432687168 CabWrknLightChassisFdbk_stat 120;
BA_REL_ "GenSigFirstTimeoutTime" BU_SG_REL_ WRCS SG_ 2432687168 ExtraBBTailLiftStatus 3000;
BA_REL_ "GenSigTimeoutTime" BU_SG_REL_ WRCS SG_ 2432687168 ExtraBBTailLiftStatus 120;
BA_REL_ "GenSigFirstTimeoutTime" BU_SG_REL_ LECM3 SG_ 2432687168 TotalVehicleDistanceHighRes 3000;
BA_REL_ "GenSigTimeoutTime" BU_SG_REL_ LECM3 SG_ 2432687168 TotalVehicleDistanceHighRes 120;
BA_REL_ "GenSigFirstTimeoutTime" BU_SG_REL_ CMS SG_ 2432687168 TotalVehicleDistanceHighRes 3000;
BA_REL_ "GenSigTimeoutTime" BU_SG_REL_ CMS SG_ 2432687168 TotalVehicleDistanceHighRes 120;
BA_REL_ "GenSigFirstTimeoutTime" BU_SG_REL_ SRS SG_ 2432687168 TotalVehicleDistanceHighRes 3000;
BA_REL_ "GenSigTimeoutTime" BU_SG_REL_ SRS SG_ 2432687168 TotalVehicleDistanceHighRes 120;
BA_REL_ "GenSigFirstTimeoutTime" BU_SG_REL_ LECM1 SG_ 2432687168 TotalVehicleDistanceHighRes 3000;
BA_REL_ "GenSigTimeoutTime" BU_SG_REL_ LECM1 SG_ 2432687168 TotalVehicleDistanceHighRes 120;
BA_REL_ "GenSigFirstTimeoutTime" BU_SG_REL_ WRCS SG_ 2432687168 TotalVehicleDistanceHighRes 3000;
BA_REL_ "GenSigTimeoutTime" BU_SG_REL_ WRCS SG_ 2432687168 TotalVehicleDistanceHighRes 120;
BA_REL_ "GenSigFirstTimeoutTime" BU_SG_REL_ CCM SG_ 2432687168 TotalVehicleDistanceHighRes 3000;
BA_REL_ "GenSigTimeoutTime" BU_SG_REL_ CCM SG_ 2432687168 TotalVehicleDistanceHighRes 120;
BA_REL_ "GenSigFirstTimeoutTime" BU_SG_REL_ WRCS SG_ 2432687168 ExtraBBCraneStatus 3000;
BA_REL_ "GenSigTimeoutTime" BU_SG_REL_ WRCS SG_ 2432687168 ExtraBBCraneStatus 120;
BA_REL_ "GenSigFirstTimeoutTime" BU_SG_REL_ WRCS SG_ 2432687168 Pto3Status 3000;
BA_REL_ "GenSigTimeoutTime" BU_SG_REL_ WRCS SG_ 2432687168 Pto3Status 120;
BA_REL_ "GenSigFirstTimeoutTime" BU_SG_REL_ CCM SG_ 2432687168 AirBleedValveStat 3000;
BA_REL_ "GenSigTimeoutTime" BU_SG_REL_ CCM SG_ 2432687168 AirBleedValveStat 120;
BA_REL_ "GenSigFirstTimeoutTime" BU_SG_REL_ WRCS SG_ 2432687168 CabExtraSideWrknLightFdbk_stat 3000;
BA_REL_ "GenSigTimeoutTime" BU_SG_REL_ WRCS SG_ 2432687168 CabExtraSideWrknLightFdbk_stat 120;
BA_REL_ "GenSigFirstTimeoutTime" BU_SG_REL_ WRCS SG_ 2432687168 Pto2Status 3000;
BA_REL_ "GenSigTimeoutTime" BU_SG_REL_ WRCS SG_ 2432687168 Pto2Status 120;
BA_REL_ "GenSigFirstTimeoutTime" BU_SG_REL_ WRCS SG_ 2432687168 CabBeaconLightFeedback_Status 3000;
BA_REL_ "GenSigTimeoutTime" BU_SG_REL_ WRCS SG_ 2432687168 CabBeaconLightFeedback_Status 120;
BA_REL_ "GenSigFirstTimeoutTime" BU_SG_REL_ LECM1 SG_ 2432687168 AudioSourceStatus 3000;
BA_REL_ "GenSigTimeoutTime" BU_SG_REL_ LECM1 SG_ 2432687168 AudioSourceStatus 120;
BA_REL_ "GenSigFirstTimeoutTime" BU_SG_REL_ WRCS SG_ 2432687168 Pto4Status 3000;
BA_REL_ "GenSigTimeoutTime" BU_SG_REL_ WRCS SG_ 2432687168 Pto4Status 120;
BA_REL_ "GenSigFirstTimeoutTime" BU_SG_REL_ CCM SG_ 2550121792 DayLocal 6000;
BA_REL_ "GenSigTimeoutTime" BU_SG_REL_ CCM SG_ 2550121792 DayLocal 1500;
BA_REL_ "GenSigFirstTimeoutTime" BU_SG_REL_ CCM SG_ 2550121792 SecondsLocal 6000;
BA_REL_ "GenSigTimeoutTime" BU_SG_REL_ CCM SG_ 2550121792 SecondsLocal 1500;
BA_REL_ "GenSigFirstTimeoutTime" BU_SG_REL_ CCM SG_ 2550121792 YearLocal 6000;
BA_REL_ "GenSigTimeoutTime" BU_SG_REL_ CCM SG_ 2550121792 YearLocal 1500;
BA_REL_ "GenSigFirstTimeoutTime" BU_SG_REL_ CCM SG_ 2550121792 ParkingHeaterCleaning_cmd 6000;
BA_REL_ "GenSigTimeoutTime" BU_SG_REL_ CCM SG_ 2550121792 ParkingHeaterCleaning_cmd 1500;
BA_REL_ "GenSigFirstTimeoutTime" BU_SG_REL_ CCM SG_ 2550121792 LivBatteryCharging_stat 6000;
BA_REL_ "GenSigTimeoutTime" BU_SG_REL_ CCM SG_ 2550121792 LivBatteryCharging_stat 1500;
BA_REL_ "GenSigFirstTimeoutTime" BU_SG_REL_ CCM SG_ 2550121792 MinutesLocal 6000;
BA_REL_ "GenSigTimeoutTime" BU_SG_REL_ CCM SG_ 2550121792 MinutesLocal 1500;
BA_REL_ "GenSigFirstTimeoutTime" BU_SG_REL_ LECM1 SG_ 2550121792 MinutesLocal 6000;
BA_REL_ "GenSigTimeoutTime" BU_SG_REL_ LECM1 SG_ 2550121792 MinutesLocal 1500;
BA_REL_ "GenSigFirstTimeoutTime" BU_SG_REL_ CCM SG_ 2550121792 BatterySOCAlertRawData_rqst 6000;
BA_REL_ "GenSigTimeoutTime" BU_SG_REL_ CCM SG_ 2550121792 BatterySOCAlertRawData_rqst 1500;
BA_REL_ "GenSigFirstTimeoutTime" BU_SG_REL_ CCM SG_ 2550121792 HoursLocal 6000;
BA_REL_ "GenSigTimeoutTime" BU_SG_REL_ CCM SG_ 2550121792 HoursLocal 1500;
BA_REL_ "GenSigFirstTimeoutTime" BU_SG_REL_ LECM1 SG_ 2550121792 HoursLocal 6000;
BA_REL_ "GenSigTimeoutTime" BU_SG_REL_ LECM1 SG_ 2550121792 HoursLocal 1500;
BA_REL_ "GenSigFirstTimeoutTime" BU_SG_REL_ CCM SG_ 2550121792 MonthLocal 6000;
BA_REL_ "GenSigTimeoutTime" BU_SG_REL_ CCM SG_ 2550121792 MonthLocal 1500;
VAL_ 2432685120 UpdParkClimTimerRqst_TimerCmd 7 "PhTimer_cmd_NotAvailable" 6 "PhTimer_cmd_Error" 5 "PhTimer_cmd_Spare_02" 4 "PhTimer_cmd_Spare_01" 3 "PhTimer_cmd_TimerDeleted" 2 "PhTimer_cmd_TimerDisable" 1 "PhTimer_cmd_TimerEnable" 0 "PhTimer_cmd_NoAction" ;
VAL_ 2432663360 SetParkClimTimerRqst_Sun 1 "NotSelectedSelected_Selected" 0 "NotSelectedSelected_NotSelected" ;
VAL_ 2432663360 SetParkClimTimerRqst_Tue 1 "NotSelectedSelected_Selected" 0 "NotSelectedSelected_NotSelected" ;
VAL_ 2432663360 SetParkClimTimerRqst_TimerCmd 7 "PhTimer_cmd_NotAvailable" 6 "PhTimer_cmd_Error" 5 "PhTimer_cmd_Spare_02" 4 "PhTimer_cmd_Spare_01" 3 "PhTimer_cmd_TimerDeleted" 2 "PhTimer_cmd_TimerDisable" 1 "PhTimer_cmd_TimerEnable" 0 "PhTimer_cmd_NoAction" ;
VAL_ 2432663360 SetParkClimTimerRqst_Wed 1 "NotSelectedSelected_Selected" 0 "NotSelectedSelected_NotSelected" ;
VAL_ 2432663360 SetParkClimTimerRqst_Type 7 "TimerType_NotAvailable" 6 "TimerType_Error" 5 "TimerType_Spare3" 4 "TimerType_Spare2" 3 "TimerType_Spare1" 2 "TimerType_CabClimateTimerWithStartTime" 1 "TimerType_EngineTimerWithReadyTime" 0 "TimerType_CabClimateTimerWithReadyTime" ;
VAL_ 2432663360 SetParkClimTimerRqst_Mon 1 "NotSelectedSelected_Selected" 0 "NotSelectedSelected_NotSelected" ;
VAL_ 2432663360 SetParkClimTimerRqst_Fri 1 "NotSelectedSelected_Selected" 0 "NotSelectedSelected_NotSelected" ;
VAL_ 2432663360 SetParkClimTimerRqst_Sat 1 "NotSelectedSelected_Selected" 0 "NotSelectedSelected_NotSelected" ;
VAL_ 2432663360 SetParkClimTimerRqst_Rec 1 "Rec_Recurrent" 0 "Rec_Once" ;
VAL_ 2432663360 SetParkClimTimerRqst_Thu 1 "NotSelectedSelected_Selected" 0 "NotSelectedSelected_NotSelected" ;
VAL_ 2566357312 GPSData_AntennaStat 7 "GPS_Antenna_status_NA" 6 "GPS_Antenna_status_ErrorIndicator" 5 "GPS_Antenna_status_SpareValue_01" 4 "GPS_Antenna_status_SpareValue" 3 "GPS_Antenna_status_AntennaStatusUnknown" 2 "GPS_Antenna_status_AntennaInit" 1 "GPS_Antenna_status_AntennaDisconnected" 0 "GPS_Antenna_status_AntennaStatusOK" ;
VAL_ 2432647232 DirInd_StalkStatus_1 7 "DirInd_StalkStatus_NotAvailable" 6 "DirInd_StalkStatus_Error" 5 "DirInd_StalkStatus_Spare" 4 "DirInd_StalkStatus_RightTemporaryTurningIndication" 3 "DirInd_StalkStatus_LeftTemporaryTurningIndication" 2 "DirInd_StalkStatus_RightTurningIndication" 1 "DirInd_StalkStatus_LeftTurningIndication" 0 "DirInd_StalkStatus_NeutralRestingPositon" ;
VAL_ 2432647232 CMSPanning_rqst 3 "InactiveActive_NotAvailable" 2 "InactiveActive_Error" 1 "InactiveActive_Active" 0 "InactiveActive_Inactive" ;
VAL_ 2432647232 CM_Status 7 "CM_Status_NotAvailable" 6 "CM_Status_ErrorIndicator" 5 "CM_Status_CM_DisabledBySystem" 4 "CM_Status_CM_MitigationBrakingFinished" 3 "CM_Status_CM_MitigationBraking" 2 "CM_Status_CM_PreMitigationBraking" 1 "CM_Status_CM_Enabled" 0 "CM_Status_CM_Disabled" ;
VAL_ 2432647232 CameraAdj_rqst 7 "CameraAdj_NotAvailable" 6 "CameraAdj_Error" 5 "CameraAdj_Spare" 4 "CameraAdj_Right" 3 "CameraAdj_Left" 2 "CameraAdj_Down" 1 "CameraAdj_Up" 0 "CameraAdj_Off" ;
VAL_ 2432647232 CameraSelection_rqst 7 "CameraSelection_rqst_NotAvailable" 6 "CameraSelection_rqst_Error" 5 "CameraSelection_rqst_Spare3" 4 "CameraSelection_rqst_Spare2" 3 "CameraSelection_rqst_ResetBothSideClassII_FOV" 2 "CameraSelection_rqst_PassengerSideClassII_FOV" 1 "CameraSelection_rqst_DriverSideClassII_FOV" 0 "CameraSelection_rqst_No_FOV_Selected" ;
VAL_ 2432647232 LCS_WarningStatusRight 15 "LCS_WarningStatus2_NotAvailable" 14 "LCS_WarningStatus2_Error" 13 "LCS_WarningStatus2_Spare9" 12 "LCS_WarningStatus2_Spare8" 11 "LCS_WarningStatus2_Spare7" 10 "LCS_WarningStatus2_Spare6" 9 "LCS_WarningStatus2_Spare5" 8 "LCS_WarningStatus2_Spare4" 7 "LCS_WarningStatus2_Spare3" 6 "LCS_WarningStatus2_WarningLevel3" 5 "LCS_WarningStatus2_WarningLevel2" 4 "LCS_WarningStatus2_Warning" 3 "LCS_WarningStatus2_Information" 2 "LCS_WarningStatus2_EnabledAndActive" 1 "LCS_WarningStatus2_EnabledAndInactive" 0 "LCS_WarningStatus2_Off" ;
VAL_ 2432647232 GearLeverPosition 15 "GearLeverPosition_NotAvailable" 14 "GearLeverPosition_Error" 13 "GearLeverPosition_SpareValue_06" 12 "GearLeverPosition_SpareValue_05" 11 "GearLeverPosition_SpareValue_04" 10 "GearLeverPosition_SpareValue_03" 9 "GearLeverPosition_SpareValue_02" 8 "GearLeverPosition_SpareValue_01" 7 "GearLeverPosition_SpareValue" 6 "GearLeverPosition_SEG6" 5 "GearLeverPosition_LowGear" 4 "GearLeverPosition_Manual" 3 "GearLeverPosition_Automatic" 2 "GearLeverPosition_Neutral" 1 "GearLeverPosition_Reverse" 0 "GearLeverPosition_GearFoldedAway" ;
VAL_ 2432647232 PassengersSeatBelt 7 "PassengersSeatBelt_NotAvailable" 6 "PassengersSeatBelt_Error" 5 "PassengersSeatBelt_Spare3" 4 "PassengersSeatBelt_Spare2" 3 "PassengersSeatBelt_Spare1" 2 "PassengersSeatBelt_PassengersNotSeated" 1 "PassengersSeatBelt_PassengersFastened" 0 "PassengersSeatBelt_AtLeastOnePassengerSeatedNotFastened" ;
VAL_ 2432647232 LCS_WarningStatusLeft 15 "LCS_WarningStatus2_NotAvailable" 14 "LCS_WarningStatus2_Error" 13 "LCS_WarningStatus2_Spare9" 12 "LCS_WarningStatus2_Spare8" 11 "LCS_WarningStatus2_Spare7" 10 "LCS_WarningStatus2_Spare6" 9 "LCS_WarningStatus2_Spare5" 8 "LCS_WarningStatus2_Spare4" 7 "LCS_WarningStatus2_Spare3" 6 "LCS_WarningStatus2_WarningLevel3" 5 "LCS_WarningStatus2_WarningLevel2" 4 "LCS_WarningStatus2_Warning" 3 "LCS_WarningStatus2_Information" 2 "LCS_WarningStatus2_EnabledAndActive" 1 "LCS_WarningStatus2_EnabledAndInactive" 0 "LCS_WarningStatus2_Off" ;
VAL_ 2432647232 CMSClassVActDeact_rqst 7 "InactiveActive3bit2_NotAvailable" 6 "InactiveActive3bit2_Error" 5 "InactiveActive3bit2_Spare4" 4 "InactiveActive3bit2_Spare3" 3 "InactiveActive3bit2_Spare2" 2 "InactiveActive3bit2_Spare1" 1 "InactiveActive3bit2_Active" 0 "InactiveActive3bit2_Inactive" ;
VAL_ 2432647232 CMSBacklightCmd 31 "BacklightCmd_NotAvailable" 30 "BacklightCmd_Error" 16 "BacklightCmd_BacklightLevel16" 15 "BacklightCmd_BacklightLevel15" 14 "BacklightCmd_BacklightLevel14" 13 "BacklightCmd_BacklightLevel13" 12 "BacklightCmd_BacklightLevel12" 11 "BacklightCmd_BacklightLevel11" 10 "BacklightCmd_BacklightLevel10" 9 "BacklightCmd_BacklightLevel9" 8 "BacklightCmd_BacklightLevel8" 7 "BacklightCmd_BacklightLevel7" 6 "BacklightCmd_BacklightLevel6" 5 "BacklightCmd_BacklightLevel5" 4 "BacklightCmd_BacklightLevel4" 3 "BacklightCmd_BacklightLevel3" 2 "BacklightCmd_BacklightLevel2" 1 "BacklightCmd_BacklightLevel1" 0 "BacklightCmd_BacklightOff" ;
VAL_ 2516193600 ReqHVILmonitoring 3 "NotRequested_NotAvailable" 2 "NotRequested_Error" 1 "NotRequested_Requested" 0 "NotRequested_NotRequested" ;
VAL_ 2516193600 AuxTVSStatus 7 "DisablingEnabling_NotAvailable" 6 "DisablingEnabling_Error" 5 "DisablingEnabling_Spare2" 4 "DisablingEnabling_Spare1" 3 "DisablingEnabling_Disabling" 2 "DisablingEnabling_Enabled" 1 "DisablingEnabling_Enabling" 0 "DisablingEnabling_NotEnabled" ;
VAL_ 2516193600 Trailer2LiftAxle2Pos 3 "TrailerLiftAxlePos_NotAvailable" 2 "TrailerLiftAxlePos_Error" 1 "TrailerLiftAxlePos_AxleLifted" 0 "TrailerLiftAxlePos_AxleDown" ;
VAL_ 2516193600 Trailer3LiftAxle2Pos 3 "TrailerLiftAxlePos_NotAvailable" 2 "TrailerLiftAxlePos_Error" 1 "TrailerLiftAxlePos_AxleLifted" 0 "TrailerLiftAxlePos_AxleDown" ;
VAL_ 2516193600 ROPBrakeControlActive 3 "PassiveActive2_DontCareTakeNoAction" 2 "PassiveActive2_Reserved" 1 "PassiveActive2_Active" 0 "PassiveActive2_PassiveButInstalled" ;
VAL_ 2516193600 TransmissionDrivingMode 7 "TransmissionDrivingMode_NotAvailable" 6 "TransmissionDrivingMode_KickDown" 5 "TransmissionDrivingMode_Dynamometer" 4 "TransmissionDrivingMode_HeavyDuty" 3 "TransmissionDrivingMode_OffRoad" 2 "TransmissionDrivingMode_Performance" 1 "TransmissionDrivingMode_Balanced_Standard" 0 "TransmissionDrivingMode_EconomyExtra_Range" ;
VAL_ 2516193600 Trailer5LiftAxle1Pos 3 "TrailerLiftAxlePos_NotAvailable" 2 "TrailerLiftAxlePos_Error" 1 "TrailerLiftAxlePos_AxleLifted" 0 "TrailerLiftAxlePos_AxleDown" ;
VAL_ 2516193600 Trailer1LiftAxle2Pos 3 "TrailerLiftAxlePos_NotAvailable" 2 "TrailerLiftAxlePos_Error" 1 "TrailerLiftAxlePos_AxleLifted" 0 "TrailerLiftAxlePos_AxleDown" ;
VAL_ 2516193600 TVSDischargeRequest 3 "NotRequested_NotAvailable" 2 "NotRequested_Error" 1 "NotRequested_Requested" 0 "NotRequested_NotRequested" ;
VAL_ 2516193600 FoundationBrakeUse 3 "FoundationBrakeUse_NotAvailable" 2 "FoundationBrakeUse_Reserved" 1 "FoundationBrakeUse_FoundationBrakesInUse" 0 "FoundationBrakeUse_FoundationBrakesNotInUse" ;
VAL_ 2516193600 Trailer4LiftAxle1Pos 3 "TrailerLiftAxlePos_NotAvailable" 2 "TrailerLiftAxlePos_Error" 1 "TrailerLiftAxlePos_AxleLifted" 0 "TrailerLiftAxlePos_AxleDown" ;
VAL_ 2516193600 Trailer5LiftAxle2Pos 3 "TrailerLiftAxlePos_NotAvailable" 2 "TrailerLiftAxlePos_Error" 1 "TrailerLiftAxlePos_AxleLifted" 0 "TrailerLiftAxlePos_AxleDown" ;
VAL_ 2516193600 BlackPanel_stat 3 "InactiveActive_NotAvailable" 2 "InactiveActive_Error" 1 "InactiveActive_Active" 0 "InactiveActive_Inactive" ;
VAL_ 2516193600 Trailer4LiftAxle2Pos 3 "TrailerLiftAxlePos_NotAvailable" 2 "TrailerLiftAxlePos_Error" 1 "TrailerLiftAxlePos_AxleLifted" 0 "TrailerLiftAxlePos_AxleDown" ;
VAL_ 2516193600 AntiLockBrakingActive 3 "AntiLockBrakingActive_NotAvailable" 2 "AntiLockBrakingActive_Reserved" 1 "AntiLockBrakingActive_ABSActive" 0 "AntiLockBrakingActive_ABSPassiveButInstalled" ;
VAL_ 2516193600 YCBrakeControlActive 3 "PassiveActive2_DontCareTakeNoAction" 2 "PassiveActive2_Reserved" 1 "PassiveActive2_Active" 0 "PassiveActive2_PassiveButInstalled" ;
VAL_ 2516193600 EngineTmpryStopStartStatus 15 "EngineTmpryStopStartStatus_NotAvailable" 14 "EngineTmpryStopStartStatus_Error" 13 "EngineTmpryStopStartStatus_Spare9" 12 "EngineTmpryStopStartStatus_Spare8" 11 "EngineTmpryStopStartStatus_Spare7" 10 "EngineTmpryStopStartStatus_Spare6" 9 "EngineTmpryStopStartStatus_FunctionDeactivated" 8 "EngineTmpryStopStartStatus_StopFailed" 7 "EngineTmpryStopStartStatus_StopActivemanualRestartNeeded" 6 "EngineTmpryStopStartStatus_StopActiveRestartFailed" 5 "EngineTmpryStopStartStatus_StopActiveStartInhibited" 4 "EngineTmpryStopStartStatus_StopActiveStartRequested" 3 "EngineTmpryStopStartStatus_StopActive" 2 "EngineTmpryStopStartStatus_StopRequested" 1 "EngineTmpryStopStartStatus_Available" 0 "EngineTmpryStopStartStatus_Inhibited" ;
VAL_ 2516193600 Trailer1LiftAxle1Pos 3 "TrailerLiftAxlePos_NotAvailable" 2 "TrailerLiftAxlePos_Error" 1 "TrailerLiftAxlePos_AxleLifted" 0 "TrailerLiftAxlePos_AxleDown" ;
VAL_ 2516193600 Trailer3LiftAxle1Pos 3 "TrailerLiftAxlePos_NotAvailable" 2 "TrailerLiftAxlePos_Error" 1 "TrailerLiftAxlePos_AxleLifted" 0 "TrailerLiftAxlePos_AxleDown" ;
VAL_ 2516193600 Trailer2LiftAxle1Pos 3 "TrailerLiftAxlePos_NotAvailable" 2 "TrailerLiftAxlePos_Error" 1 "TrailerLiftAxlePos_AxleLifted" 0 "TrailerLiftAxlePos_AxleDown" ;
VAL_ 2432679744 MediaSourcesListRsp_SInfo 3 "SignalInfo2bitType_NotAvailable" 2 "SignalInfo2bitType_ErrorIndication" 1 "SignalInfo2bitType_Spare" 0 "SignalInfo2bitType_Valid" ;
VAL_ 2493989952 SEMMediaSourceAvail_Source07 1 "Bitfield1BitType_True" 0 "Bitfield1BitType_False" ;
VAL_ 2493989952 SEMMediaSourceAvail_Source06 1 "Bitfield1BitType_True" 0 "Bitfield1BitType_False" ;
VAL_ 2493989952 AutoBlowerLevelRqst 7 "AutoBlowerLevelRqst_NotAvailable" 6 "AutoBlowerLevelRqst_Error" 3 "AutoBlowerLevelRqst_Low" 2 "AutoBlowerLevelRqst_Normal" 1 "AutoBlowerLevelRqst_High" 0 "AutoBlowerLevelRqst_NoAction" ;
VAL_ 2493989952 SEMMediaSourceAvail_Source08 1 "Bitfield1BitType_True" 0 "Bitfield1BitType_False" ;
VAL_ 2493989952 SEMMediaSourceAvail_Source00 1 "Bitfield1BitType_True" 0 "Bitfield1BitType_False" ;
VAL_ 2493989952 SEM_AudioMuteStat 7 "AudioMute_NotAvailable" 6 "AudioMute_ErrorIndication" 5 "AudioMute_Spare_03" 4 "AudioMute_Spare_02" 3 "AudioMute_Spare_01" 2 "AudioMute_Spare" 1 "AudioMute_Mute" 0 "AudioMute_Off" ;
VAL_ 2493989952 SEMMediaSourceAvail_Source09 1 "Bitfield1BitType_True" 0 "Bitfield1BitType_False" ;
VAL_ 2493989952 SEMMediaSourceAvail_Source13 1 "Bitfield1BitType_True" 0 "Bitfield1BitType_False" ;
VAL_ 2493989952 SEMMediaSourceAvail_Source04 1 "Bitfield1BitType_True" 0 "Bitfield1BitType_False" ;
VAL_ 2493989952 SEMMediaSourceAvail_Source05 1 "Bitfield1BitType_True" 0 "Bitfield1BitType_False" ;
VAL_ 2493989952 SEMMediaSourceAvail_Source02 1 "Bitfield1BitType_True" 0 "Bitfield1BitType_False" ;
VAL_ 2493989952 SEMMediaSourceAvail_SInfo 3 "SignalInfo2bitType_NotAvailable" 2 "SignalInfo2bitType_ErrorIndication" 1 "SignalInfo2bitType_Spare" 0 "SignalInfo2bitType_Valid" ;
VAL_ 2493989952 AQSModeRqst 7 "AQSModeRqst_NotAvailable" 6 "AQSModeRqst_Error" 5 "AQSModeRqst_Spare3" 4 "AQSModeRqst_Spare2" 3 "AQSModeRqst_Spare1" 2 "AQSModeRqst_Auto" 1 "AQSModeRqst_Off" 0 "AQSModeRqst_NoAction" ;
VAL_ 2493989952 AudioSourceStat 15 "AudioSource_NotAvailable" 14 "AudioSource_Error" 13 "AudioSource_Source13" 12 "AudioSource_Source12" 11 "AudioSource_Source11" 10 "AudioSource_Source10" 9 "AudioSource_Source09" 8 "AudioSource_Source08" 7 "AudioSource_Source07" 6 "AudioSource_Source06" 5 "AudioSource_Source05" 4 "AudioSource_Source04" 3 "AudioSource_Source03" 2 "AudioSource_Source02" 1 "AudioSource_Source01" 0 "AudioSource_Source00" ;
VAL_ 2493989952 SEMMediaSourceAvail_Source11 1 "Bitfield1BitType_True" 0 "Bitfield1BitType_False" ;
VAL_ 2493989952 SEMMediaSourceAvail_Source10 1 "Bitfield1BitType_True" 0 "Bitfield1BitType_False" ;
VAL_ 2493989952 ACModeRqst 7 "ACModeReq_NotAvailable" 6 "ACModeReq_Error" 5 "ACModeReq_Spare" 4 "ACModeReq_ExtraDryCabAir" 3 "ACModeReq_HumidCabAir" 2 "ACModeReq_Standard" 1 "ACModeReq_Economy" 0 "ACModeReq_NoAction" ;
VAL_ 2493989952 ESS_TRDStatus 7 "ESS_TRDStatus_NotAvailable" 6 "ESS_TRDStatus_Error" 5 "ESS_TRDStatus_Spare3" 4 "ESS_TRDStatus_Spare2" 3 "ESS_TRDStatus_Spare1" 2 "ESS_TRDStatus_ThermalRunawayStatusNotAvailable" 1 "ESS_TRDStatus_OneOrMoreBPthermalRunaway" 0 "ESS_TRDStatus_NoThermalRunaway" ;
VAL_ 2493989952 AutoDefogModeRqst 7 "AutoDefogModeRqst_NotAvailable" 6 "AutoDefogModeRqst_Error" 5 "AutoDefogModeRqst_Spare" 4 "AutoDefogModeRqst_Moderate" 3 "AutoDefogModeRqst_Normal" 2 "AutoDefogModeRqst_Sensitive" 1 "AutoDefogModeRqst_Off" 0 "AutoDefogModeRqst_NoAction" ;
VAL_ 2493989952 SEMMediaSourceAvail_Source01 1 "Bitfield1BitType_True" 0 "Bitfield1BitType_False" ;
VAL_ 2493989952 EngineActiveStatus 15 "EngineActiveStatus_NotAvailable" 14 "EngineActiveStatus_Error" 13 "EngineActiveStatus_Spare_10" 12 "EngineActiveStatus_Spare_09" 11 "EngineActiveStatus_Spare_08" 10 "EngineActiveStatus_Spare_07" 9 "EngineActiveStatus_Spare_06" 8 "EngineActiveStatus_Spare_05" 7 "EngineActiveStatus_Spare_04" 6 "EngineActiveStatus_Spare_03" 5 "EngineActiveStatus_Spare_02" 4 "EngineActiveStatus_Spare_01" 3 "EngineActiveStatus_EngineStandby" 2 "EngineActiveStatus_ElectricPropulsionSystemRunning" 1 "EngineActiveStatus_InternalCombustionEngineRunning" 0 "EngineActiveStatus_DrivelineNotActive" ;
VAL_ 2493989952 SEMMediaSourceAvail_Source03 1 "Bitfield1BitType_True" 0 "Bitfield1BitType_False" ;
VAL_ 2493989952 SEMMediaSourceAvail_Source12 1 "Bitfield1BitType_True" 0 "Bitfield1BitType_False" ;
VAL_ 2499754560 InhibitTVSReq 7 "InhibitTVSReq_NotAvailable" 6 "InhibitTVSReq_Error" 5 "InhibitTVSReq_Spare3" 4 "InhibitTVSReq_Spare2" 3 "InhibitTVSReq_Spare1" 2 "InhibitTVSReq_Demanded" 1 "InhibitTVSReq_Requested" 0 "InhibitTVSReq_NotRequested" ;
VAL_ 2499754560 TipperEmergencyStopStatus 7 "TipperEmergencyStopStatus_NotAvailable" 6 "TipperEmergencyStopStatus_Error" 5 "TipperEmergencyStopStatus_Spare2" 4 "TipperEmergencyStopStatus_Spare1" 3 "TipperEmergencyStopStatus_RemoteAndChassis" 2 "TipperEmergencyStopStatus_ChassisOnly" 1 "TipperEmergencyStopStatus_RemoteOnly" 0 "TipperEmergencyStopStatus_None" ;
VAL_ 2499754560 TipperPrimaryBodyStatus 7 "TipperBodyStatus_NotAvailable" 6 "TipperBodyStatus_Error" 5 "TipperBodyStatus_Spare3" 4 "TipperBodyStatus_Spare2" 3 "TipperBodyStatus_Spare1" 2 "TipperBodyStatus_NotPresent" 1 "TipperBodyStatus_Unavailable" 0 "TipperBodyStatus_Available" ;
VAL_ 2499754560 TipperConditionsStatus 3 "NotFulfilledFulfilled_NotAvailable" 2 "NotFulfilledFulfilled_Error" 1 "NotFulfilledFulfilled_Fulfilled" 0 "NotFulfilledFulfilled_NotFulfilled" ;
VAL_ 2499754560 TipperSecondaryBodyStatus 7 "TipperBodyStatus_NotAvailable" 6 "TipperBodyStatus_Error" 5 "TipperBodyStatus_Spare3" 4 "TipperBodyStatus_Spare2" 3 "TipperBodyStatus_Spare1" 2 "TipperBodyStatus_NotPresent" 1 "TipperBodyStatus_Unavailable" 0 "TipperBodyStatus_Available" ;
VAL_ 2499754560 BatterySOCAlert_rqst 7 "BatterySOCAlert_rqst_NotAvailable" 6 "BatterySOCAlert_rqst_ErrorIndicator" 5 "BatterySOCAlert_rqst_SpareValue_02" 4 "BatterySOCAlert_rqst_SpareValue_01" 3 "BatterySOCAlert_rqst_SpareValue" 2 "BatterySOCAlert_rqst_CriticalAlert" 1 "BatterySOCAlert_rqst_PreAlert" 0 "BatterySOCAlert_rqst_NoAlertRequested" ;
VAL_ 2499754560 CCStates 15 "CCStates_NotAvailable" 14 "CCStates_Error" 13 "CCStates_Spare_7" 12 "CCStates_Spare_6" 11 "CCStates_Spare_5" 10 "CCStates_Spare_4" 9 "CCStates_Spare_3" 8 "CCStates_Spare_2" 7 "CCStates_Spare_1" 6 "CCStates_Driver_Override" 5 "CCStates_Set" 4 "CCStates_Resume" 3 "CCStates_Decelerate" 2 "CCStates_Accelerate" 1 "CCStates_Hold" 0 "CCStates_OffDisabled" ;
VAL_ 2499754560 ExtraHeating_rqst 7 "ActivationRequest_NotAvailable" 6 "ActivationRequest_Error" 5 "ActivationRequest_Spare3" 4 "ActivationRequest_Spare2" 3 "ActivationRequest_Spare1" 2 "ActivationRequest_AutoStart" 1 "ActivationRequest_Off" 0 "ActivationRequest_NoAction" ;
VAL_ 2499754560 LongMotionDirection 7 "LongMotionDirection_NotAvailable" 6 "LongMotionDirection_Error" 5 "LongMotionDirection_Spare3" 4 "LongMotionDirection_Spare2" 3 "LongMotionDirection_Undetermined" 2 "LongMotionDirection_Backward" 1 "LongMotionDirection_Forward" 0 "LongMotionDirection_Stationary" ;
VAL_ 2499754560 TipperUpDownStatus 7 "UpDownStatus_NotAvailable" 6 "UpDownStatus_Error" 5 "UpDownStatus_Spare2" 4 "UpDownStatus_Spare1" 3 "UpDownStatus_AutoLowering" 2 "UpDownStatus_Lowering" 1 "UpDownStatus_Raising" 0 "UpDownStatus_Inactive" ;
VAL_ 2499754560 TipperTailGateStatus 7 "GateStatus_NotAvailable" 6 "GateStatus_Error" 5 "GateStatus_Spare3" 4 "GateStatus_Spare2" 3 "GateStatus_Spare1" 2 "GateStatus_Closing" 1 "GateStatus_Opening" 0 "GateStatus_Inactive" ;
VAL_ 2499754560 KneelingInformation 15 "KneelingInformation_NotAvailable" 14 "KneelingInformation_ErrorIndicator" 13 "KneelingInformation_NotDefined_08" 12 "KneelingInformation_NotDefined_07" 11 "KneelingInformation_NotDefined_06" 10 "KneelingInformation_NotDefined_05" 9 "KneelingInformation_NotDefined_04" 8 "KneelingInformation_NotDefined_03" 7 "KneelingInformation_NotDefined_02" 6 "KneelingInformation_NotDefined_01" 5 "KneelingInformation_NotDefined" 4 "KneelingInformation_KneelingAborted" 3 "KneelingInformation_LiftingActiveVehicleIsLiftedDueToRcvrReq" 2 "KneelingInformation_KneelLevelReachedVehicleIsAtFixeKneelLvl" 1 "KneelingInformation_LoweringActiveTheVehIsLoweredDueToKneelReq" 0 "KneelingInformation_NotActiveTheKneelingFunctionIsNotActive" ;
VAL_ 2499754560 TailLiftRemoteNotAllowed 3 "NotAllowedAllowed_NotAvailable" 2 "NotAllowedAllowed_Error" 1 "NotAllowedAllowed_Allowed" 0 "NotAllowedAllowed_NotAllowed" ;
VAL_ 2499754560 DirectionIndicatorActive_stat 7 "DirectionIndicatorActive_NotAvailable" 6 "DirectionIndicatorActive_Error" 5 "DirectionIndicatorActive_ActiveLeftAndRight" 4 "DirectionIndicatorActive_ActiveRightContinuous" 3 "DirectionIndicatorActive_ActiveRightTemporary" 2 "DirectionIndicatorActive_ActiveLeftContinuous" 1 "DirectionIndicatorActive_ActiveLeftTemporary" 0 "DirectionIndicatorActive_NotActive" ;
VAL_ 2499754560 TipperTarpaulinStatus 7 "TarpaulinStatus_NotAvailable" 6 "TarpaulinStatus_Error" 5 "TarpaulinStatus_Spare3" 4 "TarpaulinStatus_Spare2" 3 "TarpaulinStatus_Spare1" 2 "TarpaulinStatus_Uncovering" 1 "TarpaulinStatus_Covering" 0 "TarpaulinStatus_Inactive" ;
VAL_ 2499754560 TailLiftConditionsStatus 3 "NotFulfilledFulfilled_NotAvailable" 2 "NotFulfilledFulfilled_Error" 1 "NotFulfilledFulfilled_Fulfilled" 0 "NotFulfilledFulfilled_NotFulfilled" ;
VAL_ 2499754560 InhibitWRCECSMenuCmd 3 "InactiveActive_NotAvailable" 2 "InactiveActive_Error" 1 "InactiveActive_Active" 0 "InactiveActive_Inactive" ;
VAL_ 2499754560 ShortStopHeater_status 7 "ShortStopHeaterStatus_NotAvailable" 6 "ShortStopHeaterStatus_Error" 5 "ShortStopHeaterStatus_Spare3" 4 "ShortStopHeaterStatus_Spare2" 3 "ShortStopHeaterStatus_Spare1" 2 "ShortStopHeaterStatus_ActivatedAndPumpNotEngaged" 1 "ShortStopHeaterStatus_ActivatedAndPumpEngaged" 0 "ShortStopHeaterStatus_NotActivated" ;
VAL_ 2499754560 LongMotionDirectionQual 3 "LongMotionDirectionQual_NotAvailable" 2 "LongMotionDirectionQual_OEM_Reserved2" 1 "LongMotionDirectionQual_OEM_Reserved1" 0 "LongMotionDirectionQual_UsingGearbox" ;
VAL_ 2499754560 TipperShakerStatus 3 "ShakerStatus_NotAvailable" 2 "ShakerStatus_Error" 1 "ShakerStatus_Shaking" 0 "ShakerStatus_Inactive" ;
VAL_ 2499754560 TailLiftMotionStatus 7 "RqstTiltUpDown_NotAvailable" 6 "RqstTiltUpDown_Error" 5 "RqstTiltUpDown_Spare" 4 "RqstTiltUpDown_TiltDown" 3 "RqstTiltUpDown_TiltUp" 2 "RqstTiltUpDown_RequestDown" 1 "RqstTiltUpDown_RequestUp" 0 "RqstTiltUpDown_NoRequest" ;
VAL_ 2499679296 LoadDistributionSelected 15 "LoadDistributionSelected_NotAvailable" 14 "LoadDistributionSelected_Error" 13 "LoadDistributionSelected_Reserved_05" 12 "LoadDistributionSelected_Reserved_04" 11 "LoadDistributionSelected_Reserved_03" 10 "LoadDistributionSelected_TractionHelp2" 9 "LoadDistributionSelected_StartingHelp2" 8 "LoadDistributionSelected_VariableAxleLoad" 7 "LoadDistributionSelected_NoLoadDistribution" 6 "LoadDistributionSelected_TractionHelpInterDiff" 5 "LoadDistributionSelected_StartingHelpInterDiff" 4 "LoadDistributionSelected_AlternativeLoad" 3 "LoadDistributionSelected_TractionHelp" 2 "LoadDistributionSelected_StartingHelp" 1 "LoadDistributionSelected_OptimisedTraction" 0 "LoadDistributionSelected_NormalLoad" ;
VAL_ 2499679296 PHTimerRqstAck_DayOfWeekRq 15 "DayOfWeekRq_NotAvailable" 14 "DayOfWeekRq_Error" 13 "DayOfWeekRq_Spare_7" 12 "DayOfWeekRq_Spare_6" 11 "DayOfWeekRq_Spare_5" 10 "DayOfWeekRq_Spare_4" 9 "DayOfWeekRq_Spare_3" 8 "DayOfWeekRq_Spare_2" 7 "DayOfWeekRq_NoDay" 6 "DayOfWeekRq_Sunday" 5 "DayOfWeekRq_Saturday" 4 "DayOfWeekRq_Friday" 3 "DayOfWeekRq_Thursday" 2 "DayOfWeekRq_Wednesday" 1 "DayOfWeekRq_Tuesday" 0 "DayOfWeekRq_Monday" ;
VAL_ 2499679296 LiftAxle1PositionStatus 7 "LiftAxlePositionStatus_NotAvailable" 6 "LiftAxlePositionStatus_Error" 5 "LiftAxlePositionStatus_Reserved_01" 4 "LiftAxlePositionStatus_Reserved" 3 "LiftAxlePositionStatus_Lifting" 2 "LiftAxlePositionStatus_Lowering" 1 "LiftAxlePositionStatus_Lifted" 0 "LiftAxlePositionStatus_Lowered" ;
VAL_ 2499679296 PHTimerRqstAck_CurrentOp 3 "CurrentOp_NotAvailable" 2 "CurrentOp_Disabled" 1 "CurrentOp_TemporaryStopped" 0 "CurrentOp_Running" ;
VAL_ 2499679296 LiftAxle2PositionStatus 7 "LiftAxlePositionStatus_NotAvailable" 6 "LiftAxlePositionStatus_Error" 5 "LiftAxlePositionStatus_Reserved_01" 4 "LiftAxlePositionStatus_Reserved" 3 "LiftAxlePositionStatus_Lifting" 2 "LiftAxlePositionStatus_Lowering" 1 "LiftAxlePositionStatus_Lifted" 0 "LiftAxlePositionStatus_Lowered" ;
VAL_ 2499679296 ParkingBrake_stat 3 "ParkingBrake_stat_NotAvailable" 2 "ParkingBrake_stat_Error" 1 "ParkingBrake_stat_ParkingBrakeActivated" 0 "ParkingBrake_stat_ParkingBrakeReleased" ;
VAL_ 2499679296 AudioMuteStat 7 "AudioMute_NotAvailable" 6 "AudioMute_ErrorIndication" 5 "AudioMute_Spare_03" 4 "AudioMute_Spare_02" 3 "AudioMute_Spare_01" 2 "AudioMute_Spare" 1 "AudioMute_Mute" 0 "AudioMute_Off" ;
VAL_ 2549186373 AudioSourceBtStreamAvailable 3 "FalseTrue_NotAvaiable" 2 "FalseTrue_Error" 1 "FalseTrue_True" 0 "FalseTrue_False" ;
VAL_ 2549186373 AudioSourceStatus2 15 "AudioSource_stat4bit_NotAvailable" 14 "AudioSource_stat4bit_Error" 13 "AudioSource_stat4bit_Spare7" 12 "AudioSource_stat4bit_Spare6" 11 "AudioSource_stat4bit_Spare5" 10 "AudioSource_stat4bit_Spare4" 9 "AudioSource_stat4bit_Spare3" 8 "AudioSource_stat4bit_Spare2" 7 "AudioSource_stat4bit_Spare1" 6 "AudioSource_stat4bit_BtStream" 5 "AudioSource_stat4bit_AUX1" 4 "AudioSource_stat4bit_IPOD" 3 "AudioSource_stat4bit_AUX2" 2 "AudioSource_stat4bit_USB" 1 "AudioSource_stat4bit_CD" 0 "AudioSource_stat4bit_Radio" ;
VAL_ 2549186373 AudioSourceUsbAvailable 3 "FalseTrue_NotAvaiable" 2 "FalseTrue_Error" 1 "FalseTrue_True" 0 "FalseTrue_False" ;
VAL_ 2549186373 AudioSourceCdAvailable 3 "FalseTrue_NotAvaiable" 2 "FalseTrue_Error" 1 "FalseTrue_True" 0 "FalseTrue_False" ;
VAL_ 2549186373 AudioSourceIpodAvailable 3 "FalseTrue_NotAvaiable" 2 "FalseTrue_Error" 1 "FalseTrue_True" 0 "FalseTrue_False" ;
VAL_ 2565904383 AlarmClockNotification_Stat 3 "AlarmClkStat_Spare" 2 "AlarmClkStat_NoUsed" 1 "AlarmClkStat_Active" 0 "AlarmClkStat_Inactive" ;
VAL_ 2565904383 AlarmClkAl_LECM_stat_Type 7 "AlarmClkType_NotAvailable" 6 "AlarmClkType_Error" 5 "AlarmClkType_Reserved_02" 4 "AlarmClkType_Reserved_01" 3 "AlarmClkType_Light" 2 "AlarmClkType_Radio" 1 "AlarmClkType_Buzzer" 0 "AlarmClkType_NoAudibleNotification" ;
VAL_ 2565904383 AlarmClkAl_LECM_stat_Stat 3 "AlarmClkStat2_Snoozed" 2 "AlarmClkStat2_Ringing" 1 "AlarmClkStat2_Active" 0 "AlarmClkStat2_Inactive" ;
VAL_ 2565904383 AlarmClockNotification_Type 7 "AlarmClkType_NotAvailable" 6 "AlarmClkType_Error" 5 "AlarmClkType_Reserved_02" 4 "AlarmClkType_Reserved_01" 3 "AlarmClkType_Light" 2 "AlarmClkType_Radio" 1 "AlarmClkType_Buzzer" 0 "AlarmClkType_NoAudibleNotification" ;
VAL_ 2565904383 ESCReqESC_CtrlTrimReq 7 "CtrlTrimReq_NotAvailable" 6 "CtrlTrimReq_Error" 5 "CtrlTrimReq_Spare_02" 4 "CtrlTrimReq_Spare_01" 3 "CtrlTrimReq_Spare" 2 "CtrlTrimReq_TrimRampDown" 1 "CtrlTrimReq_TrimRampUp" 0 "CtrlTrimReq_NoRamp" ;
VAL_ 2565904383 AlarmClkAl_LECM_stat_ID 127 "AlarmClkID_NotAvailable" 126 "AlarmClkID_Error" 10 "AlarmClkID_Alarm10" 9 "AlarmClkID_Alarm9" 8 "AlarmClkID_Alarm8" 7 "AlarmClkID_Alarm7" 6 "AlarmClkID_Alarm6" 5 "AlarmClkID_Alarm5" 4 "AlarmClkID_Alarm4" 3 "AlarmClkID_Alarm3" 2 "AlarmClkID_Alarm2" 1 "AlarmClkID_Alarm1" 0 "AlarmClkID_NotUsed" ;
VAL_ 2565904383 ESCReqESC_CtrlTrimMode 15 "CtrlTrimMode_NotAvailable" 14 "CtrlTrimMode_Error" 13 "CtrlTrimMode_Spare_08" 12 "CtrlTrimMode_Spare_07" 11 "CtrlTrimMode_Spare_06" 10 "CtrlTrimMode_Spare_05" 9 "CtrlTrimMode_Spare_04" 8 "CtrlTrimMode_Spare_03" 7 "CtrlTrimMode_Spare_02" 6 "CtrlTrimMode_Spare_01" 5 "CtrlTrimMode_Spare" 4 "CtrlTrimMode_MuddySiteEngineSpeedControl" 3 "CtrlTrimMode_AirManagementEngineSpeedControl" 2 "CtrlTrimMode_IdleAdjust" 1 "CtrlTrimMode_PTOEngineSpeedControl" 0 "CtrlTrimMode_NoRequest" ;
VAL_ 2565904383 ESCReqESC_CtrlTrimStat 7 "CtrlTrimStat_NotAvailable" 6 "CtrlTrimStat_Error" 5 "CtrlTrimStat_Spare_02" 4 "CtrlTrimStat_Spare_01" 3 "CtrlTrimStat_Spare" 2 "CtrlTrimStat_TrimActive" 1 "CtrlTrimStat_ControlActive" 0 "CtrlTrimStat_NoRequestActive" ;
VAL_ 2565904383 AlarmClkAl_LECM_stat_Mode 3 "AlarmClkMode_Spare" 2 "AlarmClkMode_Timer" 1 "AlarmClkMode_Recurrent" 0 "AlarmClkMode_OneTime" ;
VAL_ 2565904383 AlarmClockNotification_ID 127 "AlarmClkID_NotAvailable" 126 "AlarmClkID_Error" 10 "AlarmClkID_Alarm10" 9 "AlarmClkID_Alarm9" 8 "AlarmClkID_Alarm8" 7 "AlarmClkID_Alarm7" 6 "AlarmClkID_Alarm6" 5 "AlarmClkID_Alarm5" 4 "AlarmClkID_Alarm4" 3 "AlarmClkID_Alarm3" 2 "AlarmClkID_Alarm2" 1 "AlarmClkID_Alarm1" 0 "AlarmClkID_NotUsed" ;
VAL_ 2499755967 FdEquipmentStatus2 3 "InactiveActive_NotAvailable" 2 "InactiveActive_Error" 1 "InactiveActive_Active" 0 "InactiveActive_Inactive" ;
VAL_ 2499755967 RideHeightStatus 15 "RideHeightStatus_NotAvailable" 14 "RideHeightStatus_ErrorIndicator" 13 "RideHeightStatus_NotDefined_03" 12 "RideHeightStatus_NotDefined_02" 11 "RideHeightStatus_NotDefined_01" 10 "RideHeightStatus_NotDefined" 9 "RideHeightStatus_AlternativeDrivePosition2" 8 "RideHeightStatus_AlternativeDrivePosition1" 7 "RideHeightStatus_AlternativeDrivePosition" 6 "RideHeightStatus_HighDrivePosition" 5 "RideHeightStatus_LowDrivePosition" 4 "RideHeightStatus_SpeedDependentDrivePositionHighSpeed" 3 "RideHeightStatus_SpeedDependentDrivePositionLowSpeed" 2 "RideHeightStatus_StandardUserDrivePosition" 1 "RideHeightStatus_StandardFactoryDrivePosition" 0 "RideHeightStatus_Inactive" ;
VAL_ 2499755967 FdEquipmentStatus4 3 "InactiveActive_NotAvailable" 2 "InactiveActive_Error" 1 "InactiveActive_Active" 0 "InactiveActive_Inactive" ;
VAL_ 2499755967 RideHeightOutsideTargetRange 7 "HeightOutsideTargetRange_NotAvailable" 6 "HeightOutsideTargetRange_Error" 5 "HeightOutsideTargetRange_NotDefined_02" 4 "HeightOutsideTargetRange_NotDefined_01" 3 "HeightOutsideTargetRange_NotDefined" 2 "HeightOutsideTargetRange_ToHigh" 1 "HeightOutsideTargetRange_ToLow" 0 "HeightOutsideTargetRange_Inactive" ;
VAL_ 2499755967 FdEquipmentStatus1 3 "InactiveActive_NotAvailable" 2 "InactiveActive_Error" 1 "InactiveActive_Active" 0 "InactiveActive_Inactive" ;
VAL_ 2499755967 FdEquipmentStatus5 3 "InactiveActive_NotAvailable" 2 "InactiveActive_Error" 1 "InactiveActive_Active" 0 "InactiveActive_Inactive" ;
VAL_ 2499755967 RideHeightFunctionStatus 15 "RideHeightFunction_NotAvailable" 14 "RideHeightFunction_ErrorIndicator" 13 "RideHeightFunction_NotDefined_05" 12 "RideHeightFunction_NotDefined_04" 11 "RideHeightFunction_NotDefined_03" 10 "RideHeightFunction_NotDefined_02" 9 "RideHeightFunction_NotDefined_01" 8 "RideHeightFunction_NotDefined" 7 "RideHeightFunction_AlternativeDrivePosition2" 6 "RideHeightFunction_AlternativeDrivePosition1" 5 "RideHeightFunction_LowDrivePosition" 4 "RideHeightFunction_HighDrivePosition" 3 "RideHeightFunction_SpeedDependentDrivePosition" 2 "RideHeightFunction_AlternativeDrivePosition" 1 "RideHeightFunction_StandardDrivePosition" 0 "RideHeightFunction_Inactive" ;
VAL_ 2499755967 FdEquipmentStatus3 3 "InactiveActive_NotAvailable" 2 "InactiveActive_Error" 1 "InactiveActive_Active" 0 "InactiveActive_Inactive" ;
VAL_ 2499755967 FrontEndPositionStatus 7 "EndPositionStatus_NotAvailable" 6 "EndPositionStatus_Error" 5 "EndPositionStatus_Reserved_01" 4 "EndPositionStatus_Reserved" 3 "EndPositionStatus_LiftingAndLoweringNotAllowed" 2 "EndPositionStatus_MinEndLevelReached" 1 "EndPositionStatus_MaxEndLevelReached" 0 "EndPositionStatus_NoEndLevelReached" ;
VAL_ 2499755967 RollEndPositionStatus 7 "RollEndPositionStatus_NotAvailable" 6 "RollEndPositionStatus_Error" 5 "RollEndPositionStatus_Reserved_01" 4 "RollEndPositionStatus_Reserved" 3 "RollEndPositionStatus_NoRollingAllowed" 2 "RollEndPositionStatus_CounterClockwiseEndLevelReached" 1 "RollEndPositionStatus_ClockwiseEndLevelReached" 0 "RollEndPositionStatus_NoEndLevelReached" ;
VAL_ 2499755967 RampLevelStatus 15 "RampLevelStatus_NotAvaiable" 14 "RampLevelStatus_ErrorIndicator" 13 "RampLevelStatus_NotDefined_05" 12 "RampLevelStatus_NotDefined_04" 11 "RampLevelStatus_NotDefined_03" 10 "RampLevelStatus_NotDefined_02" 9 "RampLevelStatus_NotDefined_01" 8 "RampLevelStatus_NotDefined" 7 "RampLevelStatus_RampLevelM7" 6 "RampLevelStatus_RampLevelM6" 5 "RampLevelStatus_RampLevelM5" 4 "RampLevelStatus_RampLevelM4" 3 "RampLevelStatus_RampLevelM3" 2 "RampLevelStatus_RampLevelM2" 1 "RampLevelStatus_RampLevelM1" 0 "RampLevelStatus_Inactive" ;
VAL_ 2499755967 RampHeightOutsideTargetRange 7 "HeightOutsideTargetRange_NotAvailable" 6 "HeightOutsideTargetRange_Error" 5 "HeightOutsideTargetRange_NotDefined_02" 4 "HeightOutsideTargetRange_NotDefined_01" 3 "HeightOutsideTargetRange_NotDefined" 2 "HeightOutsideTargetRange_ToHigh" 1 "HeightOutsideTargetRange_ToLow" 0 "HeightOutsideTargetRange_Inactive" ;
VAL_ 2499755967 RearEndPositionStatus 7 "EndPositionStatus_NotAvailable" 6 "EndPositionStatus_Error" 5 "EndPositionStatus_Reserved_01" 4 "EndPositionStatus_Reserved" 3 "EndPositionStatus_LiftingAndLoweringNotAllowed" 2 "EndPositionStatus_MinEndLevelReached" 1 "EndPositionStatus_MaxEndLevelReached" 0 "EndPositionStatus_NoEndLevelReached" ;
VAL_ 2432687168 Pto1Status 3 "InactiveActive_NotAvailable" 2 "InactiveActive_Error" 1 "InactiveActive_Active" 0 "InactiveActive_Inactive" ;
VAL_ 2432687168 BodyOrCabWorkingLightFdbk_stat 3 "OffOn_NotAvailable" 2 "OffOn_Error" 1 "OffOn_On" 0 "OffOn_Off" ;
VAL_ 2432687168 ElectricalLoadReduction_rqst 7 "ElectricalLoadReduction_rqst_NotAvailable" 6 "ElectricalLoadReduction_rqst_Error" 5 "ElectricalLoadReduction_rqst_SpareValue_02" 4 "ElectricalLoadReduction_rqst_SpareValue_01" 3 "ElectricalLoadReduction_rqst_SpareValue" 2 "ElectricalLoadReduction_rqst_Level2Request" 1 "ElectricalLoadReduction_rqst_Level1Request" 0 "ElectricalLoadReduction_rqst_NoRequest" ;
VAL_ 2432687168 AirbagTelltale_stat 3 "OffOn_NotAvailable" 2 "OffOn_Error" 1 "OffOn_On" 0 "OffOn_Off" ;
VAL_ 2432687168 CabWrknLightChassisFdbk_stat 3 "OffOn_NotAvailable" 2 "OffOn_Error" 1 "OffOn_On" 0 "OffOn_Off" ;
VAL_ 2432687168 ExtraBBTailLiftStatus 3 "InactiveActive_NotAvailable" 2 "InactiveActive_Error" 1 "InactiveActive_Active" 0 "InactiveActive_Inactive" ;
VAL_ 2432687168 ExtraBBCraneStatus 7 "ExtraBBCraneStatus_NotAvailable" 6 "ExtraBBCraneStatus_Error" 5 "ExtraBBCraneStatus_Spare_02" 4 "ExtraBBCraneStatus_Spare_01" 3 "ExtraBBCraneStatus_Spare" 2 "ExtraBBCraneStatus_Active" 1 "ExtraBBCraneStatus_Enable" 0 "ExtraBBCraneStatus_Disable" ;
VAL_ 2432687168 Pto3Status 3 "InactiveActive_NotAvailable" 2 "InactiveActive_Error" 1 "InactiveActive_Active" 0 "InactiveActive_Inactive" ;
VAL_ 2432687168 AirBleedValveStat 3 "ClosedOpen_NotAvailable" 2 "ClosedOpen_Error" 1 "ClosedOpen_Open" 0 "ClosedOpen_Closed" ;
VAL_ 2432687168 CabExtraSideWrknLightFdbk_stat 3 "OffOn_NotAvailable" 2 "OffOn_Error" 1 "OffOn_On" 0 "OffOn_Off" ;
VAL_ 2432687168 Pto2Status 3 "InactiveActive_NotAvailable" 2 "InactiveActive_Error" 1 "InactiveActive_Active" 0 "InactiveActive_Inactive" ;
VAL_ 2432687168 CabBeaconLightFeedback_Status 3 "OffOn_NotAvailable" 2 "OffOn_Error" 1 "OffOn_On" 0 "OffOn_Off" ;
VAL_ 2432687168 AudioSourceStatus 7 "AudioSourceStatus_NotAvailable" 6 "AudioSourceStatus_Error" 5 "AudioSourceStatus_AUX1" 4 "AudioSourceStatus_iPod" 3 "AudioSourceStatus_AUX2" 2 "AudioSourceStatus_USB" 1 "AudioSourceStatus_CD" 0 "AudioSourceStatus_Radio" ;
VAL_ 2432687168 Pto4Status 3 "InactiveActive_NotAvailable" 2 "InactiveActive_Error" 1 "InactiveActive_Active" 0 "InactiveActive_Inactive" ;
VAL_ 2550121792 ParkingHeaterCleaning_cmd 3 "ParkingHeaterCleaning_cmd_NotAvailable" 2 "ParkingHeaterCleaning_cmd_Escaped" 1 "ParkingHeaterCleaning_cmd_Activated" 0 "ParkingHeaterCleaning_cmd_NoAction" ;
VAL_ 2550121792 LivBatteryCharging_stat 3 "NotConfirmedConfirmed_NotAvailable" 2 "NotConfirmedConfirmed_Error" 1 "NotConfirmedConfirmed_Confirmed" 0 "NotConfirmedConfirmed_NotConfirmed" ;
VAL_ 2550121792 BatterySOCAlertRawData_rqst 7 "BatterySOCAlert_rqst_NotAvailable" 6 "BatterySOCAlert_rqst_ErrorIndicator" 5 "BatterySOCAlert_rqst_SpareValue_02" 4 "BatterySOCAlert_rqst_SpareValue_01" 3 "BatterySOCAlert_rqst_SpareValue" 2 "BatterySOCAlert_rqst_CriticalAlert" 1 "BatterySOCAlert_rqst_PreAlert" 0 "BatterySOCAlert_rqst_NoAlertRequested" ;
SIG_GROUP_ 2432685120 UpdParkClimTimerRqst_sg 1 : UpdParkClimTimerRqst_TimerCmd UpdParkClimTimerRqst_TimRqst;
SIG_GROUP_ 2432663360 SetParkClimTimerRqst_sg 1 : SetParkClimTimerRqst_Sun SetParkClimTimerRqst_Dur SetParkClimTimerRqst_Tue SetParkClimTimerRqst_Temp SetParkClimTimerRqst_TimerCmd SetParkClimTimerRqst_Hrs SetParkClimTimerRqst_Wed SetParkClimTimerRqst_Type SetParkClimTimerRqst_Mon SetParkClimTimerRqst_Fri SetParkClimTimerRqst_TimerNr SetParkClimTimerRqst_Sat SetParkClimTimerRqst_Rec SetParkClimTimerRqst_Thu SetParkClimTimerRqst_Min;
SIG_GROUP_ 2566357312 GPSData_sg 1 : GPSData_VehSpeed GPSData_HDOP GPSData_Direction GPSData_Longitude GPSData_AntennaStat GPSData_Latitude GPSData_Altitude GPSData_Time;
SIG_GROUP_ 2432679744 MediaSourcesListRsp_sg 1 : MediaSourcesListRsp_SrcAttrib MediaSourcesListRsp_ItemID MediaSourcesListRsp_Name MediaSourcesListRsp_SInfo MediaSourcesListRsp_PCI;
SIG_GROUP_ 2493989952 SEMMediaSourceAvail_sg 1 : SEMMediaSourceAvail_Source07 SEMMediaSourceAvail_Source06 SEMMediaSourceAvail_Source08 SEMMediaSourceAvail_Source00 SEMMediaSourceAvail_Source09 SEMMediaSourceAvail_Source13 SEMMediaSourceAvail_Source04 SEMMediaSourceAvail_Source05 SEMMediaSourceAvail_Source02 SEMMediaSourceAvail_SInfo SEMMediaSourceAvail_Source11 SEMMediaSourceAvail_Source10 SEMMediaSourceAvail_Source01 SEMMediaSourceAvail_Source03 SEMMediaSourceAvail_Source12;
SIG_GROUP_ 2499679296 PHTimerRqstAck_sg 1 : PHTimerRqstAck_Hours PHTimerRqstAck_DayOfWeekRq PHTimerRqstAck_Minutes PHTimerRqstAck_CurrentOp;
SIG_GROUP_ 2565904383 ESCReqESC_sg 1 : ESCReqESC_CtrlTrimValue ESCReqESC_CtrlTrimReq ESCReqESC_CtrlTrimMode ESCReqESC_CtrlTrimStat;
SIG_GROUP_ 2565904383 AlarmClockNotification_sg 1 : AlarmClockNotification_Stat AlarmClockNotification_Type AlarmClockNotification_ID;
SIG_GROUP_ 2565904383 AlarmClkAl_LECM_stat_sg 1 : AlarmClkAl_LECM_stat_SetHr AlarmClkAl_LECM_stat_Type AlarmClkAl_LECM_stat_Stat AlarmClkAl_LECM_stat_DaySet AlarmClkAl_LECM_stat_ID AlarmClkAl_LECM_stat_SetMin AlarmClkAl_LECM_stat_Mode;
